VERSION "HNNBNNNYNNNNNNNNNNNNNNNNNNNNNNNNNNNNNNNNNN/4/%%%/4/'%**4NNN///"

NS_ :

BS_:

BU_: Airbag_D4 EPB_D4 ESP_D4 Gateway_D4C7 Getriebe_AL551_951_D4_C7 Getriebe_DL501_C7 Getriebe_VL381_C7 LWS_D4 Motor_EDC17_D4 Motor_ME17_BY Motor_MED17_SIMOS8_D4 Motor_Slave_D4 QSP_D4 SAK_C7 SCR_C7 SCU_D4

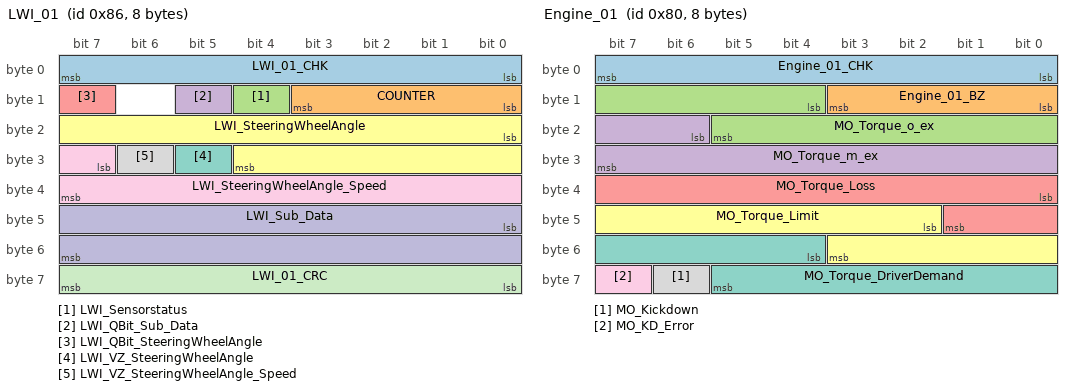
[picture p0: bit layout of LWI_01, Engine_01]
BO_ 134 LWI_01: 8 LWS_D4
 SG_ LWI_01_CHK : 0|8@1+ (1,0) [0|255] ""  ESP_D4,Gateway_D4C7,Getriebe_AL551_951_D4_C7,Getriebe_DL501_C7,Getriebe_VL381_C7,Motor_EDC17_D4,Motor_ME17_BY,Motor_MED17_SIMOS8_D4,QSP_D4,SCU_D4
 SG_ COUNTER : 8|4@1+ (1,0) [0|15] ""  Airbag_D4,ESP_D4,Gateway_D4C7,Getriebe_AL551_951_D4_C7,Getriebe_DL501_C7,Getriebe_VL381_C7,Motor_EDC17_D4,Motor_ME17_BY,Motor_MED17_SIMOS8_D4,QSP_D4,SCU_D4
 SG_ LWI_Sensorstatus : 12|1@1+ (1.0,0.0) [0.0|1] ""  ESP_D4,Gateway_D4C7,Getriebe_AL551_951_D4_C7,Motor_EDC17_D4,Motor_ME17_BY,Motor_MED17_SIMOS8_D4,QSP_D4,SCU_D4
 SG_ LWI_QBit_Sub_Data : 13|1@1+ (1.0,0.0) [0.0|1] ""  ESP_D4,Gateway_D4C7,QSP_D4,SCU_D4
 SG_ LWI_QBit_SteeringWheelAngle : 15|1@1+ (1.0,0.0) [0.0|1] ""  Airbag_D4,ESP_D4,Gateway_D4C7,Getriebe_AL551_951_D4_C7,Motor_EDC17_D4,Motor_ME17_BY,Motor_MED17_SIMOS8_D4,QSP_D4,SCU_D4
 SG_ LWI_SteeringWheelAngle : 16|13@1+ (0.1,0) [0.0|800.0] "Unit_DegreOfArc"  Airbag_D4,ESP_D4,Gateway_D4C7,Getriebe_AL551_951_D4_C7,Getriebe_DL501_C7,Getriebe_VL381_C7,Motor_EDC17_D4,Motor_ME17_BY,Motor_MED17_SIMOS8_D4,QSP_D4,SCU_D4
 SG_ LWI_VZ_SteeringWheelAngle : 29|1@1+ (1.0,0.0) [0.0|1] ""  Airbag_D4,ESP_D4,Gateway_D4C7,Getriebe_AL551_951_D4_C7,Motor_EDC17_D4,Motor_ME17_BY,Motor_MED17_SIMOS8_D4,QSP_D4,SCU_D4
 SG_ LWI_VZ_SteeringWheelAngle_Speed : 30|1@1+ (1.0,0.0) [0.0|1] ""  Gateway_D4C7,QSP_D4
 SG_ LWI_SteeringWheelAngle_Speed : 31|9@1+ (5,0) [0|2500] "Unit_DegreOfArcPerSecon"  Gateway_D4C7,QSP_D4
 SG_ LWI_Sub_Data : 40|16@1+ (1,0) [0|65535] ""  ESP_D4,Gateway_D4C7,QSP_D4,SCU_D4
 SG_ LWI_01_CRC : 56|8@1+ (1,0) [0|255] ""  Airbag_D4,ESP_D4,Gateway_D4C7,QSP_D4,SCU_D4

BO_ 128 Engine_01: 8 Motor_EDC17_D4
 SG_ Engine_01_CHK : 0|8@1+ (1,0) [0|255] ""  EPB_D4,Gateway_D4C7,Getriebe_AL551_951_D4_C7,Getriebe_DL501_C7,Getriebe_VL381_C7
 SG_ Engine_01_BZ : 8|4@1+ (1,0) [0|15] ""  EPB_D4,Gateway_D4C7,Getriebe_AL551_951_D4_C7,Getriebe_DL501_C7,Getriebe_VL381_C7
 SG_ MO_Torque_o_ex : 12|10@1+ (1,0) [0|1021] ""  Gateway_D4C7,Getriebe_AL551_951_D4_C7,Getriebe_DL501_C7,Getriebe_VL381_C7
 SG_ MO_Torque_m_ex : 22|10@1+ (1,0) [0|1021] ""  EPB_D4,Gateway_D4C7,Getriebe_AL551_951_D4_C7,Getriebe_DL501_C7,Getriebe_VL381_C7,SAK_C7
 SG_ MO_Torque_Loss : 32|10@1+ (1,0) [0|1021] ""  EPB_D4,Gateway_D4C7,Getriebe_AL551_951_D4_C7,Getriebe_DL501_C7,Getriebe_VL381_C7,SAK_C7
 SG_ MO_Torque_Limit : 42|10@1+ (1,0) [0|1021] ""  Gateway_D4C7,Getriebe_AL551_951_D4_C7,Getriebe_DL501_C7,Getriebe_VL381_C7
 SG_ MO_Torque_DriverDemand : 52|10@1+ (1,0) [0|1021] ""  Gateway_D4C7,Getriebe_AL551_951_D4_C7,Getriebe_DL501_C7,Getriebe_VL381_C7
 SG_ MO_Kickdown : 62|1@1+ (1.0,0.0) [0.0|1] ""  Gateway_D4C7,Getriebe_AL551_951_D4_C7,Getriebe_DL501_C7,Getriebe_VL381_C7
 SG_ MO_KD_Error : 63|1@1+ (1.0,0.0) [0.0|1] ""  Gateway_D4C7

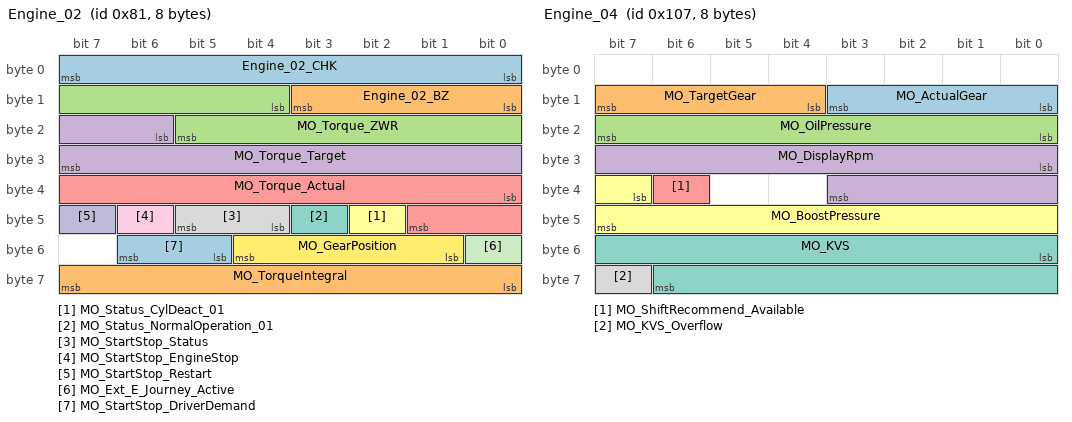
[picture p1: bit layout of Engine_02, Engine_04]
BO_ 129 Engine_02: 8 Motor_EDC17_D4
 SG_ Engine_02_CHK : 0|8@1+ (1,0) [0|255] ""  EPB_D4,Gateway_D4C7,Getriebe_AL551_951_D4_C7,Getriebe_DL501_C7,Getriebe_VL381_C7,SCU_D4
 SG_ Engine_02_BZ : 8|4@1+ (1,0) [0|15] ""  EPB_D4,Gateway_D4C7,Getriebe_AL551_951_D4_C7,Getriebe_DL501_C7,Getriebe_VL381_C7,SCU_D4
 SG_ MO_Torque_ZWR : 12|10@1+ (1,0) [0|1021] ""  Gateway_D4C7
 SG_ MO_Torque_Target : 22|10@1+ (1,0) [0|1021] ""  Gateway_D4C7,Getriebe_AL551_951_D4_C7,Getriebe_DL501_C7,Getriebe_VL381_C7
 SG_ MO_Torque_Actual : 32|10@1+ (1,0) [0|1021] ""  Gateway_D4C7,Getriebe_AL551_951_D4_C7,Getriebe_DL501_C7,Getriebe_VL381_C7
 SG_ MO_Status_CylDeact_01 : 42|1@1+ (1.0,0.0) [0.0|1] ""  Gateway_D4C7,Getriebe_AL551_951_D4_C7
 SG_ MO_Status_NormalOperation_01 : 43|1@1+ (1.0,0.0) [0.0|1] ""  Gateway_D4C7,Getriebe_DL501_C7,Getriebe_VL381_C7
 SG_ MO_StartStop_Status : 44|2@1+ (1.0,0.0) [0.0|3] ""  Gateway_D4C7,Getriebe_AL551_951_D4_C7,Getriebe_DL501_C7,Getriebe_VL381_C7,SCR_C7,SCU_D4
 SG_ MO_StartStop_EngineStop : 46|1@1+ (1.0,0.0) [0.0|1] ""  EPB_D4,Gateway_D4C7,Getriebe_AL551_951_D4_C7,Getriebe_DL501_C7,Getriebe_VL381_C7,SCR_C7,SCU_D4
 SG_ MO_StartStop_Restart : 47|1@1+ (1.0,0.0) [0.0|1] ""  EPB_D4,Gateway_D4C7,Getriebe_AL551_951_D4_C7,Getriebe_DL501_C7,Getriebe_VL381_C7,SCR_C7,SCU_D4
 SG_ MO_Ext_E_Journey_Active : 48|1@1+ (1.0,0.0) [0.0|1] ""  Gateway_D4C7
 SG_ MO_GearPosition : 49|4@1+ (1.0,0.0) [0.0|15] ""  Gateway_D4C7
 SG_ MO_StartStop_DriverDemand : 53|2@1+ (1.0,0.0) [0.0|3] ""  Gateway_D4C7
 SG_ MO_TorqueIntegral : 56|8@1+ (0.3921,0) [0.0000|99.9855] ""  Gateway_D4C7,Getriebe_AL551_951_D4_C7,Getriebe_DL501_C7,Getriebe_VL381_C7

BO_ 261 Engine_03: 8 Motor_EDC17_D4
 SG_ Engine_03_CHK : 0|8@1+ (1,0) [0|255] ""  EPB_D4,Gateway_D4C7,Getriebe_AL551_951_D4_C7,Getriebe_DL501_C7,Getriebe_VL381_C7,SCU_D4
 SG_ COUNTER : 8|4@1+ (1,0) [0|15] ""  EPB_D4,Gateway_D4C7,Getriebe_AL551_951_D4_C7,Getriebe_DL501_C7,Getriebe_VL381_C7,SCU_D4
 SG_ MO_QBit_AccelPedalValues_01 : 12|1@1+ (1.0,0.0) [0.0|1] ""  EPB_D4,Gateway_D4C7,Getriebe_AL551_951_D4_C7,Getriebe_DL501_C7,Getriebe_VL381_C7
 SG_ MO_QBit_EngineTorques : 13|1@1+ (1.0,0.0) [0.0|1] ""  EPB_D4,Gateway_D4C7,Getriebe_AL551_951_D4_C7,Getriebe_DL501_C7,Getriebe_VL381_C7
 SG_ MO_QBit_Driver_Brakes : 14|1@1+ (1.0,0.0) [0.0|1] ""  Gateway_D4C7,Getriebe_AL551_951_D4_C7,Getriebe_DL501_C7,Getriebe_VL381_C7
 SG_ MO_QBit_Rpm_01 : 15|1@1+ (1.0,0.0) [0.0|1] ""  EPB_D4,Gateway_D4C7,Getriebe_AL551_951_D4_C7,Getriebe_DL501_C7,Getriebe_VL381_C7,SCR_C7
 SG_ MO_Rpm_01 : 16|16@1+ (0.25,0) [0.00|16383.00] "Unit_MinutInver"  EPB_D4,Gateway_D4C7,Getriebe_AL551_951_D4_C7,Getriebe_DL501_C7,Getriebe_VL381_C7,SAK_C7,SCR_C7,SCU_D4
 SG_ MO_Torque_In_Idle : 32|1@1+ (1.0,0.0) [0.0|1] ""  Gateway_D4C7
 SG_ MO_Interlock : 33|1@1+ (1.0,0.0) [0.0|1] ""  EPB_D4,Gateway_D4C7
 SG_ MO_BLS : 34|1@1+ (1.0,0.0) [0.0|1] ""  EPB_D4,Gateway_D4C7,Getriebe_AL551_951_D4_C7,Getriebe_DL501_C7,Getriebe_VL381_C7
 SG_ MO_Driver_Brakes : 35|1@1+ (1.0,0.0) [0.0|1] ""  Gateway_D4C7,Getriebe_AL551_951_D4_C7,Getriebe_DL501_C7,Getriebe_VL381_C7
 SG_ MO_Consistency_BrakePedal : 36|1@1+ (1.0,0.0) [0.0|1] ""  Gateway_D4C7,Getriebe_AL551_951_D4_C7,Getriebe_DL501_C7,Getriebe_VL381_C7
 SG_ MO_Clutch_Switch : 37|1@1+ (1.0,0.0) [0.0|1] ""  EPB_D4,Gateway_D4C7
 SG_ MO_Timeout_ESP : 38|1@1+ (1.0,0.0) [0.0|1] ""  Gateway_D4C7
 SG_ MO_Engine_Running : 39|1@1+ (1.0,0.0) [0.0|1] ""  Gateway_D4C7
 SG_ MO_TargetRpm_Idle : 40|8@1+ (10,0) [0|2540] "Unit_MinutInver"  Gateway_D4C7,Getriebe_AL551_951_D4_C7,Getriebe_DL501_C7,Getriebe_VL381_C7
 SG_ MO_AccelPedalRaw_01 : 48|8@1+ (0.4,0) [0.0|101.6] "Unit_PerCent"  EPB_D4,Gateway_D4C7,Getriebe_AL551_951_D4_C7,Getriebe_DL501_C7,Getriebe_VL381_C7
 SG_ MO_First_InaccurateThreshold : 56|1@1+ (1.0,0.0) [0.0|1] ""  Gateway_D4C7,Getriebe_AL551_951_D4_C7,Getriebe_DL501_C7,Getriebe_VL381_C7
 SG_ MO_QBit_Stressfaktor : 57|1@1+ (1.0,0.0) [0.0|1] ""  Gateway_D4C7,Getriebe_AL551_951_D4_C7,Getriebe_DL501_C7,Getriebe_VL381_C7
 SG_ MO_Stressfaktor : 58|6@1+ (1.6,0) [0.0|100.8] "Unit_PerCent"  Gateway_D4C7,Getriebe_AL551_951_D4_C7,Getriebe_DL501_C7,Getriebe_VL381_C7

BO_ 263 Engine_04: 8 Motor_EDC17_D4
 SG_ MO_ActualGear : 8|4@1+ (1.0,0.0) [0.0|15] ""  Gateway_D4C7
 SG_ MO_TargetGear : 12|4@1+ (1.0,0.0) [0.0|15] ""  Gateway_D4C7
 SG_ MO_OilPressure : 16|8@1+ (0.04,0) [0.00|10.00] "Unit_Bar"  Gateway_D4C7
 SG_ MO_DisplayRpm : 24|12@1+ (3,0) [0|12282] "Unit_MinutInver"  Gateway_D4C7
 SG_ MO_ShiftRecommend_Available : 38|1@1+ (1.0,0.0) [0.0|1] ""  Gateway_D4C7
 SG_ MO_BoostPressure : 39|9@1+ (0.01,0) [0.00|5.10] "Unit_Bar"  Gateway_D4C7
 SG_ MO_KVS : 48|15@1+ (1,0) [0|32767] "Unit_MicroLiter"  Gateway_D4C7
 SG_ MO_KVS_Overflow : 63|1@1+ (1.0,0.0) [0.0|1] ""  Gateway_D4C7

BO_ 782 Engine_05: 8 Motor_EDC17_D4
 SG_ Engine_05_CHK : 0|8@1+ (1,0) [0|255] ""  Gateway_D4C7,Getriebe_AL551_951_D4_C7,Getriebe_DL501_C7,Getriebe_VL381_C7
 SG_ Engine_05_BZ : 8|4@1+ (1,0) [0|15] ""  Gateway_D4C7,Getriebe_AL551_951_D4_C7,Getriebe_DL501_C7,Getriebe_VL381_C7
 SG_ MO_ETermCommLeiRed : 12|2@1+ (1.0,0.0) [0.0|3] ""  Gateway_D4C7
 SG_ MO_Enable_Recup : 14|2@1+ (1.0,0.0) [0.0|3] ""  Gateway_D4C7
 SG_ MO_Climate_Interv : 16|2@1+ (1.0,0.0) [0.0|3] ""  Gateway_D4C7
 SG_ MO_Status_NormalOperation_02 : 18|1@1+ (1.0,0.0) [0.0|1] ""  Gateway_D4C7
 SG_ MO_ShiftInfluence_PowerLimit : 19|1@1+ (1,0) [0|1] ""  Gateway_D4C7,Getriebe_AL551_951_D4_C7,Getriebe_DL501_C7
 SG_ MO_ShiftInfluence_ParticleFilter : 20|1@1+ (1,0) [0|1] ""  Gateway_D4C7,Getriebe_AL551_951_D4_C7,Getriebe_DL501_C7
 SG_ MO_Prio_MIN_RequestedRpm : 21|1@1+ (1.0,0.0) [0.0|1] ""  Gateway_D4C7,Getriebe_AL551_951_D4_C7,Getriebe_DL501_C7,Getriebe_VL381_C7
 SG_ MO_Enable_Crank : 22|1@1+ (1.0,0.0) [0.0|1] ""  Gateway_D4C7
 SG_ MO_Aussp_Crank : 23|1@1+ (1.0,0.0) [0.0|1] ""  Gateway_D4C7
 SG_ MO_MAX_RequestedRpm : 24|9@1+ (25,0) [0|12750] "Unit_MinutInver"  Gateway_D4C7,Getriebe_AL551_951_D4_C7,Getriebe_DL501_C7,Getriebe_VL381_C7
 SG_ MO_Prio_MAX_RequestedRpm : 33|1@1+ (1.0,0.0) [0.0|1] ""  Gateway_D4C7,Getriebe_AL551_951_D4_C7,Getriebe_DL501_C7,Getriebe_VL381_C7
 SG_ MO_AirPath_Active : 34|1@1+ (1.0,0.0) [0.0|1] ""  Gateway_D4C7,Getriebe_AL551_951_D4_C7,Getriebe_DL501_C7
 SG_ MO_v_Limit_Active : 35|1@1+ (1.0,0.0) [0.0|1] ""  Gateway_D4C7
 SG_ MO_v_Limit_Activatable : 36|1@1+ (1.0,0.0) [0.0|1] ""  Gateway_D4C7
 SG_ MO_Inhibit_EKP : 37|1@1+ (1.0,0.0) [0.0|1] ""  Gateway_D4C7
 SG_ MO_Req_Pruefimpuls : 38|1@1+ (1.0,0.0) [0.0|1] ""  Gateway_D4C7
 SG_ MO_Req_TERM75 : 39|1@1+ (1.0,0.0) [0.0|1] ""  Gateway_D4C7
 SG_ MO_Charisma_DrivePr : 40|3@1+ (1.0,0.0) [0.0|7] ""  Gateway_D4C7
 SG_ MO_Charisma_Status : 43|2@1+ (1.0,0.0) [0.0|3] ""  Gateway_D4C7
 SG_ MO_Charisma_Changeover : 45|2@1+ (1.0,0.0) [0.0|3] ""  Gateway_D4C7
 SG_ MO_Handshake_STH : 47|1@1+ (1.0,0.0) [0.0|1] ""  Gateway_D4C7
 SG_ MO_MIN_RequestedRpm : 48|8@1+ (25,0) [0|6350] "Unit_MinutInver"  Gateway_D4C7,Getriebe_AL551_951_D4_C7,Getriebe_DL501_C7,Getriebe_VL381_C7
 SG_ MO_RpmInfluence : 56|8@1+ (0.39,0) [0.00|99.45] "Unit_PerCent"  Gateway_D4C7,Getriebe_AL551_951_D4_C7,Getriebe_DL501_C7,Getriebe_VL381_C7

BO_ 1088 Engine_06: 8 Motor_EDC17_D4
 SG_ MO_RadiatorFan_MUX M  : 0|1@1+ (1.0,0.0) [0.0|1] ""  Gateway_D4C7
 SG_ MO_RadiatorFan_1 m0  : 1|7@1+ (1,0) [0|100] "Unit_PerCent"  Gateway_D4C7
 SG_ MO_RadiatorFan_2 m1  : 1|7@1+ (1,0) [0|100] "Unit_PerCent"  Gateway_D4C7
 SG_ MO_HYB_Status_HV_Charge : 8|3@1+ (1.0,0.0) [0.0|7] ""  Gateway_D4C7
 SG_ WIV_Display_Active : 12|1@1+ (1.0,0.0) [0.0|1] ""  Gateway_D4C7
 SG_ WIV_Oelmin_Warn : 13|1@1+ (1.0,0.0) [0.0|1] ""  Gateway_D4C7
 SG_ WIV_SensorError : 14|1@1+ (1.0,0.0) [0.0|1] ""  Gateway_D4C7
 SG_ WIV_Tilt : 15|1@1+ (1.0,0.0) [0.0|1] ""  Gateway_D4C7
 SG_ WIV_OilLevel : 16|4@1+ (12.5,0) [0.0|100.0] "Unit_PerCent"  Gateway_D4C7
 SG_ MO_State_HWP : 20|2@1+ (1.0,0.0) [0.0|3] ""  Gateway_D4C7
 SG_ WIV_OilSystem_Active : 24|1@1+ (1.0,0.0) [0.0|1] ""  Gateway_D4C7
 SG_ WIV_Not_AtOperatingTemp : 25|1@1+ (1.0,0.0) [0.0|1] ""  Gateway_D4C7
 SG_ WIV_Overfill_Warn : 26|1@1+ (1.0,0.0) [0.0|1] ""  Gateway_D4C7
 SG_ WIV_Running_Engine : 27|1@1+ (1.0,0.0) [0.0|1] ""  Gateway_D4C7
 SG_ MO_HYB_Text_1 : 28|1@1+ (1.0,0.0) [0.0|1] ""  Gateway_D4C7
 SG_ MO_HYB_Text_2 : 29|1@1+ (1.0,0.0) [0.0|1] ""  Gateway_D4C7
 SG_ MO_HYB_Text_3 : 30|1@1+ (1.0,0.0) [0.0|1] ""  Gateway_D4C7
 SG_ MO_Text_EngineStart : 32|4@1+ (1.0,0.0) [0.0|15] ""  Gateway_D4C7
 SG_ MO_HYB_Text_5 : 36|1@1+ (1.0,0.0) [0.0|1] ""  Gateway_D4C7
 SG_ MO_HYB_Text_6 : 37|1@1+ (1.0,0.0) [0.0|1] ""  Gateway_D4C7
 SG_ MO_HYB_Text_7 : 38|1@1+ (1.0,0.0) [0.0|1] ""  Gateway_D4C7
 SG_ WIV_OilDyn_avl : 39|1@1+ (1.0,0.0) [0.0|1] ""  Gateway_D4C7
 SG_ MO_Text_MSG_Workshop : 40|1@1+ (1,0) [0|1] ""  Gateway_D4C7
 SG_ MO_Text_ParticleFilter_Reg : 41|1@1+ (1,0) [0|1] ""  Gateway_D4C7
 SG_ MO_Text_Error_Kraftstoffsys : 42|1@1+ (1,0) [0|1] ""  Gateway_D4C7
 SG_ WIV_OilQuantity : 43|5@1+ (125,0) [0|3875] "Unit_MilliLiter"  Gateway_D4C7
 SG_ MO_SystemLamp : 48|1@1+ (1.0,0.0) [0.0|1] ""  Gateway_D4C7
 SG_ MO_OBD2_Lamp : 49|1@1+ (1.0,0.0) [0.0|1] ""  Gateway_D4C7
 SG_ MO_HotWarningLamp : 50|1@1+ (1.0,0.0) [0.0|1] ""  Gateway_D4C7
 SG_ MO_Particle_Lamp : 51|1@1+ (1.0,0.0) [0.0|1] ""  Gateway_D4C7
 SG_ MO_WinterProgram : 52|1@1+ (1,0) [0|1] ""  Gateway_D4C7
 SG_ WIV_OilLevel_Not_Present : 53|1@1+ (1.0,0.0) [0.0|1] ""  Gateway_D4C7
 SG_ WIV_RefillDisplay_On : 54|1@1+ (1.0,0.0) [0.0|1] ""  Gateway_D4C7
 SG_ WIV_Overfill_Deactivated : 55|1@1+ (1.0,0.0) [0.0|1] ""  Gateway_D4C7
 SG_ WIV_Underfill_Warn : 56|1@1+ (1.0,0.0) [0.0|1] ""  Gateway_D4C7
 SG_ MO_FuelCap_Lamp : 57|1@1+ (1.0,0.0) [0.0|1] ""  Gateway_D4C7
 SG_ MO_Text_FuelCapWarn : 58|1@1+ (1.0,0.0) [0.0|1] ""  Gateway_D4C7
 SG_ WIV_Enable_OilPressure_Engine : 59|1@1+ (1.0,0.0) [0.0|1] ""  Gateway_D4C7
 SG_ WIV_OilPressure_Warn_Engine : 60|1@1+ (1.0,0.0) [0.0|1] ""  Gateway_D4C7
 SG_ MO_Avus_EngineProtection : 61|2@1+ (1.0,0.0) [0.0|3] ""  Gateway_D4C7
 SG_ MO_HYB_ReadyToDrive : 63|1@1+ (1.0,0.0) [0.0|1] ""  Gateway_D4C7

BO_ 1600 Engine_07: 8 Motor_EDC17_D4
 SG_ MO_QBit_IntakeAir_Temp : 0|1@1+ (1.0,0.0) [0.0|1] ""  Gateway_D4C7,Getriebe_AL551_951_D4_C7,Getriebe_DL501_C7,Getriebe_VL381_C7
 SG_ MO_QBit_Oil_Temp : 1|1@1+ (1.0,0.0) [0.0|1] ""  Gateway_D4C7,Getriebe_AL551_951_D4_C7
 SG_ MO_QBit_Coolant_Temp : 2|1@1+ (1.0,0.0) [0.0|1] ""  Gateway_D4C7,Getriebe_AL551_951_D4_C7,Getriebe_DL501_C7,Getriebe_VL381_C7
 SG_ MO_ActuatorTest_SoundActuator : 3|1@1+ (1.0,0.0) [0.0|1] ""  Gateway_D4C7
 SG_ MO_HYB_Error_HV_Network : 4|1@1+ (1.0,0.0) [0.0|1] ""  Gateway_D4C7
 SG_ MO_Active_GearboxHeat : 5|1@1+ (1.0,0.0) [0.0|1] ""  Gateway_D4C7,Getriebe_AL551_951_D4_C7,Getriebe_DL501_C7,Getriebe_VL381_C7
 SG_ MO_ShutOffValve_Open : 6|2@1+ (1.0,0.0) [0.0|3] ""  Gateway_D4C7
 SG_ MO_IntakeAir_Temp : 8|8@1+ (0.75,-48) [-48.00|141.75] "Unit_DegreCelsi"  Gateway_D4C7,Getriebe_AL551_951_D4_C7,Getriebe_DL501_C7,Getriebe_VL381_C7
 SG_ MO_Oil_Temp : 16|8@1+ (1,-60) [-60|192] "Unit_DegreCelsi"  Gateway_D4C7,Getriebe_AL551_951_D4_C7
 SG_ MO_Coolant_Temp : 24|8@1+ (0.75,-48) [-48.00|141.75] "Unit_DegreCelsi"  Gateway_D4C7,Getriebe_AL551_951_D4_C7,Getriebe_DL501_C7,Getriebe_VL381_C7
 SG_ MO_AltitudeInfo : 32|8@1+ (0.00781,0) [0.00000|1.98374] ""  Gateway_D4C7,Getriebe_AL551_951_D4_C7,Getriebe_DL501_C7,Getriebe_VL381_C7
 SG_ MO_Kennfeldk : 40|1@1+ (1.0,0.0) [0.0|1] ""  Gateway_D4C7
 SG_ MO_VersionInfo : 41|6@1+ (1.0,0.0) [0.0|63] ""  Gateway_D4C7
 SG_ MO_Gearbox_Cool : 47|1@1+ (1.0,0.0) [0.0|1] ""  Gateway_D4C7,Getriebe_AL551_951_D4_C7,Getriebe_DL501_C7,Getriebe_VL381_C7
 SG_ MO_Torque_Inertia_02 : 48|5@1+ (0.01,0) [0.00|0.31] "Unit_KiloGramMeterSquar"  Gateway_D4C7,Getriebe_AL551_951_D4_C7,Getriebe_DL501_C7,Getriebe_VL381_C7
 SG_ MO_HeatingPumpActuation : 53|4@1+ (10,0) [0|100] "Unit_PerCent"  Gateway_D4C7
 SG_ MO_VoltageReq : 57|1@1+ (1.0,0.0) [0.0|1] ""  Gateway_D4C7
 SG_ MO_RunOnTime_HeatingPump : 58|6@1+ (15,0) [0|945] "Unit_Secon"  Gateway_D4C7

BO_ 1607 Engine_09: 8 Motor_EDC17_D4
 SG_ MO_ITM_Coolant_Temp : 0|8@1+ (0.75,-48) [-45.75|143.25] "Unit_DegreCelsi"  Gateway_D4C7
 SG_ MO_E85_Sensor : 8|4@1+ (10,0) [0|100] "Unit_PerCent"  Gateway_D4C7
 SG_ SCR_Disp_Motorstarts : 12|4@1+ (1,0) [0|8] ""  Gateway_D4C7
 SG_ SCR_Range : 16|15@1+ (1,0) [0|32766] ""  Gateway_D4C7
 SG_ SCR_WarningLevel_1 : 32|1@1+ (1.0,0.0) [0.0|1] ""  Gateway_D4C7
 SG_ SCR_WarningLevel_2 : 33|1@1+ (1.0,0.0) [0.0|1] ""  Gateway_D4C7
 SG_ SCR_Text : 34|3@1+ (1.0,0.0) [0.0|7] ""  Gateway_D4C7
 SG_ SCR_Acoustic : 37|2@1+ (1.0,0.0) [0.0|3] ""  Gateway_D4C7
 SG_ MO_Kraftstofffilter_Water : 40|1@1+ (1.0,0.0) [0.0|1] ""  Gateway_D4C7
 SG_ SCR_SystemError : 41|1@1+ (1.0,0.0) [0.0|1] ""  Gateway_D4C7
 SG_ SCR_Inducement_Strategy : 42|2@1+ (1.0,0.0) [0.0|3] ""  Gateway_D4C7
 SG_ MO_CO2_Factor : 44|12@1+ (1,0) [1|4094] "Unit_GramPerLiter"  Gateway_D4C7
 SG_ MO_MKB_MUX M  : 56|2@1+ (1.0,0.0) [0.0|3] ""  Gateway_D4C7
 SG_ MO_MKB_01 m0  : 59|5@1+ (1.0,0.0) [0.0|31] ""  Gateway_D4C7
 SG_ MO_MKB_02 m1  : 59|5@1+ (1.0,0.0) [0.0|31] ""  Gateway_D4C7
 SG_ MO_MKB_03 m2  : 59|5@1+ (1.0,0.0) [0.0|31] ""  Gateway_D4C7
 SG_ MO_MKB_04 m3  : 59|5@1+ (1.0,0.0) [0.0|31] ""  Gateway_D4C7

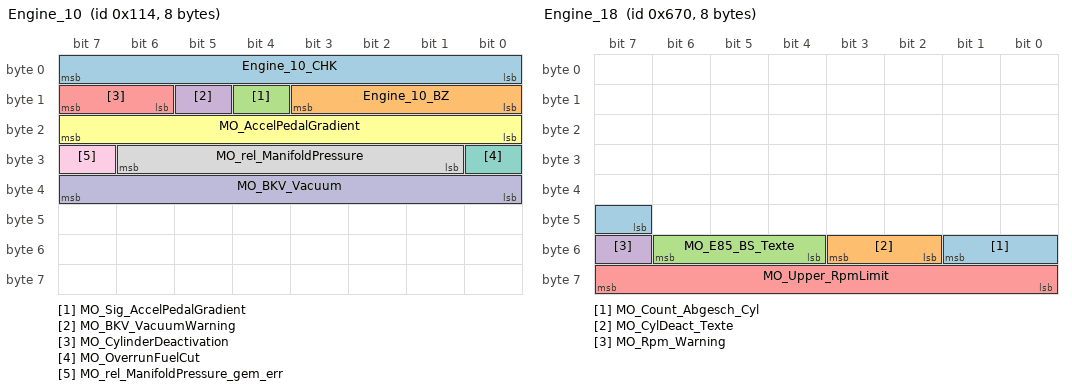
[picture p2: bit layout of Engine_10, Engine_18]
BO_ 276 Engine_10: 8 Motor_EDC17_D4
 SG_ Engine_10_CHK : 0|8@1+ (1,0) [0|255] ""  Gateway_D4C7
 SG_ Engine_10_BZ : 8|4@1+ (1,0) [0|15] ""  Gateway_D4C7
 SG_ MO_Sig_AccelPedalGradient : 12|1@1+ (1.0,0.0) [0.0|1] ""  Gateway_D4C7
 SG_ MO_BKV_VacuumWarning : 13|1@1+ (1.0,0.0) [0.0|1] ""  Gateway_D4C7
 SG_ MO_CylinderDeactivation : 14|2@1+ (1.0,0.0) [0.0|3] ""  Gateway_D4C7,Getriebe_AL551_951_D4_C7,Getriebe_DL501_C7
 SG_ MO_AccelPedalGradient : 16|8@1+ (25,0) [0|6350] "Unit_PerCentPerSecon"  Gateway_D4C7
 SG_ MO_OverrunFuelCut : 24|1@1+ (1.0,0.0) [0.0|1] ""  Gateway_D4C7
 SG_ MO_rel_ManifoldPressure : 25|6@1+ (18,0) [0|1116] "Unit_MilliBar"  Gateway_D4C7
 SG_ MO_rel_ManifoldPressure_gem_err : 31|1@1+ (1.0,0.0) [0.0|1] ""  Gateway_D4C7
 SG_ MO_BKV_Vacuum : 32|8@1+ (4,0) [0|1012] "Unit_MilliBar"  Gateway_D4C7

BO_ 1648 Engine_18: 8 Motor_EDC17_D4
 SG_ MO_Count_Abgesch_Cyl : 47|3@1+ (1.0,0.0) [0.0|7] ""  Gateway_D4C7,Getriebe_AL551_951_D4_C7,Getriebe_DL501_C7
 SG_ MO_CylDeact_Texte : 50|2@1+ (1.0,0.0) [0.0|3] ""  Gateway_D4C7
 SG_ MO_E85_BS_Texte : 52|3@1+ (1.0,0.0) [0.0|7] ""  Gateway_D4C7
 SG_ MO_Rpm_Warning : 55|1@1+ (1.0,0.0) [0.0|1] ""  Gateway_D4C7
 SG_ MO_Upper_RpmLimit : 56|8@1+ (50,0) [50|12750] "Unit_MinutInver"  Gateway_D4C7

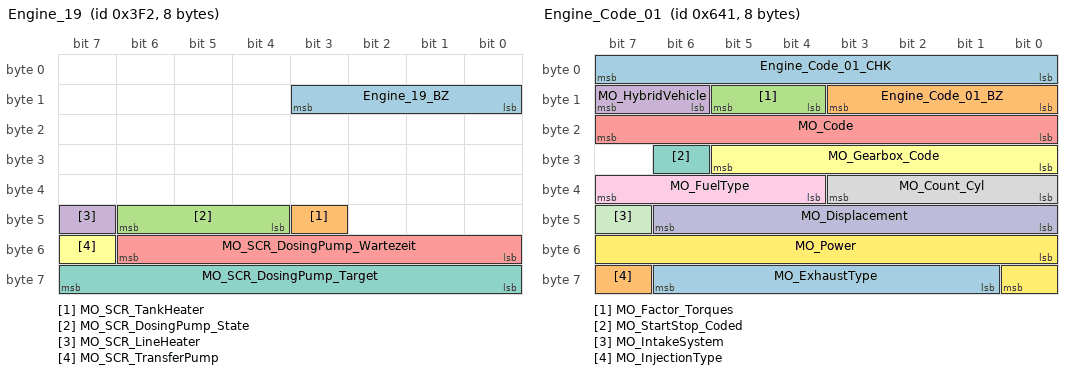
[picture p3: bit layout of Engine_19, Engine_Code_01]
BO_ 1010 Engine_19: 8 Motor_EDC17_D4
 SG_ Engine_19_BZ : 8|4@1+ (1,0) [0|15] ""  SCR_C7
 SG_ MO_SCR_TankHeater : 43|1@1+ (1.0,0.0) [0.0|1] ""  SCR_C7
 SG_ MO_SCR_DosingPump_State : 44|3@1+ (1.0,0.0) [0.0|7] ""  SCR_C7
 SG_ MO_SCR_LineHeater : 47|1@1+ (1.0,0.0) [0.0|1] ""  SCR_C7
 SG_ MO_SCR_DosingPump_Wartezeit : 48|7@1+ (1,0) [0|120] "Unit_Secon"  SCR_C7
 SG_ MO_SCR_TransferPump : 55|1@1+ (1.0,0.0) [0.0|1] ""  SCR_C7
 SG_ MO_SCR_DosingPump_Target : 56|8@1+ (0.4,0) [0.0|100.0] "Unit_PerCent"  SCR_C7

BO_ 1601 Engine_Code_01: 8 Motor_EDC17_D4
 SG_ Engine_Code_01_CHK : 0|8@1+ (1,0) [0|255] ""  Gateway_D4C7,Getriebe_AL551_951_D4_C7,Getriebe_DL501_C7,Getriebe_VL381_C7
 SG_ Engine_Code_01_BZ : 8|4@1+ (1,0) [0|15] ""  Gateway_D4C7,Getriebe_AL551_951_D4_C7,Getriebe_DL501_C7,Getriebe_VL381_C7
 SG_ MO_Factor_Torques : 12|2@1+ (1.0,0.0) [0.0|3] ""  EPB_D4,Gateway_D4C7,Getriebe_AL551_951_D4_C7,Getriebe_DL501_C7,Getriebe_VL381_C7
 SG_ MO_HybridVehicle : 14|2@1+ (1.0,0.0) [0.0|3] ""  Gateway_D4C7
 SG_ MO_Code : 16|8@1+ (1,0) [0|255] ""  EPB_D4,Gateway_D4C7,Getriebe_AL551_951_D4_C7,Getriebe_DL501_C7,Getriebe_VL381_C7,SAK_C7
 SG_ MO_Gearbox_Code : 24|6@1+ (1.0,0.0) [0.0|63] ""  EPB_D4,Gateway_D4C7,Getriebe_AL551_951_D4_C7,Getriebe_DL501_C7,Getriebe_VL381_C7
 SG_ MO_StartStop_Coded : 30|1@1+ (1.0,0.0) [0.0|1] ""  Gateway_D4C7
 SG_ MO_Count_Cyl : 32|4@1+ (1,0) [0|15] ""  Gateway_D4C7
 SG_ MO_FuelType : 36|4@1+ (1.0,0.0) [0.0|15] ""  EPB_D4,Gateway_D4C7
 SG_ MO_Displacement : 40|7@1+ (0.1,0) [0.0|12.7] "Unit_Liter"  Gateway_D4C7
 SG_ MO_IntakeSystem : 47|1@1+ (1.0,0.0) [0.0|1] ""  EPB_D4,Gateway_D4C7
 SG_ MO_Power : 48|9@1+ (1,0) [0|511] "Unit_KiloWatt"  Gateway_D4C7
 SG_ MO_ExhaustType : 57|6@1+ (1.0,0.0) [0.0|63] ""  Gateway_D4C7,Getriebe_AL551_951_D4_C7
 SG_ MO_InjectionType : 63|1@1+ (1.0,0.0) [0.0|1] ""  Gateway_D4C7

BO_ 969 EngineSlave_01: 1 Motor_Slave_D4
 SG_ MOS_KD_Error : 0|1@1+ (1.0,0.0) [0.0|1] ""  Gateway_D4C7

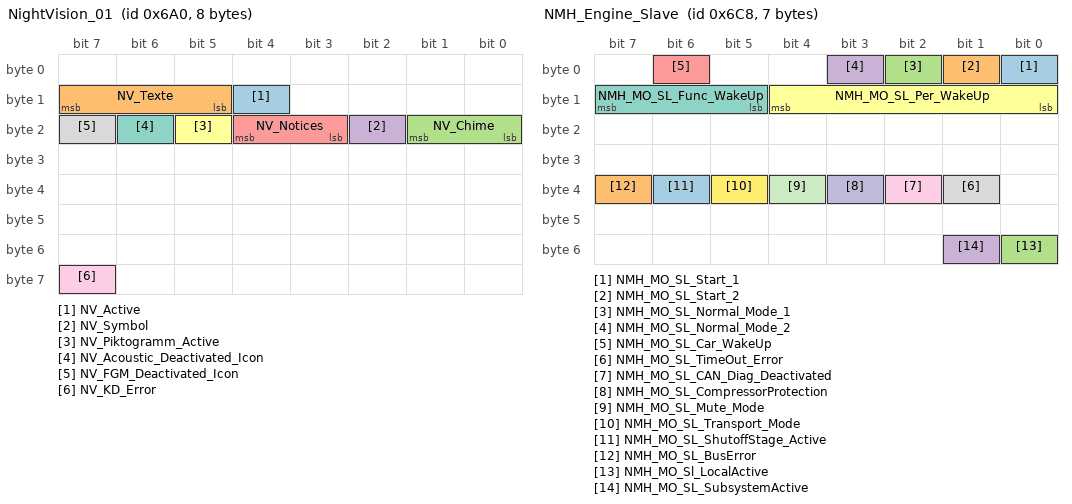
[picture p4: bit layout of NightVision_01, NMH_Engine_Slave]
BO_ 1696 NightVision_01: 8 Gateway_D4C7
 SG_ NV_Active : 12|1@1+ (1.0,0.0) [0.0|1] ""  Airbag_D4
 SG_ NV_Texte : 13|3@1+ (1.0,0.0) [0.0|7] ""  Vector__XXX
 SG_ NV_Chime : 16|2@1+ (1.0,0.0) [0.0|3] ""  Airbag_D4
 SG_ NV_Symbol : 18|1@1+ (1.0,0.0) [0.0|1] ""  Airbag_D4
 SG_ NV_Notices : 19|2@1+ (1.0,0.0) [0.0|3] ""  Vector__XXX
 SG_ NV_Piktogramm_Active : 21|1@1+ (1.0,0.0) [0.0|1] ""  Vector__XXX
 SG_ NV_Acoustic_Deactivated_Icon : 22|1@1+ (1.0,0.0) [0.0|1] ""  Vector__XXX
 SG_ NV_FGM_Deactivated_Icon : 23|1@1+ (1.0,0.0) [0.0|1] ""  Vector__XXX
 SG_ NV_KD_Error : 63|1@1+ (1.0,0.0) [0.0|1] ""  Vector__XXX

BO_ 1753 NMH_EPB: 7 EPB_D4
 SG_ NMH_EPB_Start_1 : 0|1@1+ (1.0,0.0) [0.0|1] ""  EPB_D4,Gateway_D4C7,Getriebe_AL551_951_D4_C7,Getriebe_DL501_C7,Getriebe_VL381_C7,Motor_EDC17_D4,Motor_ME17_BY,Motor_MED17_SIMOS8_D4,Motor_Slave_D4,SCR_C7
 SG_ NMH_EPB_Start_2 : 1|1@1+ (1.0,0.0) [0.0|1] ""  Vector__XXX
 SG_ NMH_EPB_Normal_Mode_1 : 2|1@1+ (1.0,0.0) [0.0|1] ""  Vector__XXX
 SG_ NMH_EPB_Normal_Mode_2 : 3|1@1+ (1.0,0.0) [0.0|1] ""  Vector__XXX
 SG_ NMH_EPB_Car_WakeUp : 6|1@1+ (1.0,0.0) [0.0|1] ""  Vector__XXX
 SG_ NMH_EPB_Per_WakeUp : 8|5@1+ (1.0,0.0) [0.0|31] ""  Vector__XXX
 SG_ NMH_EPB_Func_WakeUp : 13|3@1+ (1.0,0.0) [0.0|7] ""  Vector__XXX
 SG_ NMH_EPB_NM_Active_Terminal_15 : 16|1@1+ (1.0,0.0) [0.0|1] ""  Vector__XXX
 SG_ NMH_EPB_NM_Active_Diagnostics : 17|1@1+ (1.0,0.0) [0.0|1] ""  Vector__XXX
 SG_ NMH_EPB_NM_Active_Start : 18|1@1+ (1.0,0.0) [0.0|1] ""  Vector__XXX
 SG_ NMH_EPB_NM_Active_Switch : 19|1@1+ (1.0,0.0) [0.0|1] ""  Vector__XXX
 SG_ NMH_EPB_NM_Active_Bedarf_Display : 20|1@1+ (1.0,0.0) [0.0|1] ""  Vector__XXX
 SG_ NMH_EPB_NM_Active_v_Greater_Null : 21|1@1+ (1.0,0.0) [0.0|1] ""  Vector__XXX
 SG_ NMH_EPB_No_NL : 24|1@1+ (1.0,0.0) [0.0|1] ""  Vector__XXX
 SG_ NMH_EPB_NL_Temp_Model : 25|1@1+ (1.0,0.0) [0.0|1] ""  Vector__XXX
 SG_ NMH_EPB_NL_Min : 26|1@1+ (1.0,0.0) [0.0|1] ""  Vector__XXX
 SG_ NMH_EPB_NL_AutoAdjust : 27|1@1+ (1.0,0.0) [0.0|1] ""  Vector__XXX
 SG_ NM_EPB_SignalError : 32|1@1+ (1.0,0.0) [0.0|1] ""  Vector__XXX
 SG_ NMH_EPB_TimeOut_Error : 33|1@1+ (1.0,0.0) [0.0|1] ""  Vector__XXX
 SG_ NMH_EPB_CAN_Diag_Deactivated : 34|1@1+ (1.0,0.0) [0.0|1] ""  Vector__XXX
 SG_ NMH_EPB_CompressorProtection : 35|1@1+ (1.0,0.0) [0.0|1] ""  Vector__XXX
 SG_ NMH_EPB_Mute_Mode : 36|1@1+ (1.0,0.0) [0.0|1] ""  Vector__XXX
 SG_ NMH_EPB_Transport_Mode : 37|1@1+ (1.0,0.0) [0.0|1] ""  Vector__XXX
 SG_ NMH_EPB_ShutoffStage_Active : 38|1@1+ (1.0,0.0) [0.0|1] ""  Vector__XXX
 SG_ NMH_EPB_SingleWire_Error : 39|1@1+ (1.0,0.0) [0.0|1] ""  Vector__XXX
 SG_ NMH_EPB_LocalActive : 48|1@1+ (1.0,0.0) [0.0|1] ""  Vector__XXX
 SG_ NMH_EPB_SubsystemActive : 49|1@1+ (1.0,0.0) [0.0|1] ""  Vector__XXX

BO_ 1728 NMH_Gateway: 7 Gateway_D4C7
 SG_ NMH_GW_Start_1 : 0|1@1+ (1.0,0.0) [0.0|1] ""  EPB_D4,Gateway_D4C7,Getriebe_AL551_951_D4_C7,Getriebe_DL501_C7,Getriebe_VL381_C7,Motor_EDC17_D4,Motor_ME17_BY,Motor_MED17_SIMOS8_D4,Motor_Slave_D4,SCR_C7
 SG_ NMH_GW_Start_2 : 1|1@1+ (1.0,0.0) [0.0|1] ""  EPB_D4,Gateway_D4C7,Getriebe_AL551_951_D4_C7,Getriebe_DL501_C7,Getriebe_VL381_C7,Motor_EDC17_D4,Motor_ME17_BY,Motor_MED17_SIMOS8_D4,Motor_Slave_D4,SCR_C7
 SG_ NMH_GW_Normal_Mode_1 : 2|1@1+ (1.0,0.0) [0.0|1] ""  EPB_D4,Gateway_D4C7,Getriebe_AL551_951_D4_C7,Getriebe_DL501_C7,Getriebe_VL381_C7,Motor_EDC17_D4,Motor_ME17_BY,Motor_MED17_SIMOS8_D4,Motor_Slave_D4,SCR_C7
 SG_ NMH_GW_Normal_Mode_2 : 3|1@1+ (1.0,0.0) [0.0|1] ""  EPB_D4,Gateway_D4C7,Getriebe_AL551_951_D4_C7,Getriebe_DL501_C7,Getriebe_VL381_C7,Motor_EDC17_D4,Motor_ME17_BY,Motor_MED17_SIMOS8_D4,Motor_Slave_D4,SCR_C7
 SG_ NMH_GW_Car_WakeUp : 6|1@1+ (1.0,0.0) [0.0|1] ""  Vector__XXX
 SG_ NMH_GW_Per_WakeUp : 8|5@1+ (1.0,0.0) [0.0|31] ""  Vector__XXX
 SG_ NMH_GW_Func_WakeUp : 13|3@1+ (1.0,0.0) [0.0|7] ""  Vector__XXX
 SG_ NMH_GW_NM_Active_Terminal_15 : 16|1@1+ (1.0,0.0) [0.0|1] ""  Vector__XXX
 SG_ NMH_GW_NM_Active_Diagnostics : 17|1@1+ (1.0,0.0) [0.0|1] ""  Vector__XXX
 SG_ NMH_GW_NM_Active_Start : 18|1@1+ (1.0,0.0) [0.0|1] ""  Vector__XXX
 SG_ NMH_GW_NM_Active_BDM : 19|1@1+ (1.0,0.0) [0.0|1] ""  Vector__XXX
 SG_ NMH_GW_NM_Active_HazardFlash : 20|1@1+ (1.0,0.0) [0.0|1] ""  Vector__XXX
 SG_ NMH_GW_NM_Active_ESP : 21|1@1+ (1.0,0.0) [0.0|1] ""  Vector__XXX
 SG_ NMH_GW_ShutoffStage_3 : 24|1@1+ (1.0,0.0) [0.0|1] ""  Vector__XXX
 SG_ NMH_GW_ECU_ErrorDuration : 25|1@1+ (1.0,0.0) [0.0|1] ""  Vector__XXX
 SG_ NMH_GW_STH_Wakeup : 26|1@1+ (1.0,0.0) [0.0|1] ""  Vector__XXX
 SG_ NMH_GW_NL_Diagnostics : 27|1@1+ (1.0,0.0) [0.0|1] ""  Vector__XXX
 SG_ NM_GW_SignalError : 32|1@1+ (1.0,0.0) [0.0|1] ""  Vector__XXX
 SG_ NMH_GW_TimeOut_Error : 33|1@1+ (1.0,0.0) [0.0|1] ""  Vector__XXX
 SG_ NMH_GW_CAN_Diag_Deactivated : 34|1@1+ (1.0,0.0) [0.0|1] ""  Vector__XXX
 SG_ NMH_GW_CompressorProtection : 35|1@1+ (1.0,0.0) [0.0|1] ""  Vector__XXX
 SG_ NMH_GW_Mute_Mode : 36|1@1+ (1.0,0.0) [0.0|1] ""  Vector__XXX
 SG_ NMH_GW_Transport_Mode : 37|1@1+ (1.0,0.0) [0.0|1] ""  Vector__XXX
 SG_ NMH_GW_ShutoffStage_Active : 38|1@1+ (1.0,0.0) [0.0|1] ""  Vector__XXX
 SG_ NMH_GW_SingleWire_Error : 39|1@1+ (1.0,0.0) [0.0|1] ""  Vector__XXX
 SG_ NMH_GW_ACAN : 40|1@1+ (1.0,0.0) [0.0|1] ""  Vector__XXX
 SG_ NMH_GW_ClusterCAN : 41|1@1+ (1.0,0.0) [0.0|1] ""  Vector__XXX
 SG_ NMH_GW_ComfortCAN : 42|1@1+ (1.0,0.0) [0.0|1] ""  Vector__XXX
 SG_ NMH_GW_Infotainment : 43|1@1+ (1.0,0.0) [0.0|1] ""  Vector__XXX
 SG_ NMH_GW_Chassis : 44|1@1+ (1.0,0.0) [0.0|1] ""  Vector__XXX
 SG_ NMH_GW_WakeUp_CAN_Bus : 45|3@1+ (1.0,0.0) [0.0|7] ""  Vector__XXX

BO_ 1730 NMH_Gearbox: 7 Getriebe_AL551_951_D4_C7
 SG_ NMH_GE_Start_1 : 0|1@1+ (1.0,0.0) [0.0|1] ""  EPB_D4,Gateway_D4C7,Getriebe_AL551_951_D4_C7,Getriebe_DL501_C7,Getriebe_VL381_C7,Motor_EDC17_D4,Motor_ME17_BY,Motor_MED17_SIMOS8_D4,Motor_Slave_D4,SCR_C7
 SG_ NMH_GE_Start_2 : 1|1@1+ (1.0,0.0) [0.0|1] ""  Vector__XXX
 SG_ NMH_GE_Normal_Mode_1 : 2|1@1+ (1.0,0.0) [0.0|1] ""  Vector__XXX
 SG_ NMH_GE_Normal_Mode_2 : 3|1@1+ (1.0,0.0) [0.0|1] ""  Vector__XXX
 SG_ NMH_GE_Car_WakeUp : 6|1@1+ (1.0,0.0) [0.0|1] ""  Vector__XXX
 SG_ NMH_GE_Per_WakeUp : 8|5@1+ (1.0,0.0) [0.0|31] ""  Vector__XXX
 SG_ NMH_GE_Func_WakeUp : 13|3@1+ (1.0,0.0) [0.0|7] ""  Vector__XXX
 SG_ NMH_GE_NM_Active_Terminal_15 : 16|1@1+ (1.0,0.0) [0.0|1] ""  Vector__XXX
 SG_ NMH_GE_NM_Active_Diagnostics : 17|1@1+ (1.0,0.0) [0.0|1] ""  Vector__XXX
 SG_ NMH_GE_NM_Active_Start : 18|1@1+ (1.0,0.0) [0.0|1] ""  Vector__XXX
 SG_ NMH_GE_N_HoldPhase : 19|1@1+ (1.0,0.0) [0.0|1] ""  Vector__XXX
 SG_ NMH_GE_No_NL : 24|1@1+ (1.0,0.0) [0.0|1] ""  Vector__XXX
 SG_ NMH_GE_NL_Data_EEPROM : 25|1@1+ (1.0,0.0) [0.0|1] ""  Vector__XXX
 SG_ NMH_GE_NL_Drucksens : 26|1@1+ (1.0,0.0) [0.0|1] ""  Vector__XXX
 SG_ NMH_GE_NL_Abtrieb : 27|1@1+ (1.0,0.0) [0.0|1] ""  Vector__XXX
 SG_ NMH_GE_NL_SelectorLever : 28|1@1+ (1.0,0.0) [0.0|1] ""  Vector__XXX
 SG_ NMH_GE_NL_Immobiliser : 29|1@1+ (1.0,0.0) [0.0|1] ""  Vector__XXX
 SG_ NM_GE_SignalError : 32|1@1+ (1.0,0.0) [0.0|1] ""  Vector__XXX
 SG_ NMH_GE_TimeOut_Error : 33|1@1+ (1.0,0.0) [0.0|1] ""  Vector__XXX
 SG_ NMH_GE_CAN_Diag_Deactivated : 34|1@1+ (1.0,0.0) [0.0|1] ""  Vector__XXX
 SG_ NMH_GE_CompressorProtection : 35|1@1+ (1.0,0.0) [0.0|1] ""  Vector__XXX
 SG_ NMH_GE_Mute_Mode : 36|1@1+ (1.0,0.0) [0.0|1] ""  Vector__XXX
 SG_ NMH_GE_Transport_Mode : 37|1@1+ (1.0,0.0) [0.0|1] ""  Vector__XXX
 SG_ NMH_GE_ShutoffStage_Active : 38|1@1+ (1.0,0.0) [0.0|1] ""  Vector__XXX
 SG_ NMH_GE_SingleWire_Error : 39|1@1+ (1.0,0.0) [0.0|1] ""  Vector__XXX
 SG_ NMH_GE_LocalActive : 48|1@1+ (1.0,0.0) [0.0|1] ""  Vector__XXX
 SG_ NMH_GE_SubsystemActive : 49|1@1+ (1.0,0.0) [0.0|1] ""  Vector__XXX
 SG_ NMH_GSG_Subbusaktiv : 50|1@1+ (1.0,0.0) [0.0|1] ""  Vector__XXX

BO_ 1729 NMH_Engine: 7 Motor_EDC17_D4
 SG_ NMH_MO_Start_1 : 0|1@1+ (1.0,0.0) [0.0|1] ""  EPB_D4,Gateway_D4C7,Getriebe_AL551_951_D4_C7,Getriebe_DL501_C7,Getriebe_VL381_C7,Motor_EDC17_D4,Motor_ME17_BY,Motor_MED17_SIMOS8_D4,Motor_Slave_D4,SCR_C7
 SG_ NMH_MO_Start_2 : 1|1@1+ (1.0,0.0) [0.0|1] ""  Vector__XXX
 SG_ NMH_MO_Normal_Mode_1 : 2|1@1+ (1.0,0.0) [0.0|1] ""  Vector__XXX
 SG_ NMH_MO_Normal_Mode_2 : 3|1@1+ (1.0,0.0) [0.0|1] ""  Vector__XXX
 SG_ NMH_MO_Car_WakeUp : 6|1@1+ (1.0,0.0) [0.0|1] ""  Vector__XXX
 SG_ NMH_MO_Per_WakeUp : 8|5@1+ (1.0,0.0) [0.0|31] ""  Vector__XXX
 SG_ NMH_MO_Func_WakeUp : 13|3@1+ (1.0,0.0) [0.0|7] ""  Vector__XXX
 SG_ NMH_MO_NM_Active_Terminal_15 : 16|1@1+ (1.0,0.0) [0.0|1] ""  Vector__XXX
 SG_ NMH_MO_NM_Active_Diagnostics : 17|1@1+ (1.0,0.0) [0.0|1] ""  Vector__XXX
 SG_ NMH_MO_NM_Active_Start : 18|1@1+ (1.0,0.0) [0.0|1] ""  Vector__XXX
 SG_ NMH_MO_NM_Active_EKP_Lead : 19|1@1+ (1.0,0.0) [0.0|1] ""  Vector__XXX
 SG_ NMH_MO_NM_Active_STH_Operation : 20|1@1+ (1.0,0.0) [0.0|1] ""  Vector__XXX
 SG_ NMH_MO_NM_Active_HV_Shutdown : 21|1@1+ (1.0,0.0) [0.0|1] ""  Vector__XXX
 SG_ NMH_MO_No_NL : 24|1@1+ (1.0,0.0) [0.0|1] ""  Vector__XXX
 SG_ NMH_MO_NL_RadiatorFan : 25|1@1+ (1.0,0.0) [0.0|1] ""  Vector__XXX
 SG_ NMH_MO_NL_Diagnostics : 26|1@1+ (1.0,0.0) [0.0|1] ""  Vector__XXX
 SG_ NMH_MO_NL_WFS : 27|1@1+ (1.0,0.0) [0.0|1] ""  Vector__XXX
 SG_ NMH_MO_NL_EEPROM : 28|1@1+ (1.0,0.0) [0.0|1] ""  Vector__XXX
 SG_ NMH_MO_NL_Other : 29|1@1+ (1.0,0.0) [0.0|1] ""  Vector__XXX
 SG_ NM_MO_SignalError : 32|1@1+ (1.0,0.0) [0.0|1] ""  Vector__XXX
 SG_ NMH_MO_TimeOut_Error : 33|1@1+ (1.0,0.0) [0.0|1] ""  Vector__XXX
 SG_ NMH_MO_CAN_Diag_Deactivated : 34|1@1+ (1.0,0.0) [0.0|1] ""  Vector__XXX
 SG_ NMH_MO_CompressorProtection : 35|1@1+ (1.0,0.0) [0.0|1] ""  Vector__XXX
 SG_ NMH_MO_Mute_Mode : 36|1@1+ (1.0,0.0) [0.0|1] ""  Vector__XXX
 SG_ NMH_MO_Transport_Mode : 37|1@1+ (1.0,0.0) [0.0|1] ""  Vector__XXX
 SG_ NMH_MO_ShutoffStage_Active : 38|1@1+ (1.0,0.0) [0.0|1] ""  Vector__XXX
 SG_ NMH_MO_SingleWire_Error : 39|1@1+ (1.0,0.0) [0.0|1] ""  Vector__XXX
 SG_ NMH_MO_LocalActive : 48|1@1+ (1.0,0.0) [0.0|1] ""  Vector__XXX
 SG_ NMH_MO_SubsystemActive : 49|1@1+ (1.0,0.0) [0.0|1] ""  Vector__XXX

BO_ 1736 NMH_Engine_Slave: 7 Motor_Slave_D4
 SG_ NMH_MO_SL_Start_1 : 0|1@1+ (1.0,0.0) [0.0|1] ""  EPB_D4,Gateway_D4C7,Getriebe_AL551_951_D4_C7,Getriebe_DL501_C7,Getriebe_VL381_C7,Motor_EDC17_D4,Motor_ME17_BY,Motor_MED17_SIMOS8_D4,Motor_Slave_D4,SCR_C7
 SG_ NMH_MO_SL_Start_2 : 1|1@1+ (1.0,0.0) [0.0|1] ""  Vector__XXX
 SG_ NMH_MO_SL_Normal_Mode_1 : 2|1@1+ (1.0,0.0) [0.0|1] ""  Vector__XXX
 SG_ NMH_MO_SL_Normal_Mode_2 : 3|1@1+ (1.0,0.0) [0.0|1] ""  Vector__XXX
 SG_ NMH_MO_SL_Car_WakeUp : 6|1@1+ (1.0,0.0) [0.0|1] ""  Vector__XXX
 SG_ NMH_MO_SL_Per_WakeUp : 8|5@1+ (1.0,0.0) [0.0|31] ""  Vector__XXX
 SG_ NMH_MO_SL_Func_WakeUp : 13|3@1+ (1.0,0.0) [0.0|7] ""  Vector__XXX
 SG_ NMH_MO_SL_TimeOut_Error : 33|1@1+ (1.0,0.0) [0.0|1] ""  Vector__XXX
 SG_ NMH_MO_SL_CAN_Diag_Deactivated : 34|1@1+ (1.0,0.0) [0.0|1] ""  Vector__XXX
 SG_ NMH_MO_SL_CompressorProtection : 35|1@1+ (1.0,0.0) [0.0|1] ""  Vector__XXX
 SG_ NMH_MO_SL_Mute_Mode : 36|1@1+ (1.0,0.0) [0.0|1] ""  Vector__XXX
 SG_ NMH_MO_SL_Transport_Mode : 37|1@1+ (1.0,0.0) [0.0|1] ""  Vector__XXX
 SG_ NMH_MO_SL_ShutoffStage_Active : 38|1@1+ (1.0,0.0) [0.0|1] ""  Vector__XXX
 SG_ NMH_MO_SL_BusError : 39|1@1+ (1.0,0.0) [0.0|1] ""  Vector__XXX
 SG_ NMH_MO_Sl_LocalActive : 48|1@1+ (1.0,0.0) [0.0|1] ""  Vector__XXX
 SG_ NMH_MO_SL_SubsystemActive : 49|1@1+ (1.0,0.0) [0.0|1] ""  Vector__XXX

BO_ 1782 NMH_SCR: 7 SCR_C7
 SG_ NMH_SCR_Start_1 : 0|1@1+ (1.0,0.0) [0.0|1] ""  EPB_D4,Gateway_D4C7,Getriebe_AL551_951_D4_C7,Getriebe_DL501_C7,Getriebe_VL381_C7,Motor_EDC17_D4,Motor_ME17_BY,Motor_MED17_SIMOS8_D4,Motor_Slave_D4,SCR_C7
 SG_ NMH_SCR_Start_2 : 1|1@1+ (1.0,0.0) [0.0|1] ""  Vector__XXX
 SG_ NMH_SCR_Normal_Mode_1 : 2|1@1+ (1.0,0.0) [0.0|1] ""  Vector__XXX
 SG_ NMH_SCR_Normal_Mode_2 : 3|1@1+ (1.0,0.0) [0.0|1] ""  Vector__XXX
 SG_ NMH_SCR_Car_WakeUp : 6|1@1+ (1.0,0.0) [0.0|1] ""  Vector__XXX
 SG_ NMH_SCR_Per_WakeUp : 8|5@1+ (1.0,0.0) [0.0|31] ""  Vector__XXX
 SG_ NMH_SCR_Func_WakeUp : 13|3@1+ (1.0,0.0) [0.0|7] ""  Vector__XXX
 SG_ NMH_SCR_Terminal_15 : 16|1@1+ (1.0,0.0) [0.0|1] ""  Vector__XXX
 SG_ NMH_SCR_Diagnostics : 17|1@1+ (1.0,0.0) [0.0|1] ""  Vector__XXX
 SG_ NMH_SCR_MinActiveTime : 18|1@1+ (1.0,0.0) [0.0|1] ""  Vector__XXX
 SG_ NMH_SCR_NL_Datem_EEPROM : 24|1@1+ (1.0,0.0) [0.0|1] ""  Vector__XXX
 SG_ NMH_SCR_SignalError : 32|1@1+ (1.0,0.0) [0.0|1] ""  Vector__XXX
 SG_ NMH_SCR_TimeOut_Error : 33|1@1+ (1.0,0.0) [0.0|1] ""  Vector__XXX
 SG_ NMH_SCR_CAN_Diag_Deactivated : 34|1@1+ (1.0,0.0) [0.0|1] ""  Vector__XXX
 SG_ NMH_SCR_CompressorProtection : 35|1@1+ (1.0,0.0) [0.0|1] ""  Vector__XXX
 SG_ NMH_SCR_Mute_Mode : 36|1@1+ (1.0,0.0) [0.0|1] ""  Vector__XXX
 SG_ NMH_SCR_Transport_Mode : 37|1@1+ (1.0,0.0) [0.0|1] ""  Vector__XXX
 SG_ NMH_SCR_ShutoffStage_Active : 38|1@1+ (1.0,0.0) [0.0|1] ""  Vector__XXX
 SG_ NMH_SCR_BusError : 39|1@1+ (1.0,0.0) [0.0|1] ""  Vector__XXX
 SG_ NMH_SCR_LocalActive : 48|1@1+ (1.0,0.0) [0.0|1] ""  Vector__XXX
 SG_ NMH_SCR_SubsystemActive : 49|1@1+ (1.0,0.0) [0.0|1] ""  Vector__XXX

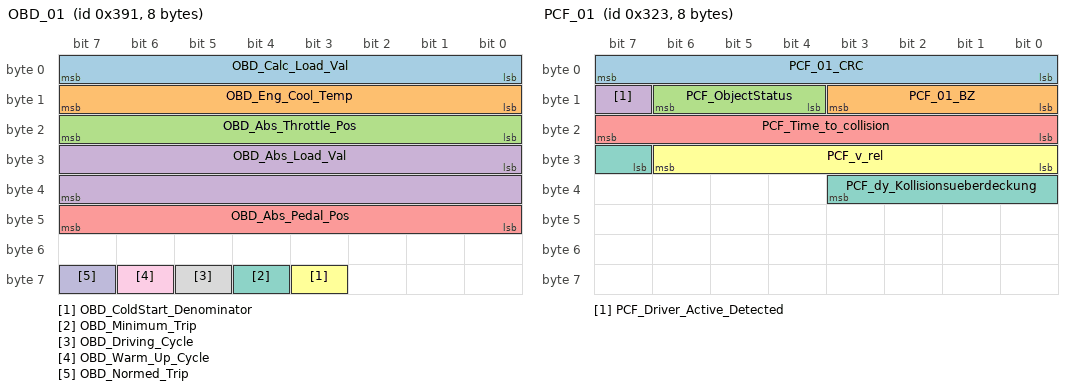
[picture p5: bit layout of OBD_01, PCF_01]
BO_ 913 OBD_01: 8 Motor_EDC17_D4
 SG_ OBD_Calc_Load_Val : 0|8@1+ (0.39215686274509803,0) [0E-17|99.99999999999999765] "Unit_PerCent"  Getriebe_AL551_951_D4_C7,Getriebe_DL501_C7,Getriebe_VL381_C7
 SG_ OBD_Eng_Cool_Temp : 8|8@1+ (1,-40) [-40|215] "Unit_DegreCelsi"  Getriebe_AL551_951_D4_C7,Getriebe_DL501_C7,Getriebe_VL381_C7
 SG_ OBD_Abs_Throttle_Pos : 16|8@1+ (0.39215686274509803,0) [0E-17|99.99999999999999765] "Unit_PerCent"  Getriebe_AL551_951_D4_C7,Getriebe_DL501_C7,Getriebe_VL381_C7
 SG_ OBD_Abs_Load_Val : 24|16@1+ (0.39215686274509803,0) [0E-17|25699.99999999999939605] "Unit_PerCent"  Getriebe_AL551_951_D4_C7,Getriebe_DL501_C7,Getriebe_VL381_C7
 SG_ OBD_Abs_Pedal_Pos : 40|8@1+ (0.39215686274509803,0) [0E-17|99.99999999999999765] "Unit_PerCent"  Getriebe_AL551_951_D4_C7,Getriebe_DL501_C7,Getriebe_VL381_C7
 SG_ OBD_ColdStart_Denominator : 59|1@1+ (1.0,0.0) [0.0|1] ""  Vector__XXX
 SG_ OBD_Minimum_Trip : 60|1@1+ (1.0,0.0) [0.0|1] ""  Getriebe_AL551_951_D4_C7,Getriebe_DL501_C7,Getriebe_VL381_C7
 SG_ OBD_Driving_Cycle : 61|1@1+ (1.0,0.0) [0.0|1] ""  Getriebe_AL551_951_D4_C7,Getriebe_DL501_C7,Getriebe_VL381_C7,SCR_C7
 SG_ OBD_Warm_Up_Cycle : 62|1@1+ (1.0,0.0) [0.0|1] ""  Gateway_D4C7,Getriebe_AL551_951_D4_C7,Getriebe_DL501_C7,Getriebe_VL381_C7,SCR_C7
 SG_ OBD_Normed_Trip : 63|1@1+ (1.0,0.0) [0.0|1] ""  Getriebe_AL551_951_D4_C7,Getriebe_DL501_C7,Getriebe_VL381_C7,SCR_C7

BO_ 803 PCF_01: 8 Gateway_D4C7
 SG_ PCF_01_CRC : 0|8@1+ (1,0) [0|255] ""  Airbag_D4
 SG_ PCF_01_BZ : 8|4@1+ (1,0) [0|15] ""  Airbag_D4
 SG_ PCF_ObjectStatus : 12|3@1+ (1.0,0.0) [0.0|7] ""  Airbag_D4
 SG_ PCF_Driver_Active_Detected : 15|1@1+ (1.0,0.0) [0.0|1] ""  Vector__XXX
 SG_ PCF_Time_to_collision : 16|8@1+ (0.01,0) [0.00|2.50] "Unit_Secon"  Airbag_D4
 SG_ PCF_v_rel : 24|7@1+ (0.5,0) [0.5|63.5] "Unit_MeterPerSecon"  Airbag_D4
 SG_ PCF_dy_Kollisionsueberdeckung : 31|5@1+ (0.1,0) [0.1|2.9] "Unit_Meter"  Vector__XXX

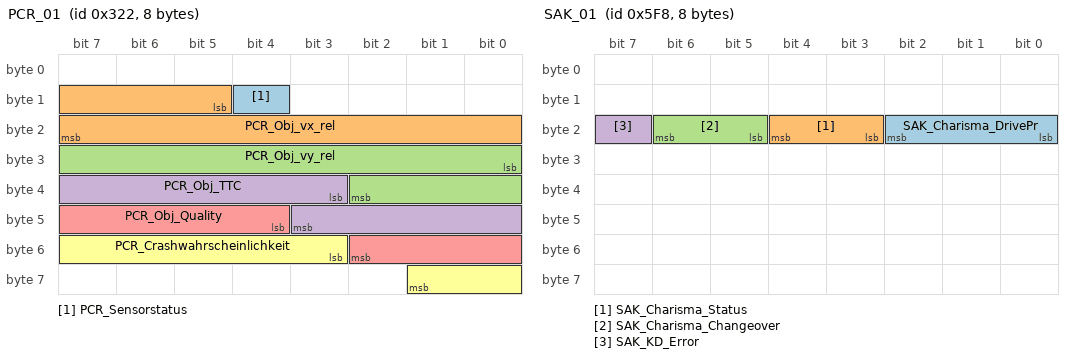
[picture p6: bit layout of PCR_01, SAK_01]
BO_ 802 PCR_01: 8 Gateway_D4C7
 SG_ PCR_Sensorstatus : 12|1@1+ (1.0,0.0) [0.0|1] ""  Airbag_D4
 SG_ PCR_Obj_vx_rel : 13|11@1+ (0.1,-102.3) [-102.3|102.3] "Unit_MeterPerSecon"  Airbag_D4
 SG_ PCR_Obj_vy_rel : 24|11@1+ (0.1,-102.3) [-102.3|102.3] "Unit_MeterPerSecon"  Airbag_D4
 SG_ PCR_Obj_TTC : 35|9@1+ (0.01,0) [0.00|5.10] "Unit_Secon"  Airbag_D4
 SG_ PCR_Obj_Quality : 44|7@1+ (1,0) [0|100] "Unit_PerCent"  Airbag_D4
 SG_ PCR_Crashwahrscheinlichkeit : 51|7@1+ (1,0) [0|100] "Unit_PerCent"  Airbag_D4

BO_ 929 PSD_01: 8 Gateway_D4C7
 SG_ PSD_Pos_Segment_ID : 0|6@1+ (1,0) [2|63] ""  Getriebe_AL551_951_D4_C7,Getriebe_DL501_C7,Getriebe_VL381_C7
 SG_ PSD_Pos_SegmentLength : 6|7@1+ (2,0) [0|254] "Unit_Meter"  Getriebe_AL551_951_D4_C7,Getriebe_DL501_C7,Getriebe_VL381_C7
 SG_ PSD_Pos_Inhibitzeit : 13|5@1+ (10,0) [0|310] "Unit_MilliSecon"  Getriebe_AL551_951_D4_C7,Getriebe_DL501_C7,Getriebe_VL381_C7
 SG_ PSD_Pos_Location : 18|1@1+ (1.0,0.0) [0.0|1] ""  Getriebe_AL551_951_D4_C7,Getriebe_DL501_C7,Getriebe_VL381_C7
 SG_ PSD_Pos_Laengsfehler : 19|3@1+ (1.0,0.0) [0.0|7] ""  Getriebe_AL551_951_D4_C7,Getriebe_DL501_C7,Getriebe_VL381_C7
 SG_ PSD_Segment_ID : 22|6@1+ (1,0) [2|63] ""  Getriebe_AL551_951_D4_C7,Getriebe_DL501_C7,Getriebe_VL381_C7
 SG_ PSD_Predecessor_Segment_ID : 28|6@1+ (1,0) [2|63] ""  Getriebe_AL551_951_D4_C7,Getriebe_DL501_C7,Getriebe_VL381_C7
 SG_ PSD_RoadClass : 34|2@1+ (1.0,0.0) [0.0|3] ""  Getriebe_AL551_951_D4_C7,Getriebe_DL501_C7,Getriebe_VL381_C7
 SG_ PSD_SegmentLength : 36|7@1+ (2,0) [0|254] "Unit_Meter"  Getriebe_AL551_951_D4_C7,Getriebe_DL501_C7,Getriebe_VL381_C7
 SG_ PSD_Ramp : 43|2@1+ (1.0,0.0) [0.0|3] ""  Getriebe_AL551_951_D4_C7,Getriebe_DL501_C7,Getriebe_VL381_C7
 SG_ PSD_EndCurvature : 45|8@1+ (1,0) [0|254] "Unit_None"  Getriebe_AL551_951_D4_C7,Getriebe_DL501_C7,Getriebe_VL381_C7
 SG_ PSD_EndCurvature_Sign : 53|1@1+ (1.0,0.0) [0.0|1] ""  Getriebe_AL551_951_D4_C7,Getriebe_DL501_C7,Getriebe_VL381_C7
 SG_ PSD_EndGradient : 54|5@1+ (0.5,0) [0.0|14.5] "Unit_PerCent"  Getriebe_AL551_951_D4_C7,Getriebe_DL501_C7,Getriebe_VL381_C7
 SG_ PSD_EndGradient_Sign : 59|1@1+ (1.0,0.0) [0.0|1] ""  Getriebe_AL551_951_D4_C7,Getriebe_DL501_C7,Getriebe_VL381_C7
 SG_ PSD_ADAS_Quality : 60|1@1+ (1.0,0.0) [0.0|1] ""  Getriebe_AL551_951_D4_C7,Getriebe_DL501_C7,Getriebe_VL381_C7
 SG_ PSD_Lanes : 61|2@1+ (1.0,0.0) [0.0|3] ""  Getriebe_AL551_951_D4_C7,Getriebe_DL501_C7,Getriebe_VL381_C7
 SG_ PSD_MostLikely_Path : 63|1@1+ (1.0,0.0) [0.0|1] ""  Getriebe_AL551_951_D4_C7,Getriebe_DL501_C7,Getriebe_VL381_C7

BO_ 930 PSD_02: 8 Gateway_D4C7
 SG_ PSD_Multiplex M  : 0|2@1+ (1.0,0.0) [0.0|3] ""  Getriebe_AL551_951_D4_C7,Getriebe_DL501_C7,Getriebe_VL381_C7
 SG_ PSD_Sys_Segment_ID m0  : 2|6@1+ (1,0) [2|63] ""  Getriebe_AL551_951_D4_C7,Getriebe_DL501_C7,Getriebe_VL381_C7
 SG_ PSD_Abz_Segment_ID m1  : 2|6@1+ (1,0) [2|63] ""  Getriebe_AL551_951_D4_C7,Getriebe_DL501_C7,Getriebe_VL381_C7
 SG_ PSD_Total_Segment_ID m2  : 2|6@1+ (1,0) [2|63] ""  Getriebe_AL551_951_D4_C7,Getriebe_DL501_C7,Getriebe_VL381_C7
 SG_ PSD_Location_Length_VZ m3  : 2|1@1+ (1.0,0.0) [0.0|1] ""  Getriebe_AL551_951_D4_C7,Getriebe_DL501_C7,Getriebe_VL381_C7
 SG_ PSD_Location_Length m3  : 3|25@1+ (0.00001,0) [0.00000|180.00000] "Unit_DegreOfArc"  Getriebe_AL551_951_D4_C7,Getriebe_DL501_C7,Getriebe_VL381_C7
 SG_ PSD_Sys_Laendercode m0  : 8|8@1+ (1.0,0.0) [0.0|255] ""  Getriebe_AL551_951_D4_C7,Getriebe_DL501_C7,Getriebe_VL381_C7
 SG_ PSD_Abz_SegmentLength m1  : 8|7@1+ (2,0) [0|254] "Unit_Meter"  Getriebe_AL551_951_D4_C7,Getriebe_DL501_C7,Getriebe_VL381_C7
 SG_ PSD_Total_Speed m2  : 8|5@1+ (1.0,0.0) [0.0|31] ""  Getriebe_AL551_951_D4_C7,Getriebe_DL501_C7,Getriebe_VL381_C7
 SG_ PSD_Total_Speed_Type m2  : 13|1@1+ (1.0,0.0) [0.0|1] ""  Getriebe_AL551_951_D4_C7,Getriebe_DL501_C7,Getriebe_VL381_C7
 SG_ PSD_Total_Speed_TrailerCombo m2  : 14|2@1+ (1.0,0.0) [0.0|3] ""  Getriebe_AL551_951_D4_C7,Getriebe_DL501_C7,Getriebe_VL381_C7
 SG_ PSD_Abz_Predecessor_Segment_ID m1  : 15|6@1+ (1,0) [2|63] ""  Getriebe_AL551_951_D4_C7,Getriebe_DL501_C7,Getriebe_VL381_C7
 SG_ PSD_Sys_Speed_Unit m0  : 16|1@1+ (1.0,0.0) [0.0|1] ""  Getriebe_AL551_951_D4_C7,Getriebe_DL501_C7,Getriebe_VL381_C7
 SG_ PSD_Total_Speed_Witter m2  : 16|2@1+ (1.0,0.0) [0.0|3] ""  Getriebe_AL551_951_D4_C7,Getriebe_DL501_C7,Getriebe_VL381_C7
 SG_ PSD_Sys_Verkehrsrichtung m0  : 17|1@1+ (1.0,0.0) [0.0|1] ""  Getriebe_AL551_951_D4_C7,Getriebe_DL501_C7,Getriebe_VL381_C7
 SG_ PSD_Sys_Release_Month m0  : 18|4@1+ (1,0) [1|12] "Unit_Month"  Getriebe_AL551_951_D4_C7,Getriebe_DL501_C7,Getriebe_VL381_C7
 SG_ PSD_Total_Speed_Tag_Req m2  : 18|3@1+ (1.0,0.0) [0.0|7] ""  Getriebe_AL551_951_D4_C7,Getriebe_DL501_C7,Getriebe_VL381_C7
 SG_ PSD_Abz_Speed m1  : 21|5@1+ (1.0,0.0) [0.0|31] ""  Getriebe_AL551_951_D4_C7,Getriebe_DL501_C7,Getriebe_VL381_C7
 SG_ PSD_Total_Speed_Tag_End m2  : 21|3@1+ (1.0,0.0) [0.0|7] ""  Getriebe_AL551_951_D4_C7,Getriebe_DL501_C7,Getriebe_VL381_C7
 SG_ PSD_Sys_Release_Year m0  : 22|5@1+ (1,2000) [2000|2031] "Unit_Year"  Getriebe_AL551_951_D4_C7,Getriebe_DL501_C7,Getriebe_VL381_C7
 SG_ PSD_Total_Speed_Std_Req m2  : 24|5@1+ (1,0) [0|24] "Unit_Hours"  Getriebe_AL551_951_D4_C7,Getriebe_DL501_C7,Getriebe_VL381_C7
 SG_ PSD_Abz_Speed_Type m1  : 26|1@1+ (1.0,0.0) [0.0|1] ""  Getriebe_AL551_951_D4_C7,Getriebe_DL501_C7,Getriebe_VL381_C7
 SG_ PSD_Sys_Tunnel m0  : 27|1@1+ (1.0,0.0) [0.0|1] ""  Getriebe_AL551_951_D4_C7,Getriebe_DL501_C7,Getriebe_VL381_C7
 SG_ PSD_Abz_RoadClass m1  : 27|2@1+ (1.0,0.0) [0.0|3] ""  Getriebe_AL551_951_D4_C7,Getriebe_DL501_C7,Getriebe_VL381_C7
 SG_ PSD_Sys_Bruecke m0  : 28|1@1+ (1.0,0.0) [0.0|1] ""  Getriebe_AL551_951_D4_C7,Getriebe_DL501_C7,Getriebe_VL381_C7
 SG_ PSD_Location_Width_VZ m3  : 28|1@1+ (1.0,0.0) [0.0|1] ""  Getriebe_AL551_951_D4_C7,Getriebe_DL501_C7,Getriebe_VL381_C7
 SG_ PSD_Sys_Fahrsp_Gegenr m0  : 29|2@1+ (1.0,0.0) [0.0|3] ""  Getriebe_AL551_951_D4_C7,Getriebe_DL501_C7,Getriebe_VL381_C7
 SG_ PSD_Abz_ADAS_Quality m1  : 29|1@1+ (1.0,0.0) [0.0|1] ""  Getriebe_AL551_951_D4_C7,Getriebe_DL501_C7,Getriebe_VL381_C7
 SG_ PSD_Total_Speed_Std_End m2  : 29|5@1+ (1,0) [0|24] "Unit_Hours"  Getriebe_AL551_951_D4_C7,Getriebe_DL501_C7,Getriebe_VL381_C7
 SG_ PSD_Location_Width m3  : 29|24@1+ (0.00001,0) [0.00000|90.00000] "Unit_DegreOfArc"  Getriebe_AL551_951_D4_C7,Getriebe_DL501_C7,Getriebe_VL381_C7
 SG_ PSD_Abz_Abzweigerichtung m1  : 30|1@1+ (1.0,0.0) [0.0|1] ""  Getriebe_AL551_951_D4_C7,Getriebe_DL501_C7,Getriebe_VL381_C7
 SG_ PSD_Sys_TMC_Roadworks m0  : 31|1@1+ (1.0,0.0) [0.0|1] ""  Getriebe_AL551_951_D4_C7,Getriebe_DL501_C7,Getriebe_VL381_C7
 SG_ PSD_Abz_Abzweigewinkel m1  : 31|4@1+ (1.0,0.0) [0.0|15] ""  Getriebe_AL551_951_D4_C7,Getriebe_DL501_C7,Getriebe_VL381_C7
 SG_ PSD_Sys_TMC_TrafficJam m0  : 32|1@1+ (1.0,0.0) [0.0|1] ""  Getriebe_AL551_951_D4_C7,Getriebe_DL501_C7,Getriebe_VL381_C7
 SG_ PSD_Total_Age_Speed m2  : 34|5@1+ (1.0,0.0) [0.0|31] ""  Getriebe_AL551_951_D4_C7,Getriebe_DL501_C7,Getriebe_VL381_C7
 SG_ PSD_Abz_Ramp m1  : 35|2@1+ (1.0,0.0) [0.0|3] ""  Getriebe_AL551_951_D4_C7,Getriebe_DL501_C7,Getriebe_VL381_C7
 SG_ PSD_Abz_StartCurvature m1  : 37|8@1+ (1,0) [0|254] "Unit_None"  Getriebe_AL551_951_D4_C7,Getriebe_DL501_C7,Getriebe_VL381_C7
 SG_ PSD_Total_Age_Speed_TrailerCombo m2  : 39|2@1+ (1.0,0.0) [0.0|3] ""  Getriebe_AL551_951_D4_C7,Getriebe_DL501_C7,Getriebe_VL381_C7
 SG_ PSD_Total_Age_Speed_Witter m2  : 41|2@1+ (1.0,0.0) [0.0|3] ""  Getriebe_AL551_951_D4_C7,Getriebe_DL501_C7,Getriebe_VL381_C7
 SG_ PSD_Total_Age_Speed_Tag_Req m2  : 43|3@1+ (1.0,0.0) [0.0|7] ""  Getriebe_AL551_951_D4_C7,Getriebe_DL501_C7,Getriebe_VL381_C7
 SG_ PSD_Abz_StartCurvature_Sign m1  : 45|1@1+ (1.0,0.0) [0.0|1] ""  Getriebe_AL551_951_D4_C7,Getriebe_DL501_C7,Getriebe_VL381_C7
 SG_ PSD_Sys_StartCurvature m0  : 46|8@1+ (1,0) [0|254] "Unit_None"  Getriebe_AL551_951_D4_C7,Getriebe_DL501_C7,Getriebe_VL381_C7
 SG_ PSD_Abz_EndCurvature m1  : 46|8@1+ (1,0) [0|254] "Unit_None"  Getriebe_AL551_951_D4_C7,Getriebe_DL501_C7,Getriebe_VL381_C7
 SG_ PSD_Total_Age_Speed_Tag_End m2  : 46|3@1+ (1.0,0.0) [0.0|7] ""  Getriebe_AL551_951_D4_C7,Getriebe_DL501_C7,Getriebe_VL381_C7
 SG_ PSD_Total_Age_Speed_Std_Req m2  : 49|5@1+ (1,0) [0|24] "Unit_Hours"  Getriebe_AL551_951_D4_C7,Getriebe_DL501_C7,Getriebe_VL381_C7
 SG_ PSD_Location_Height m3  : 53|11@1+ (5,-1000) [-1000|8000] "Unit_Meter"  Getriebe_AL551_951_D4_C7,Getriebe_DL501_C7,Getriebe_VL381_C7
 SG_ PSD_Sys_StartCurvature_Sign m0  : 54|1@1+ (1.0,0.0) [0.0|1] ""  Getriebe_AL551_951_D4_C7,Getriebe_DL501_C7,Getriebe_VL381_C7
 SG_ PSD_Abz_EndCurvature_Sign m1  : 54|1@1+ (1.0,0.0) [0.0|1] ""  Getriebe_AL551_951_D4_C7,Getriebe_DL501_C7,Getriebe_VL381_C7
 SG_ PSD_Total_Age_Speed_Std_End m2  : 54|5@1+ (1,0) [0|24] "Unit_Hours"  Getriebe_AL551_951_D4_C7,Getriebe_DL501_C7,Getriebe_VL381_C7
 SG_ PSD_Sys_Anfangssteigung m0  : 55|5@1+ (0.5,0) [0.0|14.5] "Unit_PerCent"  Getriebe_AL551_951_D4_C7,Getriebe_DL501_C7,Getriebe_VL381_C7
 SG_ PSD_Abz_EndGradient m1  : 55|5@1+ (0.5,0) [0.0|14.5] "Unit_PerCent"  Getriebe_AL551_951_D4_C7,Getriebe_DL501_C7,Getriebe_VL381_C7
 SG_ PSD_Total_NoOvertaking m2  : 59|2@1+ (1.0,0.0) [0.0|3] ""  Getriebe_AL551_951_D4_C7,Getriebe_DL501_C7,Getriebe_VL381_C7
 SG_ PSD_Sys_Anfangssteigung_Sign m0  : 60|1@1+ (1.0,0.0) [0.0|1] ""  Getriebe_AL551_951_D4_C7,Getriebe_DL501_C7,Getriebe_VL381_C7
 SG_ PSD_Abz_EndGradient_Sign m1  : 60|1@1+ (1.0,0.0) [0.0|1] ""  Getriebe_AL551_951_D4_C7,Getriebe_DL501_C7,Getriebe_VL381_C7
 SG_ PSD_Sys_BuiltUpArea m0  : 61|1@1+ (1.0,0.0) [0.0|1] ""  Getriebe_AL551_951_D4_C7,Getriebe_DL501_C7,Getriebe_VL381_C7
 SG_ PSD_Abz_Lanes m1  : 61|2@1+ (1.0,0.0) [0.0|3] ""  Getriebe_AL551_951_D4_C7,Getriebe_DL501_C7,Getriebe_VL381_C7
 SG_ PSD_Total_VariableTrafficSign m2  : 61|3@1+ (1.0,0.0) [0.0|7] ""  Getriebe_AL551_951_D4_C7,Getriebe_DL501_C7,Getriebe_VL381_C7
 SG_ PSD_Sys_Digitalisierung m0  : 62|1@1+ (1.0,0.0) [0.0|1] ""  Getriebe_AL551_951_D4_C7,Getriebe_DL501_C7,Getriebe_VL381_C7
 SG_ PSD_Sys_RouteGuidance m0  : 63|1@1+ (1.0,0.0) [0.0|1] ""  Getriebe_AL551_951_D4_C7,Getriebe_DL501_C7,Getriebe_VL381_C7
 SG_ PSD_Abz_MostLikely_Path m1  : 63|1@1+ (1.0,0.0) [0.0|1] ""  Getriebe_AL551_951_D4_C7,Getriebe_DL501_C7,Getriebe_VL381_C7

BO_ 2033 Request_Airbag_Deployment: 8 Gateway_D4C7
 SG_ Request_Airbag_Deployment : 0|64@1+ (1.0,0.0) [0.0|18446744073709551615] ""  Airbag_D4

BO_ 2041 Response_Airbag_Deployment: 8 Airbag_D4
 SG_ Response_Airbag_Deployment : 0|64@1+ (1.0,0.0) [0.0|18446744073709551615] ""  Gateway_D4C7

BO_ 1528 SAK_01: 8 SAK_C7
 SG_ SAK_Charisma_DrivePr : 16|3@1+ (1.0,0.0) [0.0|7] ""  Vector__XXX
 SG_ SAK_Charisma_Status : 19|2@1+ (1.0,0.0) [0.0|3] ""  Vector__XXX
 SG_ SAK_Charisma_Changeover : 21|2@1+ (1.0,0.0) [0.0|3] ""  Vector__XXX
 SG_ SAK_KD_Error : 23|1@1+ (1.0,0.0) [0.0|1] ""  Gateway_D4C7

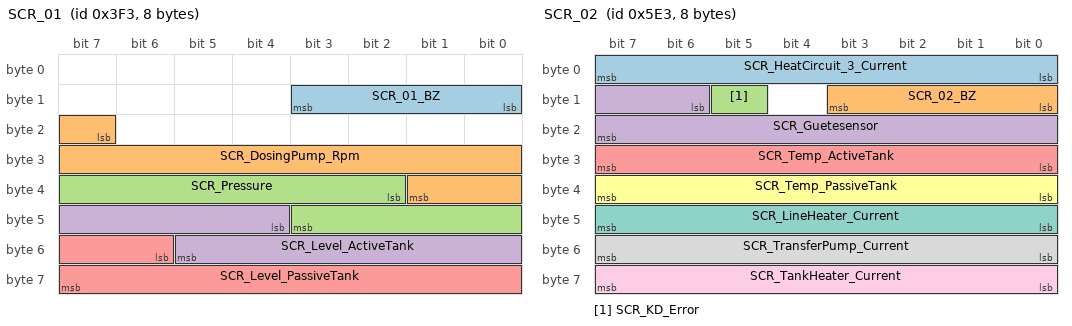
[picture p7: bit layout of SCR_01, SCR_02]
BO_ 1011 SCR_01: 8 SCR_C7
 SG_ SCR_01_BZ : 8|4@1+ (1,0) [0|15] ""  Motor_EDC17_D4
 SG_ SCR_DosingPump_Rpm : 23|11@1+ (4,-4080) [-4080|4100] "Unit_MinutInver"  Motor_EDC17_D4
 SG_ SCR_Pressure : 34|10@1+ (5,0) [0|5000] "Unit_MilliVolt"  Motor_EDC17_D4
 SG_ SCR_Level_ActiveTank : 44|10@1+ (5,0) [0|5000] "Unit_MilliVolt"  Motor_EDC17_D4
 SG_ SCR_Level_PassiveTank : 54|10@1+ (5,0) [0|5000] "Unit_MilliVolt"  Motor_EDC17_D4

BO_ 1507 SCR_02: 8 SCR_C7
 SG_ SCR_HeatCircuit_3_Current : 0|8@1+ (0.1,0) [0.0|14.0] "Unit_Amper"  Motor_EDC17_D4
 SG_ SCR_02_BZ : 8|4@1+ (1,0) [0|15] ""  Motor_EDC17_D4
 SG_ SCR_KD_Error : 13|1@1+ (1.0,0.0) [0.0|1] ""  Gateway_D4C7
 SG_ SCR_Guetesensor : 14|10@1+ (5,0) [0|5000] "Unit_MilliVolt"  Motor_EDC17_D4
 SG_ SCR_Temp_ActiveTank : 24|8@1+ (20,0) [0|5000] "Unit_MilliVolt"  Motor_EDC17_D4
 SG_ SCR_Temp_PassiveTank : 32|8@1+ (20,0) [0|5000] "Unit_MilliVolt"  Motor_EDC17_D4
 SG_ SCR_LineHeater_Current : 40|8@1+ (0.1,0) [0.0|14.0] "Unit_Amper"  Motor_EDC17_D4
 SG_ SCR_TransferPump_Current : 48|8@1+ (0.1,0) [0.0|14.0] "Unit_Amper"  Motor_EDC17_D4
 SG_ SCR_TankHeater_Current : 56|8@1+ (0.1,0) [0.0|14.0] "Unit_Amper"  Motor_EDC17_D4

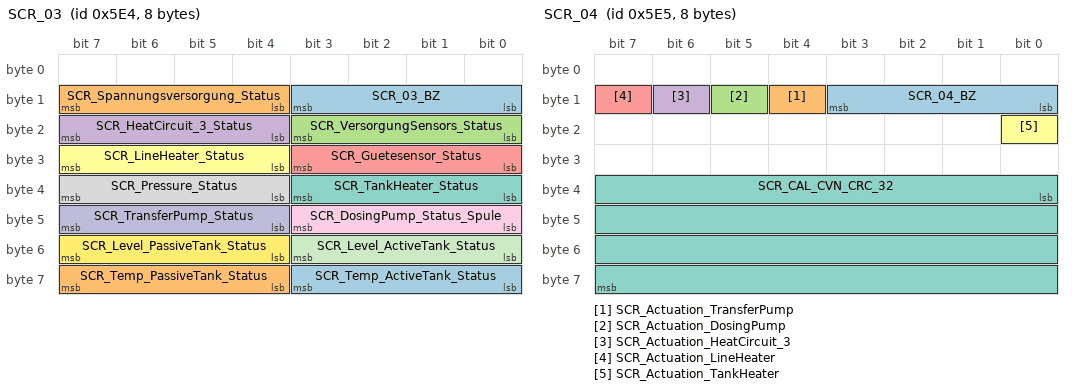
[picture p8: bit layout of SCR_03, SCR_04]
BO_ 1508 SCR_03: 8 SCR_C7
 SG_ SCR_03_BZ : 8|4@1+ (1,0) [0|15] ""  Motor_EDC17_D4
 SG_ SCR_Spannungsversorgung_Status : 12|4@1+ (1.0,0.0) [0.0|15] ""  Motor_EDC17_D4
 SG_ SCR_VersorgungSensors_Status : 16|4@1+ (1.0,0.0) [0.0|15] ""  Motor_EDC17_D4
 SG_ SCR_HeatCircuit_3_Status : 20|4@1+ (1.0,0.0) [0.0|15] ""  Motor_EDC17_D4
 SG_ SCR_Guetesensor_Status : 24|4@1+ (1.0,0.0) [0.0|15] ""  Motor_EDC17_D4
 SG_ SCR_LineHeater_Status : 28|4@1+ (1.0,0.0) [0.0|15] ""  Motor_EDC17_D4
 SG_ SCR_TankHeater_Status : 32|4@1+ (1.0,0.0) [0.0|15] ""  Motor_EDC17_D4
 SG_ SCR_Pressure_Status : 36|4@1+ (1.0,0.0) [0.0|15] ""  Motor_EDC17_D4
 SG_ SCR_DosingPump_Status_Spule : 40|4@1+ (1.0,0.0) [0.0|15] ""  Motor_EDC17_D4
 SG_ SCR_TransferPump_Status : 44|4@1+ (1.0,0.0) [0.0|15] ""  Motor_EDC17_D4
 SG_ SCR_Level_ActiveTank_Status : 48|4@1+ (1.0,0.0) [0.0|15] ""  Motor_EDC17_D4
 SG_ SCR_Level_PassiveTank_Status : 52|4@1+ (1.0,0.0) [0.0|15] ""  Motor_EDC17_D4
 SG_ SCR_Temp_ActiveTank_Status : 56|4@1+ (1.0,0.0) [0.0|15] ""  Motor_EDC17_D4
 SG_ SCR_Temp_PassiveTank_Status : 60|4@1+ (1.0,0.0) [0.0|15] ""  Motor_EDC17_D4

BO_ 1509 SCR_04: 8 SCR_C7
 SG_ SCR_04_BZ : 8|4@1+ (1,0) [0|15] ""  Motor_EDC17_D4
 SG_ SCR_Actuation_TransferPump : 12|1@1+ (1.0,0.0) [0.0|1] ""  Motor_EDC17_D4
 SG_ SCR_Actuation_DosingPump : 13|1@1+ (1.0,0.0) [0.0|1] ""  Motor_EDC17_D4
 SG_ SCR_Actuation_HeatCircuit_3 : 14|1@1+ (1.0,0.0) [0.0|1] ""  Motor_EDC17_D4
 SG_ SCR_Actuation_LineHeater : 15|1@1+ (1.0,0.0) [0.0|1] ""  Motor_EDC17_D4
 SG_ SCR_Actuation_TankHeater : 16|1@1+ (1.0,0.0) [0.0|1] ""  Motor_EDC17_D4
 SG_ SCR_CAL_CVN_CRC_32 : 32|32@1+ (1.0,0.0) [0.0|4294967295] ""  Motor_EDC17_D4

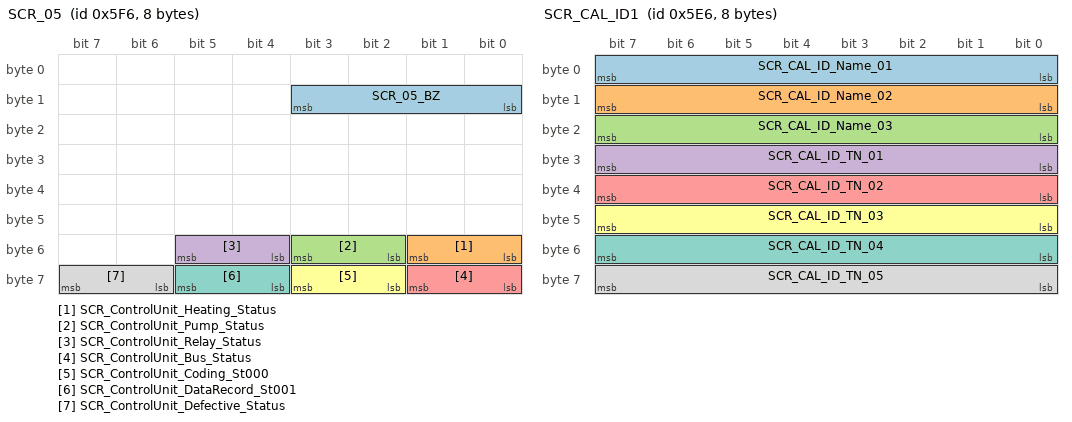
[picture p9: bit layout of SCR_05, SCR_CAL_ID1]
BO_ 1526 SCR_05: 8 SCR_C7
 SG_ SCR_05_BZ : 8|4@1+ (1,0) [0|15] ""  Motor_EDC17_D4
 SG_ SCR_ControlUnit_Heating_Status : 48|2@1+ (1.0,0.0) [0.0|3] ""  Motor_EDC17_D4
 SG_ SCR_ControlUnit_Pump_Status : 50|2@1+ (1.0,0.0) [0.0|3] ""  Motor_EDC17_D4
 SG_ SCR_ControlUnit_Relay_Status : 52|2@1+ (1.0,0.0) [0.0|3] ""  Motor_EDC17_D4
 SG_ SCR_ControlUnit_Bus_Status : 56|2@1+ (1.0,0.0) [0.0|3] ""  Motor_EDC17_D4
 SG_ SCR_ControlUnit_Coding_St000 : 58|2@1+ (1.0,0.0) [0.0|3] ""  Motor_EDC17_D4
 SG_ SCR_ControlUnit_DataRecord_St001 : 60|2@1+ (1.0,0.0) [0.0|3] ""  Motor_EDC17_D4
 SG_ SCR_ControlUnit_Defective_Status : 62|2@1+ (1.0,0.0) [0.0|3] ""  Motor_EDC17_D4

BO_ 1510 SCR_CAL_ID1: 8 SCR_C7
 SG_ SCR_CAL_ID_Name_01 : 0|8@1+ (1.0,0.0) [0.0|255] ""  Motor_EDC17_D4
 SG_ SCR_CAL_ID_Name_02 : 8|8@1+ (1.0,0.0) [0.0|255] ""  Motor_EDC17_D4
 SG_ SCR_CAL_ID_Name_03 : 16|8@1+ (1.0,0.0) [0.0|255] ""  Motor_EDC17_D4
 SG_ SCR_CAL_ID_TN_01 : 24|8@1+ (1.0,0.0) [0.0|255] ""  Motor_EDC17_D4
 SG_ SCR_CAL_ID_TN_02 : 32|8@1+ (1.0,0.0) [0.0|255] ""  Motor_EDC17_D4
 SG_ SCR_CAL_ID_TN_03 : 40|8@1+ (1.0,0.0) [0.0|255] ""  Motor_EDC17_D4
 SG_ SCR_CAL_ID_TN_04 : 48|8@1+ (1.0,0.0) [0.0|255] ""  Motor_EDC17_D4
 SG_ SCR_CAL_ID_TN_05 : 56|8@1+ (1.0,0.0) [0.0|255] ""  Motor_EDC17_D4

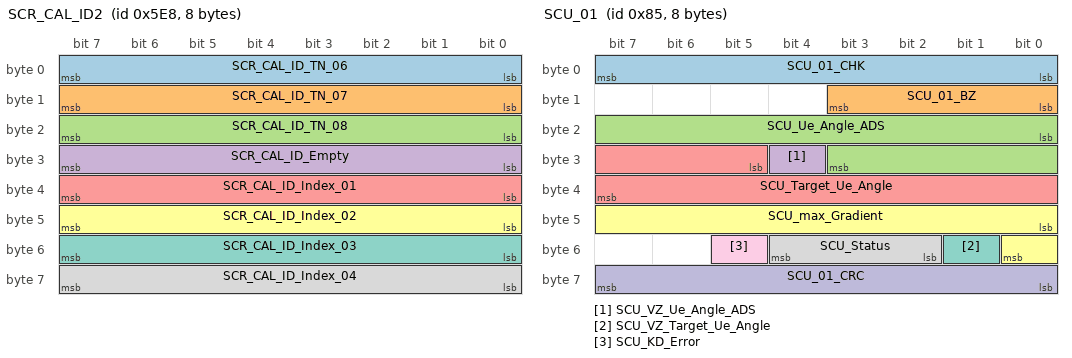
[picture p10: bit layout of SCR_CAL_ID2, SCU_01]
BO_ 1512 SCR_CAL_ID2: 8 SCR_C7
 SG_ SCR_CAL_ID_TN_06 : 0|8@1+ (1.0,0.0) [0.0|255] ""  Motor_EDC17_D4
 SG_ SCR_CAL_ID_TN_07 : 8|8@1+ (1.0,0.0) [0.0|255] ""  Motor_EDC17_D4
 SG_ SCR_CAL_ID_TN_08 : 16|8@1+ (1.0,0.0) [0.0|255] ""  Motor_EDC17_D4
 SG_ SCR_CAL_ID_Empty : 24|8@1+ (1.0,0.0) [0.0|255] ""  Motor_EDC17_D4
 SG_ SCR_CAL_ID_Index_01 : 32|8@1+ (1.0,0.0) [0.0|255] ""  Motor_EDC17_D4
 SG_ SCR_CAL_ID_Index_02 : 40|8@1+ (1.0,0.0) [0.0|255] ""  Motor_EDC17_D4
 SG_ SCR_CAL_ID_Index_03 : 48|8@1+ (1.0,0.0) [0.0|255] ""  Motor_EDC17_D4
 SG_ SCR_CAL_ID_Index_04 : 56|8@1+ (1.0,0.0) [0.0|255] ""  Motor_EDC17_D4

BO_ 133 SCU_01: 8 SCU_D4
 SG_ SCU_01_CHK : 0|8@1+ (1,0) [0|255] ""  Airbag_D4,ESP_D4,Gateway_D4C7,Motor_EDC17_D4,Motor_ME17_BY,Motor_MED17_SIMOS8_D4,QSP_D4
 SG_ SCU_01_BZ : 8|4@1+ (1,0) [0|15] ""  Airbag_D4,ESP_D4,Gateway_D4C7,Motor_EDC17_D4,Motor_ME17_BY,Motor_MED17_SIMOS8_D4,QSP_D4
 SG_ SCU_Ue_Angle_ADS : 16|12@1+ (0.1,0) [0.0|409.3] "Unit_DegreOfArc"  Airbag_D4,ESP_D4,Gateway_D4C7,Motor_EDC17_D4,Motor_ME17_BY,Motor_MED17_SIMOS8_D4,QSP_D4
 SG_ SCU_VZ_Ue_Angle_ADS : 28|1@1+ (1.0,0.0) [0.0|1] ""  Airbag_D4,ESP_D4,Gateway_D4C7,Motor_EDC17_D4,Motor_ME17_BY,Motor_MED17_SIMOS8_D4,QSP_D4
 SG_ SCU_Target_Ue_Angle : 29|11@1+ (0.1,0) [0.0|204.5] "Unit_DegreOfArc"  ESP_D4,Gateway_D4C7,QSP_D4
 SG_ SCU_max_Gradient : 40|9@1+ (1,0) [0|510] ""  ESP_D4,Gateway_D4C7,QSP_D4
 SG_ SCU_VZ_Target_Ue_Angle : 49|1@1+ (1.0,0.0) [0.0|1] ""  ESP_D4,Gateway_D4C7,QSP_D4
 SG_ SCU_Status : 50|3@1+ (1.0,0.0) [0.0|7] ""  ESP_D4,Gateway_D4C7,QSP_D4
 SG_ SCU_KD_Error : 53|1@1+ (1.0,0.0) [0.0|1] ""  ESP_D4,Gateway_D4C7,QSP_D4
 SG_ SCU_01_CRC : 56|8@1+ (1,0) [0|255] ""  ESP_D4,Gateway_D4C7,QSP_D4

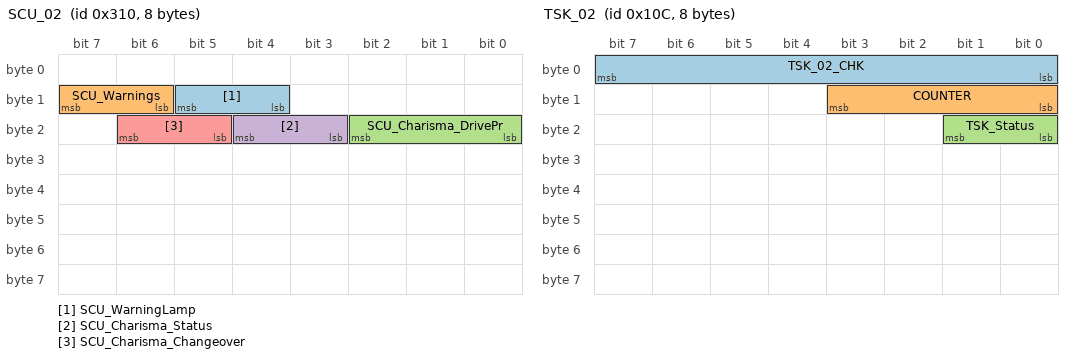
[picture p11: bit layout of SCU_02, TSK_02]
BO_ 784 SCU_02: 8 SCU_D4
 SG_ SCU_WarningLamp : 12|2@1+ (1.0,0.0) [0.0|3] ""  Gateway_D4C7
 SG_ SCU_Warnings : 14|2@1+ (1.0,0.0) [0.0|3] ""  Gateway_D4C7
 SG_ SCU_Charisma_DrivePr : 16|3@1+ (1.0,0.0) [0.0|7] ""  Gateway_D4C7
 SG_ SCU_Charisma_Status : 19|2@1+ (1.0,0.0) [0.0|3] ""  Gateway_D4C7
 SG_ SCU_Charisma_Changeover : 21|2@1+ (1.0,0.0) [0.0|3] ""  Gateway_D4C7

BO_ 1313 STH_01: 8 Gateway_D4C7
 SG_ STH_Radio_On : 0|1@1+ (1.0,0.0) [0.0|1] ""  Vector__XXX
 SG_ STH_Radio_Off : 1|1@1+ (1.0,0.0) [0.0|1] ""  Vector__XXX
 SG_ STH_AuxHeater : 2|1@1+ (1.0,0.0) [0.0|1] ""  Vector__XXX
 SG_ STH_LED : 3|1@1+ (1.0,0.0) [0.0|1] ""  Motor_EDC17_D4,Motor_ME17_BY,Motor_MED17_SIMOS8_D4
 SG_ STH_Pump_On : 4|1@1+ (1,0) [0|1] ""  Vector__XXX
 SG_ STH_Blower : 5|1@1+ (1.0,0.0) [0.0|1] ""  Vector__XXX
 SG_ STH_EKP_Anst : 6|1@1+ (1.0,0.0) [0.0|1] ""  Motor_EDC17_D4,Motor_ME17_BY,Motor_MED17_SIMOS8_D4
 SG_ STH_Start_Follows : 7|1@1+ (1.0,0.0) [0.0|1] ""  Vector__XXX
 SG_ STH_ValveOpeningTime : 8|6@1+ (1,0) [0|63] "Unit_Minut"  Vector__XXX
 SG_ STH_Valve_Status : 14|1@1+ (1.0,0.0) [0.0|1] ""  Vector__XXX
 SG_ STH_Waermeeintrag : 16|6@1+ (1,0) [0|63] ""  Vector__XXX
 SG_ STH_KVS : 24|13@1+ (1,0) [0|8191] "Unit_MilliLiter"  Vector__XXX
 SG_ STH_ErrorStatus : 37|3@1+ (1.0,0.0) [0.0|7] ""  Vector__XXX
 SG_ STH_HeatPower : 40|8@1+ (1,0) [0|255] ""  Vector__XXX
 SG_ STH_WaterTemp : 48|8@1+ (0.75,-40) [-40.00|142.25] "Unit_DegreCelsi"  Vector__XXX
 SG_ STH_Motorvorwaermung : 59|1@1+ (1.0,0.0) [0.0|1] ""  Motor_EDC17_D4,Motor_ME17_BY,Motor_MED17_SIMOS8_D4
 SG_ STH_Servicemode : 60|1@1+ (1,0) [0|1] ""  Vector__XXX
 SG_ STH_Was_Active : 61|1@1+ (1.0,0.0) [0.0|1] ""  Motor_EDC17_D4,Motor_ME17_BY,Motor_MED17_SIMOS8_D4
 SG_ STH_KVS_Overflow : 62|1@1+ (1.0,0.0) [0.0|1] ""  Vector__XXX
 SG_ STH_KD_Error : 63|1@1+ (1.0,0.0) [0.0|1] ""  Vector__XXX

BO_ 1172 Status_01: 8 Gateway_D4C7
 SG_ Status_01_CHK : 0|8@1+ (1,0) [0|255] ""  Motor_EDC17_D4,Motor_ME17_BY,Motor_MED17_SIMOS8_D4
 SG_ Status_01_BZ : 8|4@1+ (1,0) [0|15] ""  Motor_EDC17_D4,Motor_ME17_BY,Motor_MED17_SIMOS8_D4
 SG_ Status_Car_not_under_theft : 12|1@1+ (1.0,0.0) [0.0|1] ""  Vector__XXX
 SG_ Status_Car_under_theft : 13|1@1+ (1.0,0.0) [0.0|1] ""  Vector__XXX
 SG_ Status_StarterLock : 15|1@1+ (1.0,0.0) [0.0|1] ""  Vector__XXX
 SG_ Status_TypeCoding : 16|5@1+ (1.0,0.0) [0.0|31] ""  Vector__XXX
 SG_ Status_KD_Error : 22|1@1+ (1.0,0.0) [0.0|1] ""  Vector__XXX
 SG_ Status_LIN_Active : 23|1@1+ (1.0,0.0) [0.0|1] ""  Vector__XXX
 SG_ Status_SideLight : 24|1@1+ (1.0,0.0) [0.0|1] ""  Vector__XXX
 SG_ Status_Headlights : 25|1@1+ (1.0,0.0) [0.0|1] ""  Vector__XXX
 SG_ Status_Alarm_still : 26|1@1+ (1.0,0.0) [0.0|1] ""  Vector__XXX
 SG_ Status_Texte : 27|4@1+ (1.0,0.0) [0.0|15] ""  Vector__XXX
 SG_ Status_ChargeRelay : 38|1@1+ (1.0,0.0) [0.0|1] ""  Vector__XXX
 SG_ Status_Buzzer : 48|1@1+ (1.0,0.0) [0.0|1] ""  Vector__XXX
 SG_ Status_Alarm_Indicator : 50|1@1+ (1.0,0.0) [0.0|1] ""  Vector__XXX
 SG_ Status_EmergencyStart : 51|1@1+ (1.0,0.0) [0.0|1] ""  Vector__XXX
 SG_ Status_Horn : 55|1@1+ (1.0,0.0) [0.0|1] ""  Vector__XXX
 SG_ Status_IdleShift : 56|1@1+ (1.0,0.0) [0.0|1] ""  Motor_EDC17_D4,Motor_ME17_BY,Motor_MED17_SIMOS8_D4

BO_ 783 SWA_01: 8 Gateway_D4C7
 SG_ SWA_Status_CHK : 0|8@1+ (1,0) [0|255] ""  Vector__XXX
 SG_ SWA_Status_BZ : 8|4@1+ (1,0) [0|15] ""  Vector__XXX
 SG_ SWA_Display : 12|4@1+ (1.0,0.0) [0.0|15] ""  Kombi_D4
 SG_ SWA_Blindness_Detected : 16|1@1+ (1.0,0.0) [0.0|1] ""  Vector__XXX
 SG_ SWA_rel_NotAvail : 17|1@1+ (1.0,0.0) [0.0|1] ""  Vector__XXX
 SG_ SWA_rel_Error : 18|1@1+ (1.0,0.0) [0.0|1] ""  Vector__XXX
 SG_ SWA_Status_Active : 19|1@1+ (1.0,0.0) [0.0|1] ""  Vector__XXX
 SG_ SWA_Status_Passive : 20|1@1+ (1.0,0.0) [0.0|1] ""  Vector__XXX
 SG_ SWA_StationaryTargets_Left : 24|1@1+ (1.0,0.0) [0.0|1] ""  Vector__XXX
 SG_ SWA_Queue_Left : 25|1@1+ (1.0,0.0) [0.0|1] ""  Vector__XXX
 SG_ SWA_InfoLevel_SWA_Left : 26|1@1+ (1.0,0.0) [0.0|1] ""  Vector__XXX
 SG_ SWA_Warning_SWA_Left : 27|1@1+ (1.0,0.0) [0.0|1] ""  Vector__XXX
 SG_ SWA_Queue_mi : 33|1@1+ (1.0,0.0) [0.0|1] ""  Vector__XXX
 SG_ SWA_StationaryTargets_Right : 40|1@1+ (1.0,0.0) [0.0|1] ""  Vector__XXX
 SG_ SWA_Queue_Right : 41|1@1+ (1.0,0.0) [0.0|1] ""  Vector__XXX
 SG_ SWA_InfoLevel_SWA_Right : 42|1@1+ (1.0,0.0) [0.0|1] ""  Vector__XXX
 SG_ SWA_Warning_SWA_Right : 43|1@1+ (1.0,0.0) [0.0|1] ""  Vector__XXX
 SG_ SWA_Gischtzaehler : 48|7@1+ (1,0) [0|100] "Unit_PerCent"  Vector__XXX
 SG_ SWA_KD_Error : 59|1@1+ (1.0,0.0) [0.0|1] ""  Vector__XXX

BO_ 1413 SystemInfo_01: 8 Gateway_D4C7
 SG_ SI_Int_CAN_gespiegelt : 0|1@1+ (1.0,0.0) [0.0|1] ""  Vector__XXX
 SG_ SI_CAN_Comfort_Sleep : 1|1@1+ (1.0,0.0) [0.0|1] ""  Vector__XXX
 SG_ SI_CAN_Dashboard_Sleep : 2|1@1+ (1.0,0.0) [0.0|1] ""  Vector__XXX
 SG_ SI_CAN_Drive_Sleep : 3|1@1+ (1.0,0.0) [0.0|1] ""  Vector__XXX
 SG_ SI_Infotainment_Sleep : 4|1@1+ (1.0,0.0) [0.0|1] ""  Vector__XXX
 SG_ SI_CAN_Extended_Sleep : 5|1@1+ (1.0,0.0) [0.0|1] ""  Vector__XXX
 SG_ SI_Chassis_Sleep : 6|1@1+ (1.0,0.0) [0.0|1] ""  Vector__XXX
 SG_ SI_Diagnostics_Active : 7|1@1+ (1.0,0.0) [0.0|1] ""  Vector__XXX
 SG_ SI_QRS_Mode : 8|1@1+ (1.0,0.0) [0.0|1] ""  Getriebe_AL551_951_D4_C7
 SG_ SI_T_Mode : 9|1@1+ (1.0,0.0) [0.0|1] ""  Getriebe_AL551_951_D4_C7,Motor_EDC17_D4,Motor_ME17_BY,Motor_MED17_SIMOS8_D4
 SG_ SI_NWDF : 10|1@1+ (1.0,0.0) [0.0|1] ""  Vector__XXX
 SG_ SI_NWDF_Valid : 11|1@1+ (1.0,0.0) [0.0|1] ""  Vector__XXX
 SG_ SI_GeneralFault : 12|1@1+ (1.0,0.0) [0.0|1] ""  Vector__XXX
 SG_ GW_KD_Error : 13|1@1+ (1.0,0.0) [0.0|1] ""  Vector__XXX
 SG_ SI_MOST_Status : 15|1@1+ (1.0,0.0) [0.0|1] ""  Vector__XXX
 SG_ SI_Collective_ECU_Error : 56|6@1+ (1,0) [0|60] ""  Vector__XXX
 SG_ SI_MO_WU : 63|1@1+ (1.0,0.0) [0.0|1] ""  Vector__XXX

BO_ 1214 TPD_SCU_01: 8 Gateway_D4C7
 SG_ TPD_SCU_Data_1 : 0|64@1+ (1.0,0.0) [0.0|18446744073709551615] ""  SCU_D4

BO_ 768 TPD_Tester_01: 8 SCU_D4
 SG_ TPD_Tester_Data_1 : 0|64@1+ (1.0,0.0) [0.0|18446744073709551615] ""  Gateway_D4C7

BO_ 769 TPD_Tester_02: 8 SCU_D4
 SG_ TPD_Tester_Data_2 : 0|64@1+ (1.0,0.0) [0.0|18446744073709551615] ""  Gateway_D4C7

BO_ 770 TPD_Tester_03: 8 SCU_D4
 SG_ TPD_Tester_Data_3 : 0|64@1+ (1.0,0.0) [0.0|18446744073709551615] ""  Gateway_D4C7

BO_ 771 TPD_Tester_04: 8 SCU_D4
 SG_ TPD_Tester_Data_4 : 0|64@1+ (1.0,0.0) [0.0|18446744073709551615] ""  Gateway_D4C7

BO_ 772 TPD_Tester_05: 8 SCU_D4
 SG_ TPD_Tester_Data_5 : 0|64@1+ (1.0,0.0) [0.0|18446744073709551615] ""  Gateway_D4C7

BO_ 773 TPD_Tester_06: 8 SCU_D4
 SG_ TPD_Tester_Data_6 : 0|64@1+ (1.0,0.0) [0.0|18446744073709551615] ""  Gateway_D4C7

BO_ 774 TPD_Tester_07: 8 SCU_D4
 SG_ TPD_Tester_Data_7 : 0|64@1+ (1.0,0.0) [0.0|18446744073709551615] ""  Gateway_D4C7

BO_ 775 TPD_Tester_08: 8 SCU_D4
 SG_ TPD_Tester_Data_8 : 0|64@1+ (1.0,0.0) [0.0|18446744073709551615] ""  Gateway_D4C7

BO_ 542 TPS_SCU: 7 SCU_D4
 SG_ TPS_SCU_Data : 0|56@1+ (1.0,0.0) [0.0|72057594037927935] ""  Gateway_D4C7

BO_ 512 TPS_Tester: 7 Gateway_D4C7
 SG_ TPS_Tester_Data : 0|56@1+ (1.0,0.0) [0.0|72057594037927935] ""  SCU_D4

BO_ 268 TSK_02: 8 XXX
 SG_ TSK_02_CHK : 0|8@1+ (1,0) [0|255] "" XXX
 SG_ COUNTER : 8|4@1+ (1,0) [0|15] "" XXX
 SG_ TSK_Status : 16|2@1+ (1,0) [0|3] "" XXX

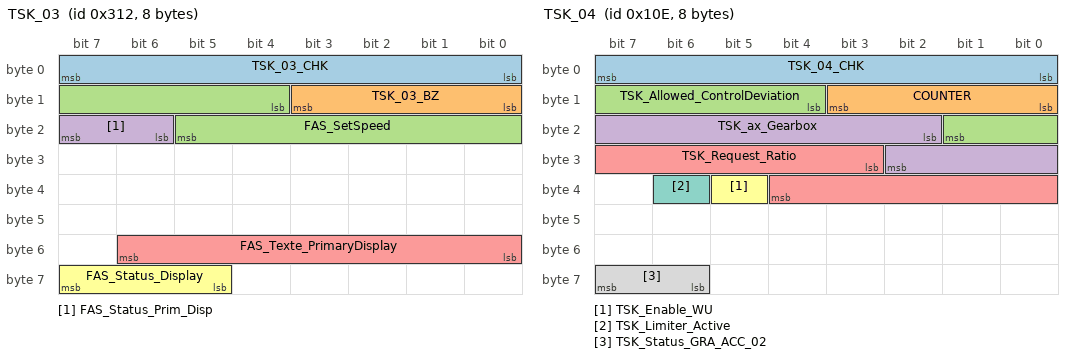
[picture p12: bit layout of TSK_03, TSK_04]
BO_ 786 TSK_03: 8 Motor_EDC17_D4
 SG_ TSK_03_CHK : 0|8@1+ (1,0) [0|255] ""  Gateway_D4C7
 SG_ TSK_03_BZ : 8|4@1+ (1,0) [0|15] ""  Gateway_D4C7
 SG_ FAS_SetSpeed : 12|10@1+ (0.32,0) [0.00|326.72] "Unit_KiloMeterPerHour"  Gateway_D4C7
 SG_ FAS_Status_Prim_Disp : 22|2@1+ (1.0,0.0) [0.0|3] ""  Gateway_D4C7
 SG_ FAS_Texte_PrimaryDisplay : 48|7@1+ (1.0,0.0) [0.0|127] ""  Gateway_D4C7
 SG_ FAS_Status_Display : 61|3@1+ (1.0,0.0) [0.0|7] ""  Gateway_D4C7

BO_ 270 TSK_04: 8 Motor_EDC17_D4
 SG_ TSK_04_CHK : 0|8@1+ (1,0) [0|255] ""  Getriebe_AL551_951_D4_C7,Getriebe_DL501_C7,Getriebe_VL381_C7
 SG_ COUNTER : 8|4@1+ (1,0) [0|15] ""  Getriebe_AL551_951_D4_C7,Getriebe_DL501_C7,Getriebe_VL381_C7
 SG_ TSK_Allowed_ControlDeviation : 12|6@1+ (0.024,0) [0.000|1.512] "Unit_MeterPerSeconSquar"  Getriebe_AL551_951_D4_C7,Getriebe_DL501_C7,Getriebe_VL381_C7
 SG_ TSK_ax_Gearbox : 18|9@1+ (0.024,-2.016) [-2.016|10.224] "Unit_MeterPerSeconSquar"  Getriebe_AL551_951_D4_C7,Getriebe_DL501_C7,Getriebe_VL381_C7
 SG_ TSK_Request_Ratio : 27|10@1+ (0.0245,0) [0.0245|25.0635] ""  Getriebe_AL551_951_D4_C7,Getriebe_DL501_C7,Getriebe_VL381_C7
 SG_ TSK_Enable_WU : 37|1@1+ (1.0,0.0) [0.0|1] ""  Getriebe_AL551_951_D4_C7,Getriebe_DL501_C7,Getriebe_VL381_C7
 SG_ TSK_Limiter_Active : 38|1@1+ (1.0,0.0) [0.0|1] ""  Getriebe_AL551_951_D4_C7,Getriebe_DL501_C7,Getriebe_VL381_C7
 SG_ TSK_Status_GRA_ACC_02 : 62|2@1+ (1.0,0.0) [0.0|3] ""  Getriebe_AL551_951_D4_C7,Getriebe_DL501_C7,Getriebe_VL381_C7

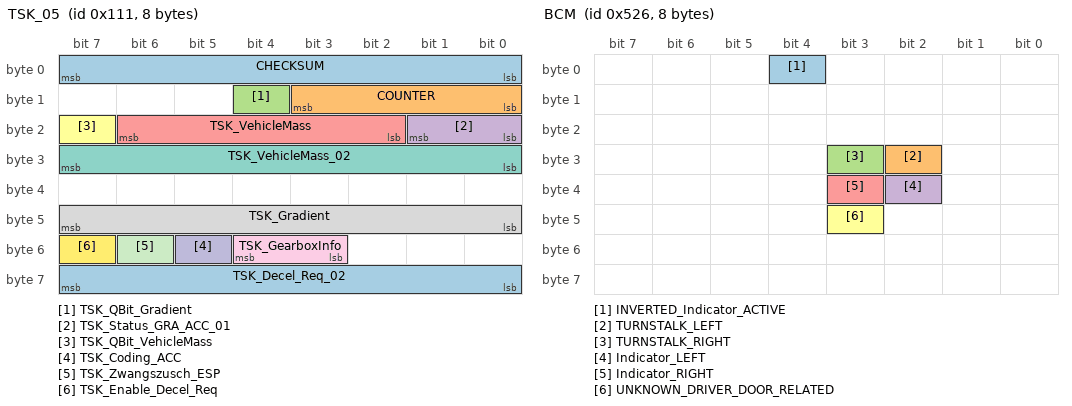
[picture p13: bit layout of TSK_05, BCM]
BO_ 273 TSK_05: 8 Motor_EDC17_D4
 SG_ CHECKSUM : 0|8@1+ (1,0) [0|255] ""  EPB_D4,Gateway_D4C7,Getriebe_AL551_951_D4_C7,Getriebe_DL501_C7,Getriebe_VL381_C7
 SG_ COUNTER : 8|4@1+ (1,0) [0|15] ""  EPB_D4,Gateway_D4C7,Getriebe_AL551_951_D4_C7,Getriebe_DL501_C7,Getriebe_VL381_C7
 SG_ TSK_QBit_Gradient : 12|1@1+ (1.0,0.0) [0.0|1] ""  Gateway_D4C7,Getriebe_AL551_951_D4_C7,Getriebe_DL501_C7,Getriebe_VL381_C7
 SG_ TSK_Status_GRA_ACC_01 : 16|2@1+ (1.0,0.0) [0.0|3] ""  Gateway_D4C7
 SG_ TSK_VehicleMass : 18|5@1+ (200,500) [500|6500] "Unit_KiloGram"  Gateway_D4C7
 SG_ TSK_QBit_VehicleMass : 23|1@1+ (1.0,0.0) [0.0|1] ""  Gateway_D4C7,Getriebe_AL551_951_D4_C7,Getriebe_DL501_C7,Getriebe_VL381_C7
 SG_ TSK_VehicleMass_02 : 24|8@1+ (32,0) [0|8128] "Unit_KiloGram"  Gateway_D4C7,Getriebe_AL551_951_D4_C7,Getriebe_DL501_C7,Getriebe_VL381_C7
 SG_ TSK_Gradient : 40|8@1+ (0.8,-101.6) [-101.6|101.6] "Unit_PerCent"  Gateway_D4C7,Getriebe_AL551_951_D4_C7,Getriebe_DL501_C7,Getriebe_VL381_C7
 SG_ TSK_GearboxInfo : 51|2@1+ (1.0,0.0) [0.0|3] ""  Gateway_D4C7
 SG_ TSK_Coding_ACC : 53|1@1+ (1.0,0.0) [0.0|1] ""  EPB_D4,Gateway_D4C7,Getriebe_AL551_951_D4_C7,Getriebe_DL501_C7,Getriebe_VL381_C7
 SG_ TSK_Zwangszusch_ESP : 54|1@1+ (1.0,0.0) [0.0|1] ""  Gateway_D4C7
 SG_ TSK_Enable_Decel_Req : 55|1@1+ (1.0,0.0) [0.0|1] ""  Gateway_D4C7,Getriebe_AL551_951_D4_C7,Getriebe_DL501_C7,Getriebe_VL381_C7
 SG_ TSK_Decel_Req_02 : 56|8@1+ (0.024,-3.984) [-3.984|2.136] "Unit_MeterPerSeconSquar"  Gateway_D4C7

BO_ 1716 VIN_01: 8 Gateway_D4C7
 SG_ VIN_01_MUX M  : 0|2@1+ (1,0) [0|3] ""  Airbag_D4,EPB_D4,LWS_D4,SCR_C7,SCU_D4
 SG_ KS_Secret_1 m0  : 8|8@1+ (1,0) [0|255] ""  Airbag_D4,EPB_D4
 SG_ VIN_4 m1  : 8|8@1+ (1,0) [0|255] ""  Airbag_D4,EPB_D4,SCR_C7
 SG_ VIN_11 m2  : 8|8@1+ (1,0) [0|255] ""  Airbag_D4,EPB_D4,SCR_C7
 SG_ KS_Secret_2 m0  : 16|8@1+ (1,0) [0|255] ""  Airbag_D4,EPB_D4
 SG_ VIN_5 m1  : 16|8@1+ (1,0) [0|255] ""  Airbag_D4,EPB_D4,SCR_C7
 SG_ VIN_12 m2  : 16|8@1+ (1,0) [0|255] ""  Airbag_D4,EPB_D4,SCR_C7
 SG_ KS_Secret_3 m0  : 24|8@1+ (1,0) [0|255] ""  Airbag_D4,EPB_D4
 SG_ VIN_6 m1  : 24|8@1+ (1,0) [0|255] ""  Airbag_D4,EPB_D4,SCR_C7
 SG_ VIN_13 m2  : 24|8@1+ (1,0) [0|255] ""  Airbag_D4,EPB_D4,SCR_C7
 SG_ KS_Secret_4 m0  : 32|8@1+ (1,0) [0|255] ""  Airbag_D4,EPB_D4
 SG_ VIN_7 m1  : 32|8@1+ (1,0) [0|255] ""  Airbag_D4,EPB_D4,SCR_C7
 SG_ VIN_14 m2  : 32|8@1+ (1,0) [0|255] ""  Airbag_D4,EPB_D4,LWS_D4,SCR_C7,SCU_D4
 SG_ VIN_1 m0  : 40|8@1+ (1,0) [0|255] ""  Airbag_D4,EPB_D4,SCR_C7
 SG_ VIN_8 m1  : 40|8@1+ (1,0) [0|255] ""  Airbag_D4,EPB_D4,SCR_C7
 SG_ VIN_15 m2  : 40|8@1+ (1,0) [0|255] ""  Airbag_D4,EPB_D4,LWS_D4,SCR_C7,SCU_D4
 SG_ VIN_2 m0  : 48|8@1+ (1,0) [0|255] ""  Airbag_D4,EPB_D4,SCR_C7
 SG_ VIN_9 m1  : 48|8@1+ (1,0) [0|255] ""  Airbag_D4,EPB_D4,SCR_C7
 SG_ VIN_16 m2  : 48|8@1+ (1,0) [0|255] ""  Airbag_D4,EPB_D4,LWS_D4,SCR_C7,SCU_D4
 SG_ VIN_3 m0  : 56|8@1+ (1,0) [0|255] ""  Airbag_D4,EPB_D4,SCR_C7
 SG_ VIN_10 m1  : 56|8@1+ (1,0) [0|255] ""  Airbag_D4,EPB_D4,SCR_C7
 SG_ VIN_17 m2  : 56|8@1+ (1,0) [0|255] ""  Airbag_D4,EPB_D4,LWS_D4,SCR_C7,SCU_D4

BO_ 1414 SelectorLever_02: 8 Getriebe_AL551_951_D4_C7
 SG_ WH_KD_Error : 63|1@1+ (1.0,0.0) [0.0|1] ""  Gateway_D4C7

BO_ 1318 BCM: 8 XXX
 SG_ INVERTED_Indicator_ACTIVE : 4|1@0+ (1,0) [0|1] "" XXX
 SG_ TURNSTALK_LEFT : 26|1@0+ (1,0) [0|1] "" XXX
 SG_ TURNSTALK_RIGHT : 27|1@0+ (1,0) [0|1] "" XXX
 SG_ Indicator_LEFT : 34|1@0+ (1,0) [0|1] "" XXX
 SG_ Indicator_RIGHT : 35|1@0+ (1,0) [0|1] "" XXX
 SG_ UNKNOWN_DRIVER_DOOR_RELATED : 43|1@0+ (1,0) [0|1] "" XXX

VAL_ 134 LWI_Sensorstatus 0 "iO" 1 "Not Calibrated" ;
VAL_ 134 LWI_QBit_Sub_Data 0 "LWS-Subinfo 'real' (SteeringWheelAngleInformation ADS-Suitable) " 1 "LWS-Subinfo 'simuliert' (SteeringWheelAngleInformation Not ADS-Suitable )" ;
VAL_ 134 LWI_QBit_SteeringWheelAngle 0 "g�ltiger Value" 1 "Outside The Spezifikation" ;
VAL_ 134 LWI_SteeringWheelAngle 8190 "Init" 8191 "Error" ;
VAL_ 134 LWI_VZ_SteeringWheelAngle 0 "Positive_Left_From_The_ZeroPosition" 1 "Negative" ;
VAL_ 134 LWI_VZ_SteeringWheelAngle_Speed 0 "Positive_Left_From_The_ZeroPosition" 1 "Negative" ;
VAL_ 134 LWI_SteeringWheelAngle_Speed 510 "Init" 511 "Error" ;
VAL_ 128 MO_Torque_o_ex 1022 "Init" 1023 "Error" ;
VAL_ 128 MO_Torque_m_ex 1022 "Init" 1023 "Error" ;
VAL_ 128 MO_Torque_Loss 1022 "Init" 1023 "Error" ;
VAL_ 128 MO_Torque_Limit 1022 "Init" 1023 "Error" ;
VAL_ 128 MO_Torque_DriverDemand 1022 "Init" 1023 "Error" ;
VAL_ 128 MO_Kickdown 0 "No Kickdown" 1 "Kickdown" ;
VAL_ 128 MO_KD_Error 0 "No_KD_Error" 1 "KD_Error" ;
VAL_ 129 MO_Torque_ZWR 1022 "Init" 1023 "Error" ;
VAL_ 129 MO_Torque_Target 1022 "Init" 1023 "Error" ;
VAL_ 129 MO_Torque_Actual 1022 "Init" 1023 "Error" ;
VAL_ 129 MO_Status_CylDeact_01 0 "All Cylinder brennen" 1 "AtLeast On Cylinder Was SwitchedOff" ;
VAL_ 129 MO_Status_NormalOperation_01 0 "No NormalOperation" 1 "NormalOperation Reached" ;
VAL_ 129 MO_StartStop_Status 0 "System_in_diesem_TERM15_Cycle_Not_Available" 1 "System_Active_No_Enable_By_StartStop_Koordinator" 2 "System_Active_All Enables_liegen_Before" 3 "System_Active_AtLeast_A_Enable_Missing" ;
VAL_ 129 MO_StartStop_EngineStop 0 "Engine_Stop_Inactive" 1 "Engine_Stop_Active" ;
VAL_ 129 MO_StartStop_Restart 0 "Restart_Inactive" 1 "Restart_Active" ;
VAL_ 129 MO_Ext_E_Journey_Active 0 "Feedback_E_PushButton_Off " 1 "Feedback_E_PushButton_On" ;
VAL_ 129 MO_GearPosition 0 "Gear_N" 1 "Gear_1" 2 "Gear_2" 3 "Gear_3" 4 "Gear_4" 5 "Gear_5" 6 "Gear_6" 7 "Gear_7" 8 "Gear_8" 12 "IntermediateGearPosition" 13 "Gear_R" 14 "ActualGear_Not_Defined" 15 "Error" ;
VAL_ 129 MO_StartStop_DriverDemand 0 "Init" 1 "StopInhibit_By_Driver" 2 "StopEnable_By_Driver" 3 "StopRequest_By_Driver" ;
VAL_ 261 MO_QBit_AccelPedalValues_01 0 "Valid_Value" 1 "Substitute_Init_Or_ErrorValue" ;
VAL_ 261 MO_QBit_EngineTorques 0 "Valid_Value" 1 "Substitute_Init_Or_ErrorValue" ;
VAL_ 261 MO_QBit_Driver_Brakes 0 "Valid_Value" 1 "Substitute_Init_Or_ErrorValue" ;
VAL_ 261 MO_QBit_Rpm_01 0 "Valid_Value" 1 "Substitute_Init_Or_ErrorValue" ;
VAL_ 261 MO_Rpm_01 65535 "Error" ;
VAL_ 261 MO_Torque_In_Idle 0 "No_Idle" 1 "Idle" ;
VAL_ 261 MO_Interlock 0 "InterlockSwitch Not bet�tigt" 1 "InterlockSwitch bet�tigt" ;
VAL_ 261 MO_BLS 0 "No Brakes" 1 "Brake bet�tigt" ;
VAL_ 261 MO_Driver_Brakes 0 "No Brakes" 1 "Brake bet�tigt" ;
VAL_ 261 MO_Consistency_BrakePedal 0 "BrakePedalInformation_Plausible" 1 "BrakePedalInformation_Implausible" ;
VAL_ 261 MO_Clutch_Switch 0 "Switch sagt Not bet�tigt (Eingekuppelt)" 1 "Switch sagt bet�tigt (Disengaged)" ;
VAL_ 261 MO_Timeout_ESP 0 "Reception i.O." 1 "Timeout" ;
VAL_ 261 MO_Engine_Running 0 "Engine l�uft Not" 1 "Engine l�uft autark And Stable And May mechanisch belastet Become" ;
VAL_ 261 MO_TargetRpm_Idle 255 "Error" ;
VAL_ 261 MO_AccelPedalRaw_01 255 "Error" ;
VAL_ 261 MO_First_InaccurateThreshold 0 "Accurate" 1 "Torques ungenauer >8%" ;
VAL_ 261 MO_QBit_Stressfaktor 0 "Valid_Value" 1 "Substitute_Init_Or_ErrorValue" ;
VAL_ 263 MO_ActualGear 0 "No_Gear_Engaged" 1 "Gear_1" 2 "Gear_2" 3 "Gear_3" 4 "Gear_4" 5 "Gear_5" 6 "Gear_6" ;
VAL_ 263 MO_TargetGear 0 "No_Recommendation" 1 "Gear_1" 2 "Gear_2" 3 "Gear_3" 4 "Gear_4" 5 "Gear_5" 6 "Gear_6" ;
VAL_ 263 MO_OilPressure 255 "Error" ;
VAL_ 263 MO_DisplayRpm 4095 "Error" ;
VAL_ 263 MO_ShiftRecommend_Available 0 "Not_Available" 1 "Available" ;
VAL_ 263 MO_BoostPressure 511 "Error" ;
VAL_ 263 MO_KVS_Overflow 0 "No Overflow" 1 "FuelConsumptionSignals AtLeast 1x �bergelaufen" ;
VAL_ 782 MO_ETermCommLeiRed 0 "No_PowerLimit" 1 "PowerLimit_75" 2 "PowerLimit_50" 3 "PowerLimit_25" ;
VAL_ 782 MO_Enable_Recup 0 "Recuperation-Mode Off" 1 "Recommendation VoltageIncrease" 2 "Recommendation VoltageDecrease" 3 "RecuperationMode Active, VoltageVariation Not Necessary" ;
VAL_ 782 MO_Climate_Interv 0 "No Intervention" 1 "AcCompressor SwitchOff" 2 "AcCompressor Leistungsreduzierung" 3 "AcCompressor DueTo The HotWarningPreWarning SwitchOff" ;
VAL_ 782 MO_Status_NormalOperation_02 0 "No NormalOperation" 1 "NormalOperation Reached" ;
VAL_ 782 MO_Prio_MIN_RequestedRpm 0 "Request" 1 "Forced" ;
VAL_ 782 MO_Enable_Crank 0 "Start Not Allowed�ssig" 1 "StartEnable" ;
VAL_ 782 MO_Aussp_Crank 0 "Engine l�uft Not Stable" 1 "Starter LeaveLane (Engine l�uft Stable)" ;
VAL_ 782 MO_MAX_RequestedRpm 511 "Error" ;
VAL_ 782 MO_Prio_MAX_RequestedRpm 0 "Request" 1 "Forced" ;
VAL_ 782 MO_AirPath_Active 0 "No Intervention Or Only Intervention �Range Z�ndpfad" 1 "Intervention �Range AirPath" ;
VAL_ 782 MO_v_Limit_Active 0 "Inactive" 1 "Active" ;
VAL_ 782 MO_v_Limit_Activatable 0 "V-Limit Not m�glich" 1 "V-Limit m�glich" ;
VAL_ 782 MO_Inhibit_EKP 0 "Actuation zugelassen" 1 "Actuation Prohibited" ;
VAL_ 782 MO_Req_Pruefimpuls 0 "No Request" 1 "Request" ;
VAL_ 782 MO_Req_TERM75 0 "Request TERM75 SwitchOff" 1 "Request TERM75 SwitchOn" ;
VAL_ 782 MO_Charisma_DrivePr 0 "Not_Occupied" 1 "Programm_1" 2 "Programm_2" 3 "Programm_3" 4 "Programm_4" 5 "Programm_5" 6 "Programm_6" 7 "Programm_7" ;
VAL_ 782 MO_Charisma_Status 0 "Init" 1 "Available" 2 "Not_Available" 3 "Asynchronous_By_DriverDemand" ;
VAL_ 782 MO_Charisma_Changeover 0 "Idle" 1 "Detection_ChangeoverPrompt" 2 "ControlMessage_Not_Defined" 3 "Changeover_Delayed" ;
VAL_ 782 MO_Handshake_STH 0 "No EKP-Actuation By STH-Request" 1 "EKP-Actuation By STH-Request" ;
VAL_ 782 MO_MIN_RequestedRpm 255 "Error" ;
VAL_ 1088 MO_RadiatorFan_MUX 0 "RadiatorFan_1" 1 "RadiatorFan_2" ;
VAL_ 1088 MO_RadiatorFan_1 126 "Init" 127 "Error" ;
VAL_ 1088 MO_RadiatorFan_2 126 "Init" 127 "Error" ;
VAL_ 1088 MO_HYB_Status_HV_Charge 0 "HV-Charge_Not_Necessary" 1 "HV-Charge_Necessary_Enables_Required" 2 "HV-Charge laeuf" 3 "HV-Charge_erfolgreich_EngineStart_Possible" 4 "HV_Charge_Aborted" ;
VAL_ 1088 WIV_Display_Active 0 "Display Off" 1 "WIV Display Active" ;
VAL_ 1088 WIV_Oelmin_Warn 0 "in_Order" 1 "Warning" ;
VAL_ 1088 WIV_SensorError 0 "in_Order" 1 "Sensor_Defective" ;
VAL_ 1088 WIV_Tilt 0 "Vehicle_Straight" 1 "Vehicle_in_Tilt" ;
VAL_ 1088 MO_State_HWP 0 "HWP_Not_schaltbar" 1 "HWP_Delivers_Not" 2 "HWP_Delivers" 3 "Reserved" ;
VAL_ 1088 WIV_OilSystem_Active 0 "Display_Off" 1 "Display_Active" ;
VAL_ 1088 WIV_Not_AtOperatingTemp 0 "Engine_warm" 1 "Engine_Not_AtOperatingTemp" ;
VAL_ 1088 WIV_Overfill_Warn 0 "in_Order" 1 "OverfillWarning" ;
VAL_ 1088 WIV_Running_Engine 0 "Measurement_Possible" 1 "Measurement_Not_Possible" ;
VAL_ 1088 MO_HYB_Text_1 0 "No_Text" 1 "Text_Display" ;
VAL_ 1088 MO_HYB_Text_2 0 "No_Text" 1 "Text_Display" ;
VAL_ 1088 MO_HYB_Text_3 0 "No_Text" 1 "Text_Display" ;
VAL_ 1088 MO_Text_EngineStart 0 "No_Display" 1 "Engine_In_StopOperation" 2 "StartStop_sicherheitsbedingt_Deactivated" 3 "System_fordert_Restart" 5 "EngineRunning_Needed" 9 "Unerwuenschter_EngineStandstill" 12 "Engine_Starting" 13 "Clutch_Press" 14 "SelectorLever_in_PN_Position" 15 "Brake_Press" ;
VAL_ 1088 MO_HYB_Text_5 0 "No_Text" 1 "Text_Display" ;
VAL_ 1088 MO_HYB_Text_6 0 "No_Text" 1 "Text_Display" ;
VAL_ 1088 MO_HYB_Text_7 0 "No_Text" 1 "Text_Display" ;
VAL_ 1088 WIV_OilDyn_avl 0 "OilDyn_Not_Present" 1 "OilDyn_Present" ;
VAL_ 1088 MO_SystemLamp 0 "Lamp Off" 1 "Lamp On" ;
VAL_ 1088 MO_OBD2_Lamp 0 "Lamp Off" 1 "Lamp On" ;
VAL_ 1088 MO_HotWarningLamp 0 "Lamp Off" 1 "Lamp On" ;
VAL_ 1088 MO_Particle_Lamp 0 "Lamp Off" 1 "Lamp On" ;
VAL_ 1088 WIV_OilLevel_Not_Present 0 "�lstand Present" 1 "�lstand Not Present" ;
VAL_ 1088 WIV_RefillDisplay_On 0 "No_RefillDisplay" 1 "RefillDisplay" ;
VAL_ 1088 WIV_Overfill_Deactivated 0 "OverfillWarning_At_Cluster_Active" 1 "OverfillWarning_At_Cluster_Deactivated" ;
VAL_ 1088 WIV_Underfill_Warn 0 "in_Order" 1 "UnderfillWarning" ;
VAL_ 1088 MO_FuelCap_Lamp 0 "Lamp Off" 1 "Lamp On" ;
VAL_ 1088 MO_Text_FuelCapWarn 0 "No Text" 1 "Display Text FuelCapWarning In Cluster" ;
VAL_ 1088 WIV_Enable_OilPressure_Engine 0 "OilPressureEvaluation_In_Cluster" 1 "OilPressureEvaluation_In_MSG" ;
VAL_ 1088 WIV_OilPressure_Warn_Engine 0 "No_Warning" 1 "Low_OilPressureStage_Not_Reached " ;
VAL_ 1088 MO_Avus_EngineProtection 0 "No Warning" 1 "RpmWarning Stage 1" 2 "RpmWarning Stage 2" 3 "RpmWarning Stage 3" ;
VAL_ 1088 MO_HYB_ReadyToDrive 0 "No_ReadyToDrive" 1 "ReadyToDrive" ;
VAL_ 1600 MO_QBit_IntakeAir_Temp 0 "Valid_Value" 1 "Substitute_Init_Or_ErrorValue" ;
VAL_ 1600 MO_QBit_Oil_Temp 0 "Valid_Value" 1 "Substitute_Init_Or_ErrorValue" ;
VAL_ 1600 MO_QBit_Coolant_Temp 0 "Valid_Value" 1 "Substitute_Init_Or_ErrorValue" ;
VAL_ 1600 MO_ActuatorTest_SoundActuator 0 "No_ActuatorTest" 1 "Request_Of_ActuatorTest" ;
VAL_ 1600 MO_HYB_Error_HV_Network 0 "i_O" 1 "No_Regenerative_Operation_Possible" ;
VAL_ 1600 MO_Active_GearboxHeat 0 "No_Valve_Actuate" 1 "Valve_muss_Actuated_Become" ;
VAL_ 1600 MO_ShutOffValve_Open 0 "Not_Available" 1 "Actuation_Valve_Permitted" 2 "Valve_Open_Or_Opened" 3 "Valve_Close_Or_Closed" ;
VAL_ 1600 MO_IntakeAir_Temp 254 "Init" 255 "Error" ;
VAL_ 1600 MO_Oil_Temp 253 "Not_Fitted" 254 "Init" 255 "Error" ;
VAL_ 1600 MO_Coolant_Temp 254 "Init" 255 "Error" ;
VAL_ 1600 MO_AltitudeInfo 255 "Error" ;
VAL_ 1600 MO_Kennfeldk 0 "No Kennfeldk�hlung Present" 1 "Kennfeldk�hlung Present" ;
VAL_ 1600 MO_VersionInfo 0 "To Projektbeginn 'aufger�umter CAN' " 1 "Engine_03_With_10ms" 16 "MQB_With_neuer_Momentenschnittstelle" ;
VAL_ 1600 MO_Gearbox_Cool 0 "Not_Cool" 1 "Cool" ;
VAL_ 1600 MO_HeatingPumpActuation 15 "Not_Fitted" ;
VAL_ 1600 MO_VoltageReq 0 "No_Request" 1 "Request" ;
VAL_ 1607 MO_ITM_Coolant_Temp 0 "Not_Fitted" 2 "Error" ;
VAL_ 1607 MO_E85_Sensor 13 "Not_Fitted" 15 "Error" ;
VAL_ 1607 SCR_Disp_Motorstarts 15 "No Restrict�nkung (Display Range)" ;
VAL_ 1607 SCR_Range 32767 "Init" ;
VAL_ 1607 SCR_WarningLevel_1 0 "Not Active" 1 "WarningLevel 1 Active" ;
VAL_ 1607 SCR_WarningLevel_2 0 "Not Active" 1 "WarningLevel 2 Active" ;
VAL_ 1607 SCR_Text 0 "No Text" 1 "WarningText 1" 2 "WarningText 2" 3 "Hinweistext (Only AUDI)" 4 "Reserve" 5 "WarningText 'SCR-SystemError Stage 1'" 6 "WarningText 'SCR-SystemError Stage 2'" ;
VAL_ 1607 SCR_Acoustic 0 "No Acoustic" 1 "Acoustic 1" 2 "Acoustic 2" 3 "Acoustic_At_Notice_(VW)" ;
VAL_ 1607 MO_Kraftstofffilter_Water 0 "No_Display" 1 "Abscheidevolumen_erschoepft" ;
VAL_ 1607 SCR_SystemError 0 "Warning_Not_Active" 1 "Warning_Active" ;
VAL_ 1607 SCR_Inducement_Strategy 0 "Restart_Strategy" 1 "Reduced_Drivability_Strategy" ;
VAL_ 1607 MO_CO2_Factor 0 "Not_Fitted" 4095 "Error" ;
VAL_ 1607 MO_MKB_MUX 0 "MKB_01" 1 "MKB_02" 2 "MKB_03" 3 "MKB_04" ;
VAL_ 1607 MO_MKB_01 0 "Minus" 1 "A" 2 "B" 3 "C" 4 "D" 5 "E" 6 "F" 7 "G" 8 "H" 9 "I" 10 "J" 11 "K" 12 "L" 13 "M" 14 "N" 15 "O" 16 "P" 17 "Q" 18 "R" 19 "S" 20 "T" 21 "U" 22 "V" 23 "W" 24 "X" 25 "Y" 26 "Z" 27 "Space" 28 "Space" 29 "Space" 30 "Space" 31 "Underscore" ;
VAL_ 1607 MO_MKB_02 0 "Minus" 1 "A" 2 "B" 3 "C" 4 "D" 5 "E" 6 "F" 7 "G" 8 "H" 9 "I" 10 "J" 11 "K" 12 "L" 13 "M" 14 "N" 15 "O" 16 "P" 17 "Q" 18 "R" 19 "S" 20 "T" 21 "U" 22 "V" 23 "W" 24 "X" 25 "Y" 26 "Z" 27 "Space" 28 "Space" 29 "Space" 30 "Space" 31 "Underscore" ;
VAL_ 1607 MO_MKB_03 0 "Minus" 1 "A" 2 "B" 3 "C" 4 "D" 5 "E" 6 "F" 7 "G" 8 "H" 9 "I" 10 "J" 11 "K" 12 "L" 13 "M" 14 "N" 15 "O" 16 "P" 17 "Q" 18 "R" 19 "S" 20 "T" 21 "U" 22 "V" 23 "W" 24 "X" 25 "Y" 26 "Z" 27 "Space" 28 "Space" 29 "Space" 30 "Space" 31 "Underscore" ;
VAL_ 1607 MO_MKB_04 0 "Minus" 1 "A" 2 "B" 3 "C" 4 "D" 5 "E" 6 "F" 7 "G" 8 "H" 9 "I" 10 "J" 11 "K" 12 "L" 13 "M" 14 "N" 15 "O" 16 "P" 17 "Q" 18 "R" 19 "S" 20 "T" 21 "U" 22 "V" 23 "W" 24 "X" 25 "Y" 26 "Z" 27 "Space" 28 "Space" 29 "Space" 30 "Space" 31 "Underscore" ;
VAL_ 276 MO_Sig_AccelPedalGradient 0 "AccelPedalGradient Positive" 1 "AccelPedalGradient Negative" ;
VAL_ 276 MO_BKV_VacuumWarning 0 "VacuumSupply_iO" 1 "VacuumSupply_niO" ;
VAL_ 276 MO_CylinderDeactivation 0 "FullEngineOperation_VMB" 1 "OverGear_HMB_in_VMB" 2 "OverGear_VMB_in_HMB" 3 "Halbmotorbetrieb_HMB" ;
VAL_ 276 MO_AccelPedalGradient 255 "Error" ;
VAL_ 276 MO_OverrunFuelCut 0 "No_OverrunFuelCut" 1 "OverrunFuelCut_Active" ;
VAL_ 276 MO_rel_ManifoldPressure 0 "Init_Overpressure" 63 "Error" ;
VAL_ 276 MO_rel_ManifoldPressure_gem_err 0 "errechnet" 1 "Measured" ;
VAL_ 276 MO_BKV_Vacuum 255 "Error" ;
VAL_ 1648 MO_Count_Abgesch_Cyl 0 "FullEngineOperation" 1 "1_Cylinder_SwitchedOff" 2 "2_Cylinder_SwitchedOff" 3 "3_Cylinder_SwitchedOff" 4 "4_Cylinder_SwitchedOff" 5 "5_Cylinder_SwitchedOff" 6 "6_Cylinder_SwitchedOff" 7 "8_Cylinder_SwitchedOff" ;
VAL_ 1648 MO_CylDeact_Texte 0 "No_Texte" 1 "CylinderDeactivation_Deactivate" 2 "CylinderDeactivation_Activate" 3 "CylinderDeactivation_unruhig" ;
VAL_ 1648 MO_E85_BS_Texte 0 "No Text" 1 "FlexFuel Warm_Up_ Lamp" 2 "FlexFuel Warning 3.Stage " 3 "FlexFuel Warning 1.Stage " 4 "FlexFuel Warning 2.Stage " 5 "FlexFuel Warning 4.Stage " ;
VAL_ 1648 MO_Rpm_Warning 0 "No_WarningNote_Display" 1 "WarningNote_Display" ;
VAL_ 1010 MO_SCR_TankHeater 0 "Heating_Off" 1 "Heating_On" ;
VAL_ 1010 MO_SCR_DosingPump_State 0 "Free" 1 "RpmControl" 2 "PressureControl_Slow" 3 "PressureControl_Fast" 4 "Pump_Stop" 5 "ReverseOperation" 6 "verzoegerter_ReverseOperation" 7 "Pump_Heat" ;
VAL_ 1010 MO_SCR_LineHeater 0 "Heating_Off" 1 "Heating_On" ;
VAL_ 1010 MO_SCR_DosingPump_Wartezeit 125 "Not_Fitted" 127 "Error" ;
VAL_ 1010 MO_SCR_TransferPump 0 "Pump_Off" 1 "Pump_On" ;
VAL_ 1601 MO_Factor_Torques 0 "Not Occupied" 1 "Factor: x 0,5Nm" 2 "Factor: x 1,0Nm" 3 "Factor: x 2,0Nm" ;
VAL_ 1601 MO_HybridVehicle 0 "No_HybridVehicle" 1 "Mild_Hybrid" 2 "Full_Hybrid" ;
VAL_ 1601 MO_Gearbox_Code 2 "DL501" 4 "VL381" 10 "AL651" 11 "AL551, AL951, AL1000-8A" 12 "PDK_PAG" 13 "AL551_Hybrid" 15 "ManualGearbox (konventionell)" 16 "AQ250" 17 "AQ450" 18 "DQ200" 19 "DQ250" 20 "DQ500" 21 "SQ100" 22 "SQ200" ;
VAL_ 1601 MO_StartStop_Coded 0 "Start_Stop_Not_Fitted" 1 "Start_Stop_Fitted" ;
VAL_ 1601 MO_FuelType 0 "Diesel" 1 "Petrol" 2 "CNG" 3 "NaturalGas" 4 "Hydrogen" ;
VAL_ 1601 MO_IntakeSystem 0 "Turbo" 1 "Sauger" ;
VAL_ 1601 MO_InjectionType 0 "MPI" 1 " FSI / TDI" ;
VAL_ 969 MOS_KD_Error 0 "No_KD_Error" 1 "KD_Error" ;
VAL_ 1696 NV_Active 0 "NV Not Active" 1 "NV Active" ;
VAL_ 1696 NV_Texte 0 "No_Text" 1 "LowBeam_SwitchOn" 2 "Fussgaengermarkierung_Not_Available" 3 "To_Time_Not_Available" 4 "SystemError" ;
VAL_ 1696 NV_Chime 0 "No_Chime" 1 "Chime_leise" 2 "Chime_Average" 3 "Chime_laut" ;
VAL_ 1696 NV_Symbol 0 "No_Symbol_Display" 1 "Symbol_For_erkanntes_Object_Display" ;
VAL_ 1696 NV_Notices 0 "No_Display" 1 "Disclaimer" 2 "Pedestrian_Markierung_Not_Available" 3 "Nachtsichtsystem_Is_Initialised" ;
VAL_ 1696 NV_Piktogramm_Active 0 "No_DisplayPriority" 1 "DisplayPriority" ;
VAL_ 1696 NV_Acoustic_Deactivated_Icon 0 "Off" 1 "On" ;
VAL_ 1696 NV_FGM_Deactivated_Icon 0 "Off" 1 "On" ;
VAL_ 1696 NV_KD_Error 0 "No_KD_Error" 1 "KD_Error" ;
VAL_ 1753 NMH_EPB_Start_1 1 "State Start (<--Sleep)" ;
VAL_ 1753 NMH_EPB_Start_2 1 "State Start (<--Prepare to Sleep)" ;
VAL_ 1753 NMH_EPB_Normal_Mode_1 1 "State Normal Mode (<-- Start)" ;
VAL_ 1753 NMH_EPB_Normal_Mode_2 1 "State Normal Mode (<-- Ready to Sleep)" ;
VAL_ 1753 NMH_EPB_Per_WakeUp 0 "If Function-Wakeup" 1 "CAN-Wakeup" 2 "Periphrie-Wakeup Cause Not Known" 3 "Terminal 15 HW (If Present)" 4 "t.b.d." 5 "Switch_EPB" ;
VAL_ 1753 NMH_EPB_Func_WakeUp 0 "If Peripherals-Wakeup" ;
VAL_ 1753 NMH_EPB_NM_Active_Terminal_15 1 "Terminal 15 ON" ;
VAL_ 1753 NMH_EPB_NM_Active_Diagnostics 1 "Diagnostics At Term 15 Off" ;
VAL_ 1753 NMH_EPB_NM_Active_Start 1 "State 'START' (NM-high)" ;
VAL_ 1753 NMH_EPB_NM_Active_Switch 1 "Switch Active" ;
VAL_ 1753 NMH_EPB_NM_Active_Bedarf_Display 1 "Cluster-Display EPB" ;
VAL_ 1753 NMH_EPB_NM_Active_v_Greater_Null 1 "v > 0" ;
VAL_ 1753 NMH_EPB_No_NL 1 "No lokaler RunOn" ;
VAL_ 1753 NMH_EPB_NL_Temp_Model 1 "TemperatureModel Active" ;
VAL_ 1753 NMH_EPB_NL_AutoAdjust 0 "AutoAdjust_Not_Active" 1 "AutoAdjust_Active" ;
VAL_ 1753 NM_EPB_SignalError 1 "Active_SignalError_Entered" ;
VAL_ 1753 NMH_EPB_TimeOut_Error 1 "Active Timeout FaultMemoryEntry  " ;
VAL_ 1753 NMH_EPB_CAN_Diag_Deactivated 1 "CAN-Diagnostics Deactivated" ;
VAL_ 1753 NMH_EPB_CompressorProtection 1 "KS Active" ;
VAL_ 1753 NMH_EPB_Mute_Mode 1 "MuteMode Active" ;
VAL_ 1753 NMH_EPB_Transport_Mode 1 "TransportMode Active" ;
VAL_ 1753 NMH_EPB_ShutoffStage_Active 1 "ShutoffStage Active" ;
VAL_ 1753 NMH_EPB_SingleWire_Error 1 "SingleWireMode Detected" ;
VAL_ 1753 NMH_EPB_LocalActive 0 "Was Not LocalActive" 1 "Was LocalActive" ;
VAL_ 1753 NMH_EPB_SubsystemActive 0 "Subsystem Was Not LocalActive" 1 "Was LocalActive" ;
VAL_ 1728 NMH_GW_Start_1 1 "State Start (<--Sleep)" ;
VAL_ 1728 NMH_GW_Start_2 1 "State Start (<--Prepare to Sleep)" ;
VAL_ 1728 NMH_GW_Normal_Mode_1 1 "State Normal Mode (<-- Start)" ;
VAL_ 1728 NMH_GW_Normal_Mode_2 1 "State Normal Mode (<-- Ready to Sleep)" ;
VAL_ 1728 NMH_GW_Per_WakeUp 0 "If_FunctionWakeup" 1 "CAN_Wakeup__Weckendes_CAN_Segment_siehe_NMH_GW_WakeUp_CAN_Bus" 2 "P_WakeUp_Cause_Unknown" 3 "Terminal_15HW__If_Present" 4 "MOST_Wakeup" 5 "LIN_Wakeup" 6 "TERM30_Reset" ;
VAL_ 1728 NMH_GW_Func_WakeUp 0 "If_Peripherals_Wakeup" 1 "Funktionswakeup_EM" 2 "Car_Wakeup_Received" 3 "VNSM_VehicleNetworkStateManager" 4 "Alarm_RTC__Wecken_weil_Weckzeit_abgelaufen" 5 "Wecken_By_Diagnostics" ;
VAL_ 1728 NMH_GW_NM_Active_Terminal_15 1 "Terminal 15 ON" ;
VAL_ 1728 NMH_GW_NM_Active_Diagnostics 1 "Diagnostics At Term 15 Off" ;
VAL_ 1728 NMH_GW_NM_Active_Start 1 "State 'START' (NM-high)" ;
VAL_ 1728 NMH_GW_NM_Active_BDM 1 "BDM-Communication" ;
VAL_ 1728 NMH_GW_NM_Active_HazardFlash 1 "HazardFlash Active" ;
VAL_ 1728 NMH_GW_NM_Active_ESP 1 "ESP Active (Wakeup/Sleep-Concept)" ;
VAL_ 1728 NMH_GW_ShutoffStage_3 1 "BEM DueTo ShutoffStage 3 Active" ;
VAL_ 1728 NMH_GW_ECU_ErrorDuration 1 "BEM DueTo ControlUnitErrorDuration Active" ;
VAL_ 1728 NMH_GW_STH_Wakeup 1 "BEM Active DueTo Standheizungswakeup" ;
VAL_ 1728 NMH_GW_NL_Diagnostics 0 "No_Diagnostics_Active" 1 "Diagnostics_Was_Local_Active" ;
VAL_ 1728 NM_GW_SignalError 1 "Active_SignalError_Entered" ;
VAL_ 1728 NMH_GW_TimeOut_Error 1 "Active Timeout FaultMemoryEntry  " ;
VAL_ 1728 NMH_GW_CAN_Diag_Deactivated 1 "CAN Bus bezogene Eigendiagnose Deactivated" ;
VAL_ 1728 NMH_GW_CompressorProtection 1 "KS Active" ;
VAL_ 1728 NMH_GW_Mute_Mode 1 "MuteMode Active" ;
VAL_ 1728 NMH_GW_Transport_Mode 1 "TransportMode Active" ;
VAL_ 1728 NMH_GW_ShutoffStage_Active 1 "ShutoffStage Active" ;
VAL_ 1728 NMH_GW_SingleWire_Error 1 "SingleWireMode Detected" ;
VAL_ 1728 NMH_GW_ACAN 1 "ACAN Active (Wakeup/Sleep-Concept)" ;
VAL_ 1728 NMH_GW_ClusterCAN 1 "ClusterCAN Active (Wakeup/Sleep-Concept)" ;
VAL_ 1728 NMH_GW_ComfortCAN 1 "ComfortCAN Active (Wakeup/Sleep-Concept)" ;
VAL_ 1728 NMH_GW_Infotainment 1 "Infotainment Active (CAN Or MOST), Wakeup/Sleep-Concept" ;
VAL_ 1728 NMH_GW_Chassis 1 "BUS_Chassis_Active (Wakeup/Sleep-Concept)" ;
VAL_ 1728 NMH_GW_WakeUp_CAN_Bus 0 "Not zutreffend (No CAN-Wakeup bzw. CarWakeup)" 1 "Antriebs-CAN" 2 "Cluster-CAN" 3 "Comfort-CAN" 4 "Infotainment-CAN (If Available)" 5 "Fahrwerks-CAN" 6 "Diagnostics-CAN" ;
VAL_ 1730 NMH_GE_Start_1 1 "State Start (<--Sleep)" ;
VAL_ 1730 NMH_GE_Start_2 1 "State Start (<--Prepare to Sleep)" ;
VAL_ 1730 NMH_GE_Normal_Mode_1 1 "State Normal Mode (<-- Start)" ;
VAL_ 1730 NMH_GE_Normal_Mode_2 1 "State Normal Mode (<-- Ready to Sleep)" ;
VAL_ 1730 NMH_GE_Per_WakeUp 0 "If Funktionswakeup" 1 "CAN" 2 "P-Wakeup, Cause Not Known" 3 "TERM 15 HW (If Present)" ;
VAL_ 1730 NMH_GE_Func_WakeUp 0 "If Peripheriewakeup" 1 "End_N_HoldPhase" ;
VAL_ 1730 NMH_GE_NM_Active_Terminal_15 1 "Terminal 15 On" ;
VAL_ 1730 NMH_GE_NM_Active_Diagnostics 1 "Diagnostics At Term 15 Off" ;
VAL_ 1730 NMH_GE_NM_Active_Start 1 "State 'START' (NM-high)" ;
VAL_ 1730 NMH_GE_N_HoldPhase 0 "No_N_HoldPhase" 1 "N_HoldPhase_Active" ;
VAL_ 1730 NMH_GE_No_NL 1 "No lokaler RunOn" ;
VAL_ 1730 NMH_GE_NL_Data_EEPROM 1 "EEPROM Datenspeicherung" ;
VAL_ 1730 NM_GE_SignalError 1 "Active_SignalError_Entered" ;
VAL_ 1730 NMH_GE_TimeOut_Error 1 "Active Timeout FaultMemoryEntry  " ;
VAL_ 1730 NMH_GE_CAN_Diag_Deactivated 1 "CAN-Diagnostics Deactivated" ;
VAL_ 1730 NMH_GE_CompressorProtection 1 "KS Active" ;
VAL_ 1730 NMH_GE_Mute_Mode 1 "MuteMode Active" ;
VAL_ 1730 NMH_GE_Transport_Mode 1 "TransportMode Active" ;
VAL_ 1730 NMH_GE_ShutoffStage_Active 1 "ShutoffStage Active" ;
VAL_ 1730 NMH_GE_SingleWire_Error 1 "SingleWireMode Detected" ;
VAL_ 1730 NMH_GE_LocalActive 0 "Was Not LocalActive" 1 "Was LocalActive" ;
VAL_ 1730 NMH_GE_SubsystemActive 0 "Subsystem Was Not LocalActive" 1 "Was LocalActive" ;
VAL_ 1730 NMH_GSG_Subbusaktiv 0 "Subbus Inactive" 1 "Subbus Active" ;
VAL_ 1729 NMH_MO_Start_1 1 "State Start (<--Sleep)" ;
VAL_ 1729 NMH_MO_Start_2 1 "State Start (<--Prepare to Sleep)" ;
VAL_ 1729 NMH_MO_Normal_Mode_1 1 "State Normal Mode (<-- Start)" ;
VAL_ 1729 NMH_MO_Normal_Mode_2 1 "State Normal Mode (<-- Ready to Sleep)" ;
VAL_ 1729 NMH_MO_Per_WakeUp 0 "If Function-Wakeup" 1 "CAN-Wakeup" 2 "Peripherals-Wakeup Cause Not Known" 3 "Terminal 15 HW (If Present)" 4 "analog (AuxHeater/DoorContact)(Only MED9)" ;
VAL_ 1729 NMH_MO_Func_WakeUp 0 "If_Peripherals_Wakeup" ;
VAL_ 1729 NMH_MO_NM_Active_Terminal_15 1 "Terminal 15 ON" ;
VAL_ 1729 NMH_MO_NM_Active_Diagnostics 1 "Diagnostics At Term 15 Off " ;
VAL_ 1729 NMH_MO_NM_Active_Start 1 "State 'START' (NM-high)" ;
VAL_ 1729 NMH_MO_NM_Active_EKP_Lead 1 "EKP-Lead" ;
VAL_ 1729 NMH_MO_NM_Active_STH_Operation 1 "STH-Operation" ;
VAL_ 1729 NMH_MO_NM_Active_HV_Shutdown 0 "No_RunOn" 1 "Shutdown_Active" ;
VAL_ 1729 NMH_MO_No_NL 1 "No lokaler RunOn" ;
VAL_ 1729 NMH_MO_NL_RadiatorFan 1 "K�hlerl�fter Control / AdditionalWaterPump Active" ;
VAL_ 1729 NMH_MO_NL_Diagnostics 1 "DiagnosticsFunctions Active" ;
VAL_ 1729 NMH_MO_NL_WFS 1 "WFS Active" ;
VAL_ 1729 NMH_MO_NL_EEPROM 1 "EEPROM Zugriffe RAM/ROM Tests" ;
VAL_ 1729 NMH_MO_NL_Other 1 "Other Nachl�ufe Active" ;
VAL_ 1729 NM_MO_SignalError 1 "Active_SignalError_Entered" ;
VAL_ 1729 NMH_MO_TimeOut_Error 1 "Active Timeout FaultMemoryEntry  " ;
VAL_ 1729 NMH_MO_CAN_Diag_Deactivated 1 "CAN-Diagnostics Deactivated" ;
VAL_ 1729 NMH_MO_CompressorProtection 1 "KS Active" ;
VAL_ 1729 NMH_MO_Mute_Mode 1 "MuteMode Active" ;
VAL_ 1729 NMH_MO_Transport_Mode 1 "TransportMode Active" ;
VAL_ 1729 NMH_MO_ShutoffStage_Active 1 "ShutoffStage Active" ;
VAL_ 1729 NMH_MO_SingleWire_Error 1 "SingleWireMode Detected" ;
VAL_ 1729 NMH_MO_LocalActive 0 "Was Not LocalActive" 1 "Was LocalActive" ;
VAL_ 1729 NMH_MO_SubsystemActive 0 "Subsystem Was Not LocalActive" 1 "Was LocalActive" ;
VAL_ 1736 NMH_MO_SL_Start_1 1 "State Start (<--Sleep)" ;
VAL_ 1736 NMH_MO_SL_Start_2 1 "State Start (<--Prepare to Sleep)" ;
VAL_ 1736 NMH_MO_SL_Normal_Mode_1 1 "State Normal Mode (<-- Start)" ;
VAL_ 1736 NMH_MO_SL_Normal_Mode_2 1 "State Normal Mode (<-- Ready to Sleep)" ;
VAL_ 1736 NMH_MO_SL_Per_WakeUp 0 "If Function-Wakeup" 1 "CAN-Wakeup" 2 "Peripherals-Wakeup Cause Not Known" 3 "Terminal 15 HW (If Present)" 4 "analog (AuxHeater/DoorContact)(Only MED9)" ;
VAL_ 1736 NMH_MO_SL_Func_WakeUp 0 "If Peripherals-Wakeup" ;
VAL_ 1736 NMH_MO_SL_TimeOut_Error 1 "Active Timeout FaultMemoryEntry  " ;
VAL_ 1736 NMH_MO_SL_CAN_Diag_Deactivated 1 "CAN-Diagnostics Deactivated" ;
VAL_ 1736 NMH_MO_SL_CompressorProtection 1 "KS Active" ;
VAL_ 1736 NMH_MO_SL_Mute_Mode 1 "MuteMode Active" ;
VAL_ 1736 NMH_MO_SL_Transport_Mode 1 "TransportMode Active" ;
VAL_ 1736 NMH_MO_SL_ShutoffStage_Active 1 "ShutoffStage Active" ;
VAL_ 1736 NMH_MO_SL_BusError 1 "BusError" ;
VAL_ 1736 NMH_MO_Sl_LocalActive 0 "Was_Not_Local_Active" 1 "Was_Local_Active" ;
VAL_ 1736 NMH_MO_SL_SubsystemActive 0 "Subsystem Was Not LocalActive" 1 "Was LocalActive" ;
VAL_ 1782 NMH_SCR_Start_1 1 "State Start (<--Sleep)" ;
VAL_ 1782 NMH_SCR_Start_2 1 "State Start (<--Prepare to Sleep)" ;
VAL_ 1782 NMH_SCR_Normal_Mode_1 1 "State Normal Mode (<-- Start)" ;
VAL_ 1782 NMH_SCR_Normal_Mode_2 1 "State Normal Mode (<-- Ready to Sleep)" ;
VAL_ 1782 NMH_SCR_Car_WakeUp 1 "Car Wake Up" ;
VAL_ 1782 NMH_SCR_Per_WakeUp 0 "Function-WakeUp" 1 "CAN" 2 "P_WakeUp_Cause_Unknown" 3 "TERM_15_Hardware_If_Present" ;
VAL_ 1782 NMH_SCR_Func_WakeUp 0 "Peripheriewakeup" ;
VAL_ 1782 NMH_SCR_Terminal_15 1 "Terminal 15 On" ;
VAL_ 1782 NMH_SCR_Diagnostics 1 "Diagnostics At Term 15 Off" ;
VAL_ 1782 NMH_SCR_MinActiveTime 1 "Active" ;
VAL_ 1782 NMH_SCR_NL_Datem_EEPROM 0 "No_RunOn" 1 "EEPROM_schreibzugriff" ;
VAL_ 1782 NMH_SCR_SignalError 1 "Active_SignalError_Entered" ;
VAL_ 1782 NMH_SCR_TimeOut_Error 1 "Active Timeout FaultMemoryEntry" ;
VAL_ 1782 NMH_SCR_CAN_Diag_Deactivated 1 "CAN Bus bezogene Eigendiagnose Deactivated" ;
VAL_ 1782 NMH_SCR_CompressorProtection 1 "KS Active" ;
VAL_ 1782 NMH_SCR_Mute_Mode 1 "Mute Mode Active" ;
VAL_ 1782 NMH_SCR_Transport_Mode 1 "TransportMode Active" ;
VAL_ 1782 NMH_SCR_ShutoffStage_Active 1 "FunctionShutdown DueTo ShutoffShiftStage" ;
VAL_ 1782 NMH_SCR_BusError 1 "BusError" ;
VAL_ 1782 NMH_SCR_LocalActive 0 "Was_Not_Local_Active" 1 "Was_Local_Active" ;
VAL_ 1782 NMH_SCR_SubsystemActive 0 "Subsystem Was Not LocalActive" 1 "Was LocalActive" ;
VAL_ 913 OBD_ColdStart_Denominator 0 "Denominator_Not_hochzaehlen" 1 "Bedingungen_To_Inkr_Of_ColdStart_Denom_erf" ;
VAL_ 913 OBD_Minimum_Trip 0 "No_Min_Normed_Trip" 1 "Min_Normed_Trip" ;
VAL_ 913 OBD_Driving_Cycle 0 "No Driving Cycle Detected" 1 "DC Detected" ;
VAL_ 913 OBD_Warm_Up_Cycle 0 "No Warm Up Cycle Detected" 1 "Warm Up Cycle Detected" ;
VAL_ 913 OBD_Normed_Trip 0 "No Normed Trip" 1 "Normed Trip erf�llt" ;
VAL_ 803 PCF_ObjectStatus 0 "No_Relevant_Object_Detected" 1 "Relevant_Object_Preceding" 2 "Relevant_Object_Stationary" 3 "Relevant_Object_angehalten" 4 "Relevant_Object_entgegenkommend" 5 "Invalid" 6 "Invalid" 7 "Invalid" ;
VAL_ 803 PCF_Driver_Active_Detected 0 "Driver_Not_Active" 1 "Driver_Active" ;
VAL_ 803 PCF_Time_to_collision 255 "ObjectStatus=0x0__Or_Calculated_TTC_Value_Greater_As_MaximumValue" ;
VAL_ 803 PCF_v_rel 0 " ObjectStatus_0x0_Or _berechnete_v_rel_>= 0_(Object_entfernt_sich_Or_faehrt_vorraus_With v_Obj_=_v_ego)" ;
VAL_ 803 PCF_dy_Kollisionsueberdeckung 0 "No_Ueberdeckung_Or_At_ObjectStatus_0x0" 30 "Ueberdeckung_Greater_MaximumValue" 31 "Objekueberdeckung_Not_ermittelbar" ;
VAL_ 802 PCR_Sensorstatus 0 "Sensor_ok" 1 "Sensor_nok" ;
VAL_ 802 PCR_Obj_vx_rel 2047 "Error" ;
VAL_ 802 PCR_Obj_vy_rel 2047 "Error" ;
VAL_ 802 PCR_Obj_TTC 511 "Error" ;
VAL_ 802 PCR_Obj_Quality 127 "Error" ;
VAL_ 802 PCR_Crashwahrscheinlichkeit 127 "Error" ;
VAL_ 929 PSD_Pos_Segment_ID 0 "No Position gegeben" 1 "ErrorValue" ;
VAL_ 929 PSD_Pos_Location 0 "mehrdeutiger_Location" 1 "eindeutiger_Location" ;
VAL_ 929 PSD_Pos_Laengsfehler 0 "No Pr�diktion (off-road)" 1 "< 2m" 2 "< 5m" 3 "< 10m " 4 "< 20m" 5 "< 50m" 6 "> 50m " 7 "Not Allowed" ;
VAL_ 929 PSD_Segment_ID 0 "No SegmentInfo Present" 1 "ErrorValue" ;
VAL_ 929 PSD_Predecessor_Segment_ID 0 "No SegmentInformation Present" 1 "ErrorValue" ;
VAL_ 929 PSD_RoadClass 0 "Rest_FieldTrack_Schotterweg_PrivateRoad" 1 "LocationRoad" 2 "Bundes_CountryRoad" 3 "Motorway" ;
VAL_ 929 PSD_Ramp 0 "Road_With_OncomingTraffic" 1 "OpenJourney_OneWayStreet" 2 "Exit_OneWayStreet" 3 "OneWayStreet" ;
VAL_ 929 PSD_EndCurvature 255 "Straight" ;
VAL_ 929 PSD_EndCurvature_Sign 0 "Curvature_Positive" 1 "Curvature_Negative" ;
VAL_ 929 PSD_EndGradient 30 "Equal_Or_More_15_Percent_Gradient" 31 "Not_Defined" ;
VAL_ 929 PSD_EndGradient_Sign 0 "Downgrade" 1 "Gradient" ;
VAL_ 929 PSD_ADAS_Quality 0 "No_ADAS_Quality" 1 "ADAS_Quality" ;
VAL_ 929 PSD_Lanes 0 "OneWayStreet_in_Wrong_Direction" 1 "A_Lane" 2 "Two_Lanes" 3 "Three_Lanes" ;
VAL_ 929 PSD_MostLikely_Path 0 "Path_With_Lower_Probability" 1 "MostLikely_Path" ;
VAL_ 930 PSD_Multiplex 0 "f�r System Information, The sich Only Slow �ndern" 1 "Information �Range On Streckensegment" 2 "f�r Information �Range Geschwindigkeitsbegrenzungen And m�gliche Restrict�nkungen The Geschwindigkeitsbegrenzungen" 3 "Fahrzeugposition Off The Koppelortung" ;
VAL_ 930 PSD_Sys_Segment_ID 0 "No SegmentInfo Present" 1 "Not Permitted" ;
VAL_ 930 PSD_Abz_Segment_ID 0 "No SegmentInfo Present" 1 "Not Permitted" ;
VAL_ 930 PSD_Total_Segment_ID 0 "No SegmentInfo Present" 1 "Not Permitted" ;
VAL_ 930 PSD_Location_Length_VZ 0 "Ost" 1 "West" ;
VAL_ 930 PSD_Location_Length 33554431 "No GPS Position Available" ;
VAL_ 930 PSD_Total_Speed 0 "No SpeedRequirement" 1 "0 km/h < v_max <  5 km/h" 2 "5 km/h � v_max < 10km/h" 3 "10 km/h � v_max < 15 km/h" 4 "15 km/h � v_max < 20 km/h" 5 "20 km/h � v_max < 25 km/h" 6 "25 km/h � v_max < 30 km/h" 7 "30 km/h � v_max < 35 km/h" 8 "35 km/h � v_max < 40 km/h" 9 "40 km/h � v_max < 45 km/h" 10 "45 km/h � v_max < 50 km/h" 11 "50 km/h � v_max < 60 km/h" 12 "60 km/h � v_max < 70 km/h" 13 "70 km/h � v_max < 80 km/h" 14 "80 km/h � v_max < 90 km/h" 15 "90 km/h � v_max < 100 km/h" 16 "100 km/h � v_max < 110 km/h" 17 "110 km/h � v_max < 120 km/h" 18 " 120 km/h � v_max < 130 km/h" 19 "130 km/h � v_max < 140 km/h" 20 "140 km/h � v_max < 150 km/h" 21 "150 km/h � v_max < 160 km/h" 22 "160 km/h � v_max" 23 "SpeedRequirement Cancelled" 24 "..0x1F ung�ltig" ;
VAL_ 930 PSD_Total_Speed_Type 0 "The Value In Attribut SpeedLimit Corresponds The SpeedClass From Navteq." 1 "The Value In Attribut SpeedLimit Corresponds A Explicit angegebenen Limit The Speed." ;
VAL_ 930 PSD_Total_Speed_TrailerCombo 0 "All Vehicles" 1 "CAR With TrailerCombo" 2 "Truck, Buses, etc." ;
VAL_ 930 PSD_Abz_Predecessor_Segment_ID 0 "No SegmentInfo Present" 1 "Not Permitted" ;
VAL_ 930 PSD_Sys_Speed_Unit 0 "km/h" 1 "mph" ;
VAL_ 930 PSD_Total_Speed_Witter 0 "Witterungsunabh�ngig" 1 "N�sse, Rain, Precipitation" 2 "Gl�tte" 3 "Fog" ;
VAL_ 930 PSD_Sys_Verkehrsrichtung 0 "RightHandTraffic" 1 "LeftHandTraffic" ;
VAL_ 930 PSD_Total_Speed_Tag_Req 0 "No Start Defined" 1 "Monday" 2 "Tuesday" 3 "Wednesday" 4 "Thursday" 5 "Friday" 6 "Saturday" 7 "Sunday" ;
VAL_ 930 PSD_Abz_Speed 0 "No SpeedRequirement" 1 "0 km/h < v_max <  5 km/h" 2 "5 km/h � v_max < 10km/h" 3 "10 km/h � v_max < 15 km/h" 4 "15 km/h � v_max < 20 km/h" 5 "20 km/h � v_max < 25 km/h" 6 "25 km/h � v_max < 30 km/h" 7 "30 km/h � v_max < 35 km/h" 8 "35 km/h � v_max < 40 km/h" 9 "40 km/h � v_max < 45 km/h" 10 "45 km/h � v_max < 50 km/h" 11 "50 km/h � v_max < 60 km/h" 12 "60 km/h � v_max < 70 km/h" 13 "70 km/h � v_max < 80 km/h" 14 "80 km/h � v_max < 90 km/h" 15 "90 km/h � v_max < 100 km/h" 16 "100 km/h � v_max < 110 km/h" 17 "110 km/h � v_max < 120 km/h" 18 "120 km/h � v_max < 130 km/h" 19 "130 km/h � v_max < 140 km/h" 20 "140 km/h � v_max < 150 km/h" 21 "150 km/h � v_max < 160 km/h" 22 "160 km/h � v_max" 23 " SpeedRequirement Cancelled" 24 "..0x1F ung�ltig" ;
VAL_ 930 PSD_Total_Speed_Tag_End 0 "No End Defined" 1 "Monday" 2 "Tuesday" 3 "Wednesday" 4 "Thursday" 5 "Friday" 6 "Saturday" 7 "Sunday" ;
VAL_ 930 PSD_Total_Speed_Std_Req 25 "No Start f�r Hourly Restrict�nkungen" ;
VAL_ 930 PSD_Abz_Speed_Type 0 "The Value In Attribut SpeedLimit Corresponds The SpeedClass From Navteq." 1 "The Value In Attribut SpeedLimit Corresponds A Explicit angegebenen Limit The Speed" ;
VAL_ 930 PSD_Sys_Tunnel 0 "No Tunnel Or No Information Available" 1 "Tunnel" ;
VAL_ 930 PSD_Abz_RoadClass 0 " Rest (FieldTrack, Schotter, PrivateRoad)" 1 "LocationRoad�e" 2 "Bundes-,CountryRoad" 3 "Motorway" ;
VAL_ 930 PSD_Sys_Bruecke 0 "No Bruecke Or No Information Available" 1 "Bruecke" ;
VAL_ 930 PSD_Location_Width_VZ 0 "Nord" 1 "Sued" ;
VAL_ 930 PSD_Sys_Fahrsp_Gegenr 0 "No Lane" 1 "A Lane" 2 "More As A Lane" 3 "No Information Available" ;
VAL_ 930 PSD_Abz_ADAS_Quality 0 "No ADAS Qualit�t" 1 "ADAS Qualit�t" ;
VAL_ 930 PSD_Total_Speed_Std_End 25 "No End f�r Hourly Restrict�nkungen" ;
VAL_ 930 PSD_Abz_Abzweigerichtung 0 "Right Branching Road�e" 1 "Left Branching Road�e" ;
VAL_ 930 PSD_Sys_TMC_Roadworks 0 "No Roadworks Or No Information Available" 1 "Roadworks" ;
VAL_ 930 PSD_Abz_Abzweigewinkel 0 "0�: Road�e verl�uft Straight Off" 1 "0� < Angle � 12�" 2 "12� < Angle � 24�" 3 "24� < Angle � 36�" 4 "36� < Angle � 48�" 5 "48� < Angle � 60�" 6 "60� < Angle � 72�" 7 "72� < Angle � 84�" 8 "84� < Angle � 96�" 9 "96� < Angle � 108�" 10 "108� < Angle � 120�" 11 "120� < Angle � 132�" 12 "132� < Angle � 144�" 13 "144� < Angle � 156�" 14 "156� < Angle � 168�" 15 "168� < Angle � 180�" ;
VAL_ 930 PSD_Sys_TMC_TrafficJam 0 "No TrafficJam Or No Information Available" 1 "TrafficJam" ;
VAL_ 930 PSD_Total_Age_Speed 0 "No SpeedRequirement" 1 "0 km/h < v_max <  5 km/h" 2 "5 km/h � v_max < 10km/h" 3 "10 km/h � v_max < 15 km/h" 4 "15 km/h � v_max < 20 km/h" 5 "20 km/h � v_max < 25 km/h" 6 "25 km/h � v_max < 30 km/h" 7 "30 km/h � v_max < 35 km/h" 8 "35 km/h � v_max < 40 km/h" 9 "40 km/h � v_max < 45 km/h" 10 "45 km/h � v_max < 50 km/h" 11 "50 km/h � v_max < 60 km/h" 12 "60 km/h � v_max < 70 km/h" 13 "70 km/h � v_max < 80 km/h" 14 "80 km/h � v_max < 90 km/h" 15 "90 km/h � v_max < 100 km/h" 16 "100 km/h � v_max < 110 km/h" 17 "110 km/h � v_max < 120 km/h" 18 "120 km/h � v_max < 130 km/h" 19 "130 km/h � v_max < 140 km/h" 20 "140 km/h � v_max < 150 km/h" 21 "150 km/h � v_max < 160 km/h" 22 "160 km/h � v_max" 23 "SpeedRequirement Cancelled" 24 "..0x1F ung�ltig" ;
VAL_ 930 PSD_Abz_Ramp 0 "Road�e With OncomingTraffic" 1 "OpenJourney (OneWayStreet.) " 2 "Exit (OneWayStreet.)" 3 "Einbahnstra�e" ;
VAL_ 930 PSD_Abz_StartCurvature 255 "Straight" ;
VAL_ 930 PSD_Total_Age_Speed_TrailerCombo 0 "All Vehicles" 1 "CAR With TrailerCombo" 2 "Truck, Buses, etc." ;
VAL_ 930 PSD_Total_Age_Speed_Witter 0 "Witterungsunabh�ngig" 1 "N�sse, Rain, Precipitation" 2 "Gl�tte" 3 "Fog" ;
VAL_ 930 PSD_Total_Age_Speed_Tag_Req 0 "No Start Defined" 1 "Monday" 2 "Tuesday" 3 "Wednesday" 4 "Thursday" 5 "Friday" 6 "Saturday" 7 "Sunday" ;
VAL_ 930 PSD_Abz_StartCurvature_Sign 0 "Kr�mmung Positive" 1 "Kr�mmung Negative" ;
VAL_ 930 PSD_Sys_StartCurvature 255 "Straight" ;
VAL_ 930 PSD_Abz_EndCurvature 255 "Straight" ;
VAL_ 930 PSD_Total_Age_Speed_Tag_End 0 "No End Defined" 1 "Monday" 2 "Tuesday" 3 "Wednesday" 4 "Thursday" 5 "Friday" 6 "Saturday" 7 "Sunday" ;
VAL_ 930 PSD_Total_Age_Speed_Std_Req 25 "No Start f�r Hourly Restrict�nkungen" ;
VAL_ 930 PSD_Sys_StartCurvature_Sign 0 "Kr�mmung Positive" 1 "Kr�mmung Negative" ;
VAL_ 930 PSD_Abz_EndCurvature_Sign 0 "Kr�mmung Positive" 1 "Kr�mmung Negative" ;
VAL_ 930 PSD_Total_Age_Speed_Std_End 25 "No End f�r Hourly Restrict�nkungen" ;
VAL_ 930 PSD_Sys_Anfangssteigung 30 "Equal Or More As 15 % Gradient" 31 "ung�ltig" ;
VAL_ 930 PSD_Abz_EndGradient 30 "Equal Or More As 15 % Gradient" 31 "ung�ltig" ;
VAL_ 930 PSD_Total_NoOvertaking 0 "No �berholverbot" 1 "All Vehicles" 2 "�berholverbot f�r CAR With TrailerCombo" 3 "�berholverbot f�r Truck, Buses, etc." ;
VAL_ 930 PSD_Sys_Anfangssteigung_Sign 0 "Filt�lle " 1 "Gradient" ;
VAL_ 930 PSD_Abz_EndGradient_Sign 0 "Filt�lle" 1 "Gradient" ;
VAL_ 930 PSD_Sys_BuiltUpArea 0 "au�erhalb The BuiltUpArea" 1 "Within The BuiltUpArea" ;
VAL_ 930 PSD_Abz_Lanes 0 "Einbahnstra�e in Wrong Direction" 1 "A Lane" 2 "Two Lanes" 3 "More As 2 Lanes" ;
VAL_ 930 PSD_Total_VariableTrafficSign 0 "No VariableTrafficSign" 1 "VariableTrafficSign Left" 2 "VariableTrafficSign Right" 3 "VariableTrafficSign Left And Right" 4 "Wechselverkerhszeichen �Range The Road" ;
VAL_ 930 PSD_Sys_Digitalisierung 0 "teildigitalisiert" 1 "volldigitalisiert" ;
VAL_ 930 PSD_Sys_RouteGuidance 0 "RouteGuidance Not Active" 1 "RouteGuidance Active" ;
VAL_ 930 PSD_Abz_MostLikely_Path 0 "Path With Lower Probability" 1 "MostLikely Path" ;
VAL_ 1528 SAK_Charisma_DrivePr 0 "Not_Occupied" 1 "Programm_1" 2 "Programm_2" 3 "Programm_3" 4 "Programm_4" 5 "Programm_5" 6 "Programm_6" 7 "Programm_7" ;
VAL_ 1528 SAK_Charisma_Status 0 "Init" 1 "Available" 2 "Not_Available" 3 "Asynchronous_By_DriverDemand" ;
VAL_ 1528 SAK_Charisma_Changeover 0 "Idle" 1 "Detection_ChangeoverPrompt" 2 "ControlMessage_Not_Defined" 3 "Changeover_Delayed" ;
VAL_ 1528 SAK_KD_Error 0 "No_KD_Error" 1 "KD_Error" ;
VAL_ 1011 SCR_DosingPump_Rpm 2047 "Error" ;
VAL_ 1011 SCR_Pressure 1021 "Not_Fitted" 1023 "Error" ;
VAL_ 1011 SCR_Level_ActiveTank 1021 "Not_Fitted" 1023 "Error" ;
VAL_ 1011 SCR_Level_PassiveTank 1021 "Not_Fitted" 1023 "Error" ;
VAL_ 1507 SCR_HeatCircuit_3_Current 253 "Not_Fitted" 255 "Error" ;
VAL_ 1507 SCR_KD_Error 0 "No_KD_Error" 1 "KD_Error" ;
VAL_ 1507 SCR_Guetesensor 1021 "Not_Fitted" 1023 "Error" ;
VAL_ 1507 SCR_Temp_ActiveTank 255 "Error" ;
VAL_ 1507 SCR_Temp_PassiveTank 253 "Not_Fitted" 255 "Error" ;
VAL_ 1507 SCR_LineHeater_Current 255 "Error" ;
VAL_ 1507 SCR_TransferPump_Current 253 "Not_Fitted" 255 "Error" ;
VAL_ 1507 SCR_TankHeater_Current 255 "Error" ;
VAL_ 1508 SCR_Spannungsversorgung_Status 0 "No_Error" 1 "KS-" 2 "KS+" 3 "OC" 4 "OOR+(Overvoltage)" 5 "OOR-(Undervoltage)" 6 "RC+" 7 "RC-" 8 "KS+/OC" 9 "KS-/OC" 10 "KS-/KS+" 11 "KS-/KS+/OC" 12 "OOR+(FuncRestrict_OverVolt)" 13 "OOR-(FuncRestrict_UnderVolt)" 14 "Free" 15 "Diagnostics_Yet_Not_Finished" ;
VAL_ 1508 SCR_VersorgungSensors_Status 0 "No_Error" 1 "KS-" 2 "KS+" 3 "OC" 4 "OOR+" 5 "OOR-" 6 "RC+" 7 "RC-" 8 "KS+/OC" 9 "KS-/OC" 10 "KS-/KS+" 11 "KS-/KS+/OC" 12 "Free" 13 "Free" 14 "Free" 15 "Diagnostics_Yet_Not_Finished" ;
VAL_ 1508 SCR_HeatCircuit_3_Status 0 "No_Error" 1 "KS- (ShortCircuit After minus)" 2 "KS+ (ShortCircuit After plus)" 3 "OC (WireBreak)" 4 "OOR+ (Signal Closed Large)" 5 "OOR- (Signal Closed Small)" 6 "RC+ (Signal Implausible Closed Large)" 7 "RC- (Signal Implausible Closed Small)" 8 "KS+/OC (ShortCircuit After plus/OpenCircuit)" 9 "KS-/OC  (ShortCircuit After plus/OpenCircuit)" 10 "KS-/KS+  (ShortCircuit After minus/plus)" 11 "KS-/KS+/OC (ShortCircuit After minus/plus/OpenCircuit)" 12 "Free" 13 "Free" 14 "Free" 15 "Free" ;
VAL_ 1508 SCR_Guetesensor_Status 0 "No_Error" 1 "KS- (ShortCircuit After minus)" 2 "KS+ (ShortCircuit After plus)" 3 "OC (WireBreak)" 4 "OOR+ (Signal Closed Large)" 5 "OOR- (Signal Closed Small)" 6 "RC+ (Signal Implausible Closed Large)" 7 "RC- (Signal Implausible Closed Small)" 8 "KS+/OC (ShortCircuit After plus/OpenCircuit)" 9 "KS-/OC  (ShortCircuit After plus/OpenCircuit)" 10 "KS-/KS+  (ShortCircuit After minus/plus)" 11 "KS-/KS+/OC (ShortCircuit After minus/plus/OpenCircuit)" 12 "Free" 13 "Free" 14 "Free" 15 "Free" ;
VAL_ 1508 SCR_LineHeater_Status 0 "No_Error" 1 "KS- (ShortCircuit After minus)" 2 "KS+ (ShortCircuit After plus)" 3 "OC (WireBreak)" 4 "OOR+ (Signal Closed Large)" 5 "OOR- (Signal Closed Small)" 6 "RC+ (Signal Implausible Closed Large)" 7 "RC- (Signal Implausible Closed Small)" 8 "KS+/OC (ShortCircuit After plus/OpenCircuit)" 9 "KS-/OC  (ShortCircuit After plus/OpenCircuit)" 10 "KS-/KS+  (ShortCircuit After minus/plus)" 11 "KS-/KS+/OC (ShortCircuit After minus/plus/OpenCircuit)" 12 "Free" 13 "Free" 14 "Free" 15 "Free" ;
VAL_ 1508 SCR_TankHeater_Status 0 "No_Error" 1 "KS- (ShortCircuit After minus)" 2 "KS+ (ShortCircuit After plus)" 3 "OC (WireBreak)" 4 "OOR+ (Signal Closed Large)" 5 "OOR- (Signal Closed Small)" 6 "RC+ (Signal Implausible Closed Large)" 7 "RC- (Signal Implausible Closed Small)" 8 "KS+/OC (ShortCircuit After plus/OpenCircuit)" 9 "KS-/OC  (ShortCircuit After plus/OpenCircuit)" 10 "KS-/KS+  (ShortCircuit After minus/plus)" 11 "KS-/KS+/OC (ShortCircuit After minus/plus/OpenCircuit)" 12 "Free" 13 "Free" 14 "Free" 15 "Free" ;
VAL_ 1508 SCR_Pressure_Status 0 "No_Error" 1 "KS- (ShortCircuit After minus)" 2 "KS+ (ShortCircuit After plus)" 3 "OC (WireBreak)" 4 "OOR+ (Signal Closed Large)" 5 "OOR- (Signal Closed Small)" 6 "RC+ (Signal Implausible Closed Large)" 7 "RC- (Signal Implausible Closed Small)" 8 "KS+/OC (ShortCircuit After plus/OpenCircuit)" 9 "KS-/OC  (ShortCircuit After plus/OpenCircuit)" 10 "KS-/KS+  (ShortCircuit After minus/plus)" 11 "KS-/KS+/OC (ShortCircuit After minus/plus/OpenCircuit)" 12 "Free" 13 "Free" 14 "Free" 15 "Free" ;
VAL_ 1508 SCR_DosingPump_Status_Spule 0 "No_Error" 1 "KS-" 2 "KS+" 3 "OC" 4 "OOR+" 5 "OOR-" 6 "RC+(Rpm_Closed_High)" 7 "RC-(Rpm_Closed_Low)" 8 "KS+/OC" 9 "KS-/OC" 10 "KS-/KS+" 11 "KS-/KS+/OC" 12 "KS_Between_Phasen" 13 "Free" 14 "Free" 15 "Free" ;
VAL_ 1508 SCR_TransferPump_Status 0 "No_Error" 1 "KS- (ShortCircuit After minus)" 2 "KS+ (ShortCircuit After plus)" 3 "OC (WireBreak)" 4 "OOR+ (Signal Closed Large)" 5 "OOR- (Signal Closed Small)" 6 "RC+ (Signal Implausible Closed Large)" 7 "RC- (Signal Implausible Closed Small)" 8 "KS+/OC (ShortCircuit After plus/OpenCircuit)" 9 "KS-/OC  (ShortCircuit After plus/OpenCircuit)" 10 "KS-/KS+  (ShortCircuit After minus/plus)" 11 "KS-/KS+/OC (ShortCircuit After minus/plus/OpenCircuit)" 12 "Free" 13 "Free" 14 "Free" 15 "Free" ;
VAL_ 1508 SCR_Level_ActiveTank_Status 0 "No_Error" 1 "KS- (ShortCircuit After minus)" 2 "KS+ (ShortCircuit After plus)" 3 "OC (WireBreak)" 4 "OOR+ (Signal Closed Large)" 5 "OOR- (Signal Closed Small)" 6 "RC+ (Signal Implausible Closed Large)" 7 "RC- (Signal Implausible Closed Small)" 8 "KS+/OC (ShortCircuit After plus/OpenCircuit)" 9 "KS-/OC  (ShortCircuit After plus/OpenCircuit)" 10 "KS-/KS+  (ShortCircuit After minus/plus)" 11 "KS-/KS+/OC (ShortCircuit After minus/plus/OpenCircuit)" 12 "Free" 13 "Free" 14 "Free" 15 "Free" ;
VAL_ 1508 SCR_Level_PassiveTank_Status 0 "No_Error" 1 "KS- (ShortCircuit After minus)" 2 "KS+ (ShortCircuit After plus)" 3 "OC (WireBreak)" 4 "OOR+ (Signal Closed Large)" 5 "OOR- (Signal Closed Small)" 6 "RC+ (Signal Implausible Closed Large)" 7 "RC- (Signal Implausible Closed Small)" 8 "KS+/OC (ShortCircuit After plus/OpenCircuit)" 9 "KS-/OC  (ShortCircuit After plus/OpenCircuit)" 10 "KS-/KS+  (ShortCircuit After minus/plus)" 11 "KS-/KS+/OC (ShortCircuit After minus/plus/OpenCircuit)" 12 "Free" 13 "Free" 14 "Free" 15 "Free" ;
VAL_ 1508 SCR_Temp_ActiveTank_Status 0 "No_Error" 1 "KS- (ShortCircuit After minus)" 2 "KS+ (ShortCircuit After plus)" 3 "OC (WireBreak)" 4 "OOR+ (Signal Closed Large)" 5 "OOR- (Signal Closed Small)" 6 "RC+ (Signal Implausible Closed Large)" 7 "RC- (Signal Implausible Closed Small)" 8 "KS+/OC (ShortCircuit After plus/OpenCircuit)" 9 "KS-/OC  (ShortCircuit After plus/OpenCircuit)" 10 "KS-/KS+  (ShortCircuit After minus/plus)" 11 "KS-/KS+/OC (ShortCircuit After minus/plus/OpenCircuit)" 12 "Free" 13 "Free" 14 "Free" 15 "Free" ;
VAL_ 1508 SCR_Temp_PassiveTank_Status 0 "No_Error" 1 "KS- (ShortCircuit After minus)" 2 "KS+ (ShortCircuit After plus)" 3 "OC (WireBreak)" 4 "OOR+ (Signal Closed Large)" 5 "OOR- (Signal Closed Small)" 6 "RC+ (Signal Implausible Closed Large)" 7 "RC- (Signal Implausible Closed Small)" 8 "KS+/OC (ShortCircuit After plus/OpenCircuit)" 9 "KS-/OC  (ShortCircuit After plus/OpenCircuit)" 10 "KS-/KS+  (ShortCircuit After minus/plus)" 11 "KS-/KS+/OC (ShortCircuit After minus/plus/OpenCircuit)" 12 "Free" 13 "Free" 14 "Free" 15 "Free" ;
VAL_ 1509 SCR_Actuation_TransferPump 0 "Not_Active" 1 "Active" ;
VAL_ 1509 SCR_Actuation_DosingPump 0 "Not_Active" 1 "Active" ;
VAL_ 1509 SCR_Actuation_HeatCircuit_3 0 "Not_Active" 1 "Active" ;
VAL_ 1509 SCR_Actuation_LineHeater 0 "Not_Active" 1 "Active" ;
VAL_ 1509 SCR_Actuation_TankHeater 0 "Not_Active" 1 "Active" ;
VAL_ 1526 SCR_ControlUnit_Heating_Status 0 "No_Error" 1 "Endstufe_TankHeater_Overheated" 2 "Endstufe_LineHeater_Overheated" 3 "Diagnostics_Yet_Not_Finished" ;
VAL_ 1526 SCR_ControlUnit_Pump_Status 0 "No_Error" 1 "Endstufe_Pump_Overheated" 2 "Pump_Blocked" 3 "Diagnostics_Yet_Not_Finished" ;
VAL_ 1526 SCR_ControlUnit_Relay_Status 0 "No_Error" 1 "KS+ (OffGear PowerRelay) " 2 "KS-/OC (OffGear PowerRelay)" 3 "Diagnostics_Yet_Not_Finished" ;
VAL_ 1526 SCR_ControlUnit_Bus_Status 0 "No_Error" 1 "Bus_Communication_Error" 2 "Bus_Communication_Malfunction_(Temporary)" 3 "Diagnostics_Yet_Not_Finished" ;
VAL_ 1526 SCR_ControlUnit_Coding_St000 0 "No_Error" 1 "ControlUnit_Not_Coded" 2 "ControlUnit_Wrong_Coded" 3 "Diagnostics_Yet_Not_Finished" ;
VAL_ 1526 SCR_ControlUnit_DataRecord_St001 0 "No_Error" 1 "Invalid_DataRecord" 2 "unplausibeler_DataRecord" 3 "Diagnostics_Yet_Not_Finished" ;
VAL_ 1526 SCR_ControlUnit_Defective_Status 0 "No_Error" 1 "ControlUnit_Defective" 2 "ControlUnit_Malfunction_(Temporary)" 3 "Diagnostics_Yet_Not_Finished" ;
VAL_ 1510 SCR_CAL_ID_Name_01 48 "Error" ;
VAL_ 1510 SCR_CAL_ID_Name_02 48 "Error" ;
VAL_ 1510 SCR_CAL_ID_Name_03 48 "Error" ;
VAL_ 1512 SCR_CAL_ID_Empty 48 "Error" ;
VAL_ 133 SCU_Ue_Angle_ADS 4094 "Init" 4095 "Error" ;
VAL_ 133 SCU_VZ_Ue_Angle_ADS 0 "Positive" 1 "Negative" ;
VAL_ 133 SCU_Target_Ue_Angle 2046 "Init" 2047 "Error" ;
VAL_ 133 SCU_max_Gradient 511 "Error" ;
VAL_ 133 SCU_VZ_Target_Ue_Angle 0 "Positive" 1 "Negative" ;
VAL_ 133 SCU_Status 0 "Operational" 1 "Init" 2 "sichere �bersetzung" 3 "EngineLock Locked" 4 "Synchronisierung l�uft" ;
VAL_ 133 SCU_KD_Error 0 "No_KD_Error" 1 "KD_Error" ;
VAL_ 784 SCU_WarningLamp 0 "No Display (SCU_Status=0x0)" 1 "WarningLamp On (SCU_Status=0x1, 0x2, 0x3)" 2 "Reserved" 3 "WarningLamp Synchronisation (SCU_Status=0x4)" ;
VAL_ 784 SCU_Warnings 0 "No Display (SCU_Status=0x0, 0x1)" 1 "ADS Malfunction (SCU_Status=0x2, 0x3)" 2 "ADS Initialisation (SCU_Status=0x4)" 3 "Reserved" ;
VAL_ 784 SCU_Charisma_DrivePr 0 "Not_Occupied" 1 "Programm_1" 2 "Programm_2" 3 "Programm_3" 4 "Programm_4" 5 "Programm_5" 6 "Programm_6" 7 "Programm_7" ;
VAL_ 784 SCU_Charisma_Status 0 "Init (SCU_Status=0x1)" 1 "idle (SCU_Status=0x0, 0x4)" 2 "Not Available (SCU_Status=0x2, 0x3)" 3 "Reserved" ;
VAL_ 784 SCU_Charisma_Changeover 0 "Idle" 1 "Detection_ChangeoverPrompt" 2 "ControlMessage_Not_Defined" 3 "Changeover_Delayed" ;
VAL_ 1313 STH_Radio_On 0 "No RadioCommand To SwitchOn" 1 "RadioCommand To SwitchOn erhalten" ;
VAL_ 1313 STH_Radio_Off 0 "No RadioCommand" 1 "RadioCommand To SwitchOff erhalten" ;
VAL_ 1313 STH_AuxHeater 0 "AuxHeater Off" 1 "AuxHeater On" ;
VAL_ 1313 STH_LED 0 "No R�ckmeldung" 1 "Feedback AuxHeater in Operation" ;
VAL_ 1313 STH_Blower 0 "No OnShiftCommand On The AirCon, Gebl�se" 1 "OnShiftCommand On The AirCon, Gebl�se" ;
VAL_ 1313 STH_EKP_Anst 0 "EKP Not Actuate" 1 "EKP Actuate" ;
VAL_ 1313 STH_Start_Follows 0 "No_Start_Follows" 1 "Start_Follows" ;
VAL_ 1313 STH_Valve_Status 0 "Valve_Open__grosser_Circuit" 1 "Valve_Closed__Smaller_Circuit" ;
VAL_ 1313 STH_ErrorStatus 0 "No Error" 1 "Battery Low" 2 "Fuel Low" 3 "Hardware Defective" 4 "Heizgeraet Locked" ;
VAL_ 1313 STH_WaterTemp 254 "Init" 255 "Error" ;
VAL_ 1313 STH_Motorvorwaermung 0 "No Motorvorw�rmung erfolgt" 1 "HeatUp With Motorvorw�rmung erfolgt" ;
VAL_ 1313 STH_Was_Active 0 "Was Inactive" 1 "AuxHeater Was letzte Half Hour Active" ;
VAL_ 1313 STH_KVS_Overflow 0 "No �RangeRun" 1 "FuelConsumptionSignal, AtLeast On �RangeRun Has stattgefunden" ;
VAL_ 1313 STH_KD_Error 0 "No_KD_Error" 1 "KD_Error" ;
VAL_ 1172 Status_Car_not_under_theft 0 "false" 1 "true" ;
VAL_ 1172 Status_Car_under_theft 0 "false" 1 "true" ;
VAL_ 1172 Status_StarterLock 0 "Inactive" 1 "Active" ;
VAL_ 1172 Status_TypeCoding 0 "Base" 1 "E-Gas" 4 "Sonderschutz" ;
VAL_ 1172 Status_KD_Error 0 "No_KD_Error" 1 "KD_Error" ;
VAL_ 1172 Status_SideLight 0 "Inactive" 1 "Active" ;
VAL_ 1172 Status_Headlights 0 "Inactive" 1 "Active" ;
VAL_ 1172 Status_Alarm_still 0 "Inactive" 1 "Active" ;
VAL_ 1172 Status_Texte 0 "No_Text" 1 "Text_01" 2 "Text_02" 3 "Text_03" 4 "Text_04" 5 "Text_05" 6 "Text_06" 7 "Text_07" 8 "Text_08" 9 "Text_09" 10 "Text_10" 11 "Text_11" 12 "Text_12" 13 "Text_13" 14 "Init" 15 "Error" ;
VAL_ 1172 Status_ChargeRelay 0 "Relay_Open" 1 "Relay_Closed" ;
VAL_ 1172 Status_Buzzer 0 "Inactive" 1 "Active" ;
VAL_ 1172 Status_EmergencyStart 0 "No_EmergencyStart" 1 "EmergencyStart" ;
VAL_ 1172 Status_Horn 0 "Inactive" 1 "Active" ;
VAL_ 1172 Status_IdleShift 0 "IdleShift_Off" 1 "IdleShift_On" ;
VAL_ 1413 SI_Int_CAN_gespiegelt 0 "interner CAN Disconnected" 1 "interner CAN gespiegelt" ;
VAL_ 1413 SI_CAN_Comfort_Sleep 0 "No_BusIdle" 1 "BusIdle" ;
VAL_ 1413 SI_CAN_Dashboard_Sleep 0 "No_BusIdle" 1 "BusIdle" ;
VAL_ 1413 SI_CAN_Drive_Sleep 0 "No_BusIdle" 1 "BusIdle" ;
VAL_ 1413 SI_Infotainment_Sleep 0 "No_BusIdle" 1 "BusIdle" ;
VAL_ 1413 SI_CAN_Extended_Sleep 0 "No_BusIdle" 1 "BusIdle" ;
VAL_ 1413 SI_Chassis_Sleep 0 "No_BusIdle" 1 "BusIdle" ;
VAL_ 1413 SI_Diagnostics_Active 0 "Inactive" 1 "Active" ;
VAL_ 1413 SI_QRS_Mode 0 "QRS_MeasureMode_Not_Active" 1 "QRS_MeasureMode_Active" ;
VAL_ 1413 SI_T_Mode 0 "TransportMode_Not_Active" 1 "TransportMode_Active" ;
VAL_ 1413 SI_NWDF 0 "Monitoring_Not_Enabled" 1 "Monitoring_Enabled" ;
VAL_ 1413 SI_NWDF_Valid 0 "NWDF_Is_Not_Supported" 1 "NWDF_Is_Supported" ;
VAL_ 1413 SI_GeneralFault 0 "No_GeneralFault" 1 "GeneralFault" ;
VAL_ 1413 GW_KD_Error 0 "No_KD_Error" 1 "KD_Error" ;
VAL_ 1413 SI_MOST_Status 0 "MOST_sleep_(Light_OFF)" 1 "MOST_Active_(Communication_Possible)" ;
VAL_ 1413 SI_Collective_ECU_Error 61 "Reserved" 62 "Overflow" ;
VAL_ 1413 SI_MO_WU 0 "No Wakeup Requested" 1 "Wakeup MED9 Requested" ;
VAL_ 786 FAS_SetSpeed 1022 "No Display" 1023 "Not Defined" ;
VAL_ 786 FAS_Status_Prim_Disp 0 "Symbol Not Illuminated" 1 "Colour 1 (Typical 'gr�n')" 2 "Colour 2 (Typical 'Red')" 3 "Colour 3 (Typical 'Yellow')" ;
VAL_ 786 FAS_Texte_PrimaryDisplay 0 "No Display " 1 "ACC Not Available !" 2 "Auto_Auto_ _ _" 3 "Auto_ _Auto_ _" 4 "Auto_ _ _Auto_" 5 "Auto_ _ _ _Auto" 6 "Auto_Auto_ _ _ Chime (Crossed)" 7 "Auto_ _Auto_ _ Chime (Crossed)" 8 "Auto_ _ _Auto_ Chime (Crossed)" 9 "Auto_ _ _ _Auto Chime (Crossed)" 10 "ACC Ready" 11 "No DistanceControl" 12 "ACC Sensor View !" 13 "ACC Not Available" 14 "o  o  o" 15 "Upshift" 16 "ESP Intervention" 17 "Downshift" 18 "ParkingBrake !" 19 "SpeedLimit" 20 "SelectorLeverPosition !" 21 "VDA ACC-Symbol YYY km/h / mph" 22 "SpeedLimit XXX km/h / mph" 23 "Kurve XXX km/h / mph" 24 "ACC Shutdown" 25 "Symbol 'EggTimer'" 26 "!" 27 "--- km/h / mph" 28 "XXX km/h / mph (Schriftart 2)" 29 "SteeringWheelAngle" 30 "PullAway bestaetigen" 31 "Vehicle Lost" 32 "In Level Not Possible" 33 "Invalid PullAwayCommand" 34 "Door Open !" 35 "Driver BeltBuckle Open !" 36 "ShiftLeverPosition !" 37 "Rpm !" 38 "CurveAssist Off" 39 "SpeedLimit Off" 40 "Abbiegeassistent" 41 "Ortsanfang XXX km/h / mph" 42 "LocationEnd XXX km/h / mph" 43 "SpeedLimit End XXX km/h / mph" 44 "HDC Active" 45 "braking guard BrakeJerk" 46 "braking guard Off " 47 "braking guard Off" 48 "TakeOver !" 49 "Gradient Closed Large" 50 "Stationary Object Ahead" 51 "SET / 'GRA Symbol'___xxx km/h / mph" 52 "SET / 'GRA Symbol' xxx km/h / mph" 53 "ACC Off" 54 "ACC Starting" 55 "ACC Clean" 56 "ACC Error" 57 "ACC Holds On !" 58 "Brake Press !" 59 "Clutch Pressed" 60 "LIM OFF" 61 "LIM Active " 62 "LIM Passive" 63 "LIM Error" 64 "Brake Overheated !" 65 "Brake Holds !" 66 "ESP Passive !" ;
VAL_ 786 FAS_Status_Display 0 "ACC/GRA MainSwitch Off" 1 "ACC in Init (Not At GRA)" 2 "ACC/GRA Passive" 3 "ACCGRA Active" 4 "ACC/GRA In Background (�RangePress)" 5 "Free" 6 "ACC Reversible Off (Not At GRA)" 7 "ACC/GRA Irreversible Off" ;
VAL_ 270 TSK_ax_Gearbox 511 "Not Defined" ;
VAL_ 270 TSK_Enable_WU 0 "TSK_RatioRequest Not Enabled" 1 "TSK_RatioRequest Enabled" ;
VAL_ 270 TSK_Limiter_Active 0 "Speed Limiter Actual Not Active" 1 "Speed Limiter Active And Controls" ;
VAL_ 270 TSK_Status_GRA_ACC_02 0 "Not Fitted / No ACC Allowed�ssig" 1 "GRA / ACC Active " 2 "GRA / ACC From Driver �bersteuert" 3 "Error, GRA/ACC Not m�glich " ;
VAL_ 273 TSK_QBit_Gradient 0 "Valid_Value" 1 "Substitute_Init_Or_ErrorValue" ;
VAL_ 273 TSK_Status_GRA_ACC_01 0 "Not_Fitted_No_ACC_Permitted" 1 "GRA_ACC_Active" 2 "GRA_ACC_From_Driver_uebersteuert" 3 "Error_GRA_ACC_Not_Possible" ;
VAL_ 273 TSK_VehicleMass 31 "Error" ;
VAL_ 273 TSK_QBit_VehicleMass 0 "Valid_Value" 1 "Substitute_Init_Or_ErrorValue" ;
VAL_ 273 TSK_VehicleMass_02 255 "Error" ;
VAL_ 273 TSK_Gradient 255 "Error" ;
VAL_ 273 TSK_GearboxInfo 0 "ManualGearbox" 1 "AL_AQ_Gearbox" 2 "DL_DQ_Gearbox" 3 "CVT_Gearbox" ;
VAL_ 273 TSK_Coding_ACC 0 "TSK_Correct_Open_No_ACC_Coded_Or_TSK_Wrong_Coded" 1 "TSK_Correct_Open_ACC_Coded" ;
VAL_ 273 TSK_Zwangszusch_ESP 0 "No_ESP_ASR_Influence" 1 "ESP_ASR_Influence" ;
VAL_ 273 TSK_Enable_Decel_Req 0 "DecelerationRequest_Not_Enabled" 1 "DecelerationRequest_Enabled" ;
VAL_ 1414 WH_KD_Error 0 "No_KD_Error" 1 "KD_Error" ;
CM_ SG_ 134 LWI_QBit_Sub_Data "[DE: LWI_QBit_Sub_Daten]";
CM_ SG_ 134 LWI_QBit_SteeringWheelAngle "[DE: LWI_QBit_Lenkradwinkel]";
CM_ SG_ 134 LWI_SteeringWheelAngle "[DE: LWI_Lenkradwinkel]";
CM_ SG_ 134 LWI_VZ_SteeringWheelAngle "[DE: LWI_VZ_Lenkradwinkel]";
CM_ SG_ 134 LWI_VZ_SteeringWheelAngle_Speed "[DE: LWI_VZ_Lenkradw_Geschw]";
CM_ SG_ 134 LWI_SteeringWheelAngle_Speed "[DE: LWI_Lenkradw_Geschw]";
CM_ SG_ 134 LWI_Sub_Data "[DE: LWI_Sub_Daten]";
CM_ SG_ 128 Engine_01_CHK "[DE: Motor_01_CHK]";
CM_ SG_ 128 Engine_01_BZ "[DE: Motor_01_BZ]";
CM_ SG_ 128 MO_Torque_o_ex "[DE: MO_Mom_o_ex]";
CM_ SG_ 128 MO_Torque_m_ex "[DE: MO_Mom_m_ex]";
CM_ SG_ 128 MO_Torque_Loss "[DE: MO_Mom_Verlust]";
CM_ SG_ 128 MO_Torque_Limit "[DE: MO_Mom_Begrenzung]";
CM_ SG_ 128 MO_Torque_DriverDemand "[DE: MO_Mom_Fahrerwunsch]";
CM_ SG_ 128 MO_KD_Error "[DE: MO_KD_Fehler]";
CM_ SG_ 129 Engine_02_CHK "[DE: Motor_02_CHK]";
CM_ SG_ 129 Engine_02_BZ "[DE: Motor_02_BZ]";
CM_ SG_ 129 MO_Torque_ZWR "[DE: MO_Mom_ZWR]";
CM_ SG_ 129 MO_Torque_Target "[DE: MO_Mom_Soll]";
CM_ SG_ 129 MO_Torque_Actual "[DE: MO_Mom_Ist]";
CM_ SG_ 129 MO_Status_CylDeact_01 "[DE: MO_Status_Zylabschalt_01]";
CM_ SG_ 129 MO_Status_NormalOperation_01 "[DE: MO_Status_Normalbetrieb_01]";
CM_ SG_ 129 MO_StartStop_Status "[DE: MO_StartStopp_Status]";
CM_ SG_ 129 MO_StartStop_EngineStop "[DE: MO_StartStopp_Motorstopp]";
CM_ SG_ 129 MO_StartStop_Restart "[DE: MO_StartStopp_Wiederstart]";
CM_ SG_ 129 MO_Ext_E_Journey_Active "[DE: MO_Ext_E_Fahrt_aktiv]";
CM_ SG_ 129 MO_GearPosition "[DE: MO_Gangposition]";
CM_ SG_ 129 MO_StartStop_DriverDemand "[DE: MO_StartStopp_Fahrerwunsch]";
CM_ SG_ 129 MO_TorqueIntegral "[DE: MO_Momentenintegral]";
CM_ SG_ 261 Engine_03_CHK "[DE: MOTOR_03_CHK]";
CM_ SG_ 261 MO_QBit_AccelPedalValues_01 "[DE: MO_QBit_Fahrpedalwerte_01]";
CM_ SG_ 261 MO_QBit_EngineTorques "[DE: MO_QBit_Motormomente]";
CM_ SG_ 261 MO_QBit_Driver_Brakes "[DE: MO_QBit_Fahrer_bremst]";
CM_ SG_ 261 MO_QBit_Rpm_01 "[DE: MO_QBit_Drehzahl_01]";
CM_ SG_ 261 MO_Rpm_01 "[DE: MO_Drehzahl_01]";
CM_ SG_ 261 MO_Torque_In_Idle "[DE: MO_Moment_im_Leerlauf]";
CM_ SG_ 261 MO_Driver_Brakes "[DE: MO_Fahrer_bremst]";
CM_ SG_ 261 MO_Consistency_BrakePedal "[DE: MO_Konsistenz_Bremsped]";
CM_ SG_ 261 MO_Clutch_Switch "[DE: MO_Kuppl_schalter]";
CM_ SG_ 261 MO_Engine_Running "[DE: MO_Motor_laeuft]";
CM_ SG_ 261 MO_TargetRpm_Idle "[DE: MO_Solldrehz_Leerlauf]";
CM_ SG_ 261 MO_AccelPedalRaw_01 "[DE: MO_Fahrpedalrohwert_01]";
CM_ SG_ 261 MO_First_InaccurateThreshold "[DE: MO_erste_Ungenauschwelle]";
CM_ SG_ 263 MO_ActualGear "[DE: MO_Istgang]";
CM_ SG_ 263 MO_TargetGear "[DE: MO_Sollgang]";
CM_ SG_ 263 MO_OilPressure "[DE: MO_Oeldruck]";
CM_ SG_ 263 MO_DisplayRpm "[DE: MO_Anzeigedrehz]";
CM_ SG_ 263 MO_ShiftRecommend_Available "[DE: MO_Schaltempf_verfbar]";
CM_ SG_ 263 MO_BoostPressure "[DE: MO_Ladedruck]";
CM_ SG_ 263 MO_KVS_Overflow "[DE: MO_KVS_Ueberlauf]";
CM_ SG_ 782 Engine_05_CHK "[DE: Motor_05_CHK]";
CM_ SG_ 782 Engine_05_BZ "[DE: Motor_05_BZ]";
CM_ SG_ 782 MO_ETermCommLeiRed "[DE: MO_EKlKomLeiRed]";
CM_ SG_ 782 MO_Enable_Recup "[DE: MO_Freig_Reku]";
CM_ SG_ 782 MO_Climate_Interv "[DE: MO_Klima_Eingr]";
CM_ SG_ 782 MO_Status_NormalOperation_02 "[DE: MO_Status_Normalbetrieb_02]";
CM_ SG_ 782 MO_ShiftInfluence_PowerLimit "[DE: MO_Schaltbeeinfl_Leistungsbegr]";
CM_ SG_ 782 MO_ShiftInfluence_ParticleFilter "[DE: MO_Schaltbeeinfl_Partikelfilter]";
CM_ SG_ 782 MO_Prio_MIN_RequestedRpm "[DE: MO_Prio_MIN_Wunschdrehzahl]";
CM_ SG_ 782 MO_Enable_Crank "[DE: MO_Freig_Anlass]";
CM_ SG_ 782 MO_Aussp_Crank "[DE: MO_Aussp_Anlass]";
CM_ SG_ 782 MO_MAX_RequestedRpm "[DE: MO_MAX_Wunschdrehzahl]";
CM_ SG_ 782 MO_Prio_MAX_RequestedRpm "[DE: MO_Prio_MAX_Wunschdrehzahl]";
CM_ SG_ 782 MO_AirPath_Active "[DE: MO_Luftpfad_aktiv]";
CM_ SG_ 782 MO_v_Limit_Active "[DE: MO_v_Begrenz_Aktiv]";
CM_ SG_ 782 MO_v_Limit_Activatable "[DE: MO_v_Begrenz_Aktivierbar]";
CM_ SG_ 782 MO_Inhibit_EKP "[DE: MO_Verbot_EKP]";
CM_ SG_ 782 MO_Req_Pruefimpuls "[DE: MO_Anf_Pruefimpuls]";
CM_ SG_ 782 MO_Req_TERM75 "[DE: MO_Anf_KL75]";
CM_ SG_ 782 MO_Charisma_DrivePr "[DE: MO_Charisma_FahrPr]";
CM_ SG_ 782 MO_Charisma_Changeover "[DE: MO_Charisma_Umschaltung]";
CM_ SG_ 782 MO_MIN_RequestedRpm "[DE: MO_MIN_Wunschdrehzahl]";
CM_ SG_ 782 MO_RpmInfluence "[DE: MO_Drehzahlbeeinflussung]";
CM_ SG_ 1088 MO_RadiatorFan_MUX "[DE: MO_Kuehlerluefter_MUX]";
CM_ SG_ 1088 MO_RadiatorFan_1 "[DE: MO_Kuehlerluefter_1]";
CM_ SG_ 1088 MO_RadiatorFan_2 "[DE: MO_Kuehlerluefter_2]";
CM_ SG_ 1088 MO_HYB_Status_HV_Charge "[DE: MO_HYB_Status_HV_Ladung]";
CM_ SG_ 1088 WIV_Display_Active "[DE: WIV_Anzeige_aktiv]";
CM_ SG_ 1088 WIV_SensorError "[DE: WIV_Sensorfehler]";
CM_ SG_ 1088 WIV_Tilt "[DE: WIV_Schieflage]";
CM_ SG_ 1088 WIV_OilLevel "[DE: WIV_Oelstand]";
CM_ SG_ 1088 MO_State_HWP "[DE: MO_Zustand_HWP]";
CM_ SG_ 1088 WIV_OilSystem_Active "[DE: WIV_Oelsystem_aktiv]";
CM_ SG_ 1088 WIV_Not_AtOperatingTemp "[DE: WIV_nicht_betriebswarm]";
CM_ SG_ 1088 WIV_Overfill_Warn "[DE: WIV_Ueberfuell_Warn]";
CM_ SG_ 1088 WIV_Running_Engine "[DE: WIV_laufender_Motor]";
CM_ SG_ 1088 MO_Text_EngineStart "[DE: MO_Text_Motorstart]";
CM_ SG_ 1088 WIV_OilDyn_avl "[DE: WIV_Oeldyn_avl]";
CM_ SG_ 1088 MO_Text_MSG_Workshop "[DE: MO_Text_MSG_Werkstatt]";
CM_ SG_ 1088 MO_Text_ParticleFilter_Reg "[DE: MO_Text_Partikelfil_Reg]";
CM_ SG_ 1088 MO_Text_Error_Kraftstoffsys "[DE: MO_Text_Fehler_Kraftstoffsys]";
CM_ SG_ 1088 WIV_OilQuantity "[DE: WIV_Oelmenge]";
CM_ SG_ 1088 MO_SystemLamp "[DE: MO_Systemlampe]";
CM_ SG_ 1088 MO_OBD2_Lamp "[DE: MO_OBD2_Lampe]";
CM_ SG_ 1088 MO_HotWarningLamp "[DE: MO_Heissleuchte]";
CM_ SG_ 1088 MO_Particle_Lamp "[DE: MO_Partikel_Lampe]";
CM_ SG_ 1088 MO_WinterProgram "[DE: MO_Winterfahrprog]";
CM_ SG_ 1088 WIV_OilLevel_Not_Present "[DE: WIV_Oelstand_nicht_vorhanden]";
CM_ SG_ 1088 WIV_RefillDisplay_On "[DE: WIV_nachfuellanzeige_ein]";
CM_ SG_ 1088 WIV_Overfill_Deactivated "[DE: WIV_Ueberfuell_deaktiv]";
CM_ SG_ 1088 WIV_Underfill_Warn "[DE: WIV_Unterfuell_Warn]";
CM_ SG_ 1088 MO_FuelCap_Lamp "[DE: MO_Tankdeckel_Lampe]";
CM_ SG_ 1088 MO_Text_FuelCapWarn "[DE: MO_Text_Tankdeckelwarn]";
CM_ SG_ 1088 WIV_Enable_OilPressure_Engine "[DE: WIV_Enable_Oeldr_Motor]";
CM_ SG_ 1088 WIV_OilPressure_Warn_Engine "[DE: WIV_Oeldr_Warn_Motor]";
CM_ SG_ 1088 MO_Avus_EngineProtection "[DE: MO_Avus_Motorschutz]";
CM_ SG_ 1088 MO_HYB_ReadyToDrive "[DE: MO_HYB_Fahrbereitschaft]";
CM_ SG_ 1600 MO_QBit_IntakeAir_Temp "[DE: MO_QBit_Ansaugluft_Temp]";
CM_ SG_ 1600 MO_QBit_Oil_Temp "[DE: MO_QBit_Oel_Temp]";
CM_ SG_ 1600 MO_QBit_Coolant_Temp "[DE: MO_QBit_Kuehlmittel_Temp]";
CM_ SG_ 1600 MO_ActuatorTest_SoundActuator "[DE: MO_Stellgliedtest_Soundaktuator]";
CM_ SG_ 1600 MO_HYB_Error_HV_Network "[DE: MO_HYB_Fehler_HV_Netz]";
CM_ SG_ 1600 MO_Active_GearboxHeat "[DE: MO_aktives_Getriebeheizen]";
CM_ SG_ 1600 MO_ShutOffValve_Open "[DE: MO_Absperrventil_oeffnen]";
CM_ SG_ 1600 MO_IntakeAir_Temp "[DE: MO_Ansaugluft_Temp]";
CM_ SG_ 1600 MO_Oil_Temp "[DE: MO_Oel_Temp]";
CM_ SG_ 1600 MO_Coolant_Temp "[DE: MO_Kuehlmittel_Temp]";
CM_ SG_ 1600 MO_AltitudeInfo "[DE: MO_Hoeheninfo]";
CM_ SG_ 1600 MO_VersionInfo "[DE: MO_Versionsinfo]";
CM_ SG_ 1600 MO_Gearbox_Cool "[DE: MO_Getriebe_kuehlen]";
CM_ SG_ 1600 MO_Torque_Inertia_02 "[DE: MO_Mom_Traegheit_02]";
CM_ SG_ 1600 MO_HeatingPumpActuation "[DE: MO_Heizungspumpenansteuerung]";
CM_ SG_ 1600 MO_VoltageReq "[DE: MO_SpannungsAnf]";
CM_ SG_ 1600 MO_RunOnTime_HeatingPump "[DE: MO_Nachlaufzeit_Heizungspumpe]";
CM_ SG_ 1607 MO_ITM_Coolant_Temp "[DE: MO_ITM_Kuehlmittel_Temp]";
CM_ SG_ 1607 SCR_Disp_Motorstarts "[DE: SCR_Anz_Motorstarts]";
CM_ SG_ 1607 SCR_Range "[DE: SCR_Reichweite]";
CM_ SG_ 1607 SCR_WarningLevel_1 "[DE: SCR_Warnstufe_1]";
CM_ SG_ 1607 SCR_WarningLevel_2 "[DE: SCR_Warnstufe_2]";
CM_ SG_ 1607 SCR_Acoustic "[DE: SCR_Akustik]";
CM_ SG_ 1607 MO_Kraftstofffilter_Water "[DE: MO_Kraftstofffilter_Wasser]";
CM_ SG_ 1607 SCR_SystemError "[DE: SCR_Systemfehler]";
CM_ SG_ 1607 SCR_Inducement_Strategy "[DE: SCR_Inducement_Strategie]";
CM_ SG_ 1607 MO_CO2_Factor "[DE: MO_CO2_Faktor]";
CM_ SG_ 276 Engine_10_CHK "[DE: Motor_10_CHK]";
CM_ SG_ 276 Engine_10_BZ "[DE: Motor_10_BZ]";
CM_ SG_ 276 MO_Sig_AccelPedalGradient "[DE: MO_Sig_Fahrpedalgradient]";
CM_ SG_ 276 MO_BKV_VacuumWarning "[DE: MO_BKV_Unterdruckwarnung]";
CM_ SG_ 276 MO_CylinderDeactivation "[DE: MO_Zylinderabschaltung]";
CM_ SG_ 276 MO_AccelPedalGradient "[DE: MO_Fahrpedalgradient]";
CM_ SG_ 276 MO_OverrunFuelCut "[DE: MO_Schubabschaltung]";
CM_ SG_ 276 MO_rel_ManifoldPressure "[DE: MO_rel_Saugrohrdruck]";
CM_ SG_ 276 MO_rel_ManifoldPressure_gem_err "[DE: MO_rel_Saugrohrdruck_gem_err]";
CM_ SG_ 276 MO_BKV_Vacuum "[DE: MO_BKV_Unterdruck]";
CM_ SG_ 1648 MO_Count_Abgesch_Cyl "[DE: MO_Anzahl_Abgesch_Zyl]";
CM_ SG_ 1648 MO_CylDeact_Texte "[DE: MO_Zylabsch_Texte]";
CM_ SG_ 1648 MO_Rpm_Warning "[DE: MO_Drehzahl_Warnung]";
CM_ SG_ 1648 MO_Upper_RpmLimit "[DE: MO_obere_Drehzahlgrenze]";
CM_ SG_ 1010 Engine_19_BZ "[DE: Motor_19_BZ]";
CM_ SG_ 1010 MO_SCR_TankHeater "[DE: MO_SCR_Tankheizung]";
CM_ SG_ 1010 MO_SCR_DosingPump_State "[DE: MO_SCR_Dosierpumpe_Zustand]";
CM_ SG_ 1010 MO_SCR_LineHeater "[DE: MO_SCR_Leitungsheizung]";
CM_ SG_ 1010 MO_SCR_DosingPump_Wartezeit "[DE: MO_SCR_Dosierpumpe_Wartezeit]";
CM_ SG_ 1010 MO_SCR_TransferPump "[DE: MO_SCR_Transferpumpe]";
CM_ SG_ 1010 MO_SCR_DosingPump_Target "[DE: MO_SCR_Dosierpumpe_Soll]";
CM_ SG_ 1601 Engine_Code_01_CHK "[DE: Motor_Code_01_CHK]";
CM_ SG_ 1601 Engine_Code_01_BZ "[DE: Motor_Code_01_BZ]";
CM_ SG_ 1601 MO_Factor_Torques "[DE: MO_Faktor_Momente]";
CM_ SG_ 1601 MO_HybridVehicle "[DE: MO_Hybridfahrzeug]";
CM_ SG_ 1601 MO_Gearbox_Code "[DE: MO_Getriebe_Code]";
CM_ SG_ 1601 MO_StartStop_Coded "[DE: MO_StartStopp_Codiert]";
CM_ SG_ 1601 MO_Count_Cyl "[DE: MO_Anzahl_Zyl]";
CM_ SG_ 1601 MO_FuelType "[DE: MO_Kraftstoffart]";
CM_ SG_ 1601 MO_Displacement "[DE: MO_Hubraum]";
CM_ SG_ 1601 MO_IntakeSystem "[DE: MO_Ansaugsystem]";
CM_ SG_ 1601 MO_Power "[DE: MO_Leistung]";
CM_ SG_ 1601 MO_ExhaustType "[DE: MO_Abgastyp]";
CM_ SG_ 1601 MO_InjectionType "[DE: MO_Einspritzart]";
CM_ SG_ 969 MOS_KD_Error "[DE: MOS_KD_Fehler]";
CM_ SG_ 1696 NV_Active "[DE: NV_aktiv]";
CM_ SG_ 1696 NV_Chime "[DE: NV_Gong]";
CM_ SG_ 1696 NV_Notices "[DE: NV_Hinweise]";
CM_ SG_ 1696 NV_Piktogramm_Active "[DE: NV_Piktogramm_aktiv]";
CM_ SG_ 1696 NV_Acoustic_Deactivated_Icon "[DE: NV_Akustik_deaktiviert_Icon]";
CM_ SG_ 1696 NV_FGM_Deactivated_Icon "[DE: NV_FGM_deaktiviert_Icon]";
CM_ SG_ 1696 NV_KD_Error "[DE: NV_KD_Fehler]";
CM_ SG_ 1753 NMH_EPB_Func_WakeUp "[DE: NMH_EPB_Fkt_WakeUp]";
CM_ SG_ 1753 NMH_EPB_NM_Active_Terminal_15 "[DE: NMH_EPB_NM_aktiv_Klemme_15]";
CM_ SG_ 1753 NMH_EPB_NM_Active_Diagnostics "[DE: NMH_EPB_NM_aktiv_Diagnose]";
CM_ SG_ 1753 NMH_EPB_NM_Active_Start "[DE: NMH_EPB_NM_aktiv_Start]";
CM_ SG_ 1753 NMH_EPB_NM_Active_Switch "[DE: NMH_EPB_NM_aktiv_Schalter]";
CM_ SG_ 1753 NMH_EPB_NM_Active_Bedarf_Display "[DE: NMH_EPB_NM_aktiv_Bedarf_Anzeige]";
CM_ SG_ 1753 NMH_EPB_NM_Active_v_Greater_Null "[DE: NMH_EPB_NM_aktiv_v_groesser_Null]";
CM_ SG_ 1753 NMH_EPB_No_NL "[DE: NMH_EPB_kein_NL]";
CM_ SG_ 1753 NMH_EPB_NL_Temp_Model "[DE: NMH_EPB_NL_Temp_Modell]";
CM_ SG_ 1753 NM_EPB_SignalError "[DE: NM_EPB_Signalfehler]";
CM_ SG_ 1753 NMH_EPB_TimeOut_Error "[DE: NMH_EPB_TimeOut_Fehler]";
CM_ SG_ 1753 NMH_EPB_CAN_Diag_Deactivated "[DE: NMH_EPB_CAN_Diag_deaktiv]";
CM_ SG_ 1753 NMH_EPB_CompressorProtection "[DE: NMH_EPB_KompSchutz]";
CM_ SG_ 1753 NMH_EPB_ShutoffStage_Active "[DE: NMH_EPB_Abschaltstufe_aktiv]";
CM_ SG_ 1753 NMH_EPB_SingleWire_Error "[DE: NMH_EPB_Eindraht_Fehler]";
CM_ SG_ 1753 NMH_EPB_LocalActive "[DE: NMH_EPB_Lokalaktiv]";
CM_ SG_ 1753 NMH_EPB_SubsystemActive "[DE: NMH_EPB_Subsystemaktiv]";
CM_ SG_ 1728 NMH_GW_Func_WakeUp "[DE: NMH_GW_Fkt_WakeUp]";
CM_ SG_ 1728 NMH_GW_NM_Active_Terminal_15 "[DE: NMH_GW_NM_aktiv_Klemme_15]";
CM_ SG_ 1728 NMH_GW_NM_Active_Diagnostics "[DE: NMH_GW_NM_aktiv_Diagnose]";
CM_ SG_ 1728 NMH_GW_NM_Active_Start "[DE: NMH_GW_NM_aktiv_Start]";
CM_ SG_ 1728 NMH_GW_NM_Active_BDM "[DE: NMH_GW_NM_aktiv_BDM]";
CM_ SG_ 1728 NMH_GW_NM_Active_HazardFlash "[DE: NMH_GW_NM_aktiv_Warnblinken]";
CM_ SG_ 1728 NMH_GW_NM_Active_ESP "[DE: NMH_GW_NM_aktiv_ESP]";
CM_ SG_ 1728 NMH_GW_ShutoffStage_3 "[DE: NMH_GW_Abschaltstufe_3]";
CM_ SG_ 1728 NMH_GW_ECU_ErrorDuration "[DE: NMH_GW_SG_Fehlerdauer]";
CM_ SG_ 1728 NMH_GW_NL_Diagnostics "[DE: NMH_GW_NL_Diagnose]";
CM_ SG_ 1728 NM_GW_SignalError "[DE: NM_GW_Signalfehler]";
CM_ SG_ 1728 NMH_GW_TimeOut_Error "[DE: NMH_GW_TimeOut_Fehler]";
CM_ SG_ 1728 NMH_GW_CAN_Diag_Deactivated "[DE: NMH_GW_CAN_Diag_deaktiv]";
CM_ SG_ 1728 NMH_GW_CompressorProtection "[DE: NMH_GW_KompSchutz]";
CM_ SG_ 1728 NMH_GW_ShutoffStage_Active "[DE: NMH_GW_Abschaltstufe_aktiv]";
CM_ SG_ 1728 NMH_GW_SingleWire_Error "[DE: NMH_GW_Eindraht_Fehler]";
CM_ SG_ 1728 NMH_GW_ClusterCAN "[DE: NMH_GW_KombiCAN]";
CM_ SG_ 1728 NMH_GW_ComfortCAN "[DE: NMH_GW_KomfortCAN]";
CM_ SG_ 1728 NMH_GW_Chassis "[DE: NMH_GW_Fahrwerk]";
CM_ SG_ 1730 NMH_GE_Func_WakeUp "[DE: NMH_GE_Fkt_WakeUp]";
CM_ SG_ 1730 NMH_GE_NM_Active_Terminal_15 "[DE: NMH_GE_NM_aktiv_Klemme_15]";
CM_ SG_ 1730 NMH_GE_NM_Active_Diagnostics "[DE: NMH_GE_NM_aktiv_Diagnose]";
CM_ SG_ 1730 NMH_GE_NM_Active_Start "[DE: NMH_GE_NM_aktiv_Start]";
CM_ SG_ 1730 NMH_GE_N_HoldPhase "[DE: NMH_GE_N_Haltephase]";
CM_ SG_ 1730 NMH_GE_No_NL "[DE: NMH_GE_kein_NL]";
CM_ SG_ 1730 NMH_GE_NL_Data_EEPROM "[DE: NMH_GE_NL_Daten_EEPROM]";
CM_ SG_ 1730 NMH_GE_NL_SelectorLever "[DE: NMH_GE_NL_Waehlhebel]";
CM_ SG_ 1730 NMH_GE_NL_Immobiliser "[DE: NMH_GE_NL_Wegfahrsperre]";
CM_ SG_ 1730 NM_GE_SignalError "[DE: NM_GE_Signalfehler]";
CM_ SG_ 1730 NMH_GE_TimeOut_Error "[DE: NMH_GE_TimeOut_Fehler]";
CM_ SG_ 1730 NMH_GE_CAN_Diag_Deactivated "[DE: NMH_GE_CAN_Diag_deaktiv]";
CM_ SG_ 1730 NMH_GE_CompressorProtection "[DE: NMH_GE_KompSchutz]";
CM_ SG_ 1730 NMH_GE_ShutoffStage_Active "[DE: NMH_GE_Abschaltstufe_aktiv]";
CM_ SG_ 1730 NMH_GE_SingleWire_Error "[DE: NMH_GE_Eindraht_Fehler]";
CM_ SG_ 1730 NMH_GE_LocalActive "[DE: NMH_GE_Lokalaktiv]";
CM_ SG_ 1730 NMH_GE_SubsystemActive "[DE: NMH_GE_Subsystemaktiv]";
CM_ SG_ 1729 NMH_MO_Func_WakeUp "[DE: NMH_MO_Fkt_WakeUp]";
CM_ SG_ 1729 NMH_MO_NM_Active_Terminal_15 "[DE: NMH_MO_NM_aktiv_Klemme_15]";
CM_ SG_ 1729 NMH_MO_NM_Active_Diagnostics "[DE: NMH_MO_NM_aktiv_Diagnose]";
CM_ SG_ 1729 NMH_MO_NM_Active_Start "[DE: NMH_MO_NM_aktiv_Start]";
CM_ SG_ 1729 NMH_MO_NM_Active_EKP_Lead "[DE: NMH_MO_NM_aktiv_EKP_Vorlauf]";
CM_ SG_ 1729 NMH_MO_NM_Active_STH_Operation "[DE: NMH_MO_NM_aktiv_STH_Betrieb]";
CM_ SG_ 1729 NMH_MO_NM_Active_HV_Shutdown "[DE: NMH_MO_NM_aktiv_HV_Abschaltung]";
CM_ SG_ 1729 NMH_MO_No_NL "[DE: NMH_MO_kein_NL]";
CM_ SG_ 1729 NMH_MO_NL_RadiatorFan "[DE: NMH_MO_NL_Kuehlerluefter]";
CM_ SG_ 1729 NMH_MO_NL_Diagnostics "[DE: NMH_MO_NL_Diagnose]";
CM_ SG_ 1729 NMH_MO_NL_Other "[DE: NMH_MO_NL_Sonstige]";
CM_ SG_ 1729 NM_MO_SignalError "[DE: NM_MO_Signalfehler]";
CM_ SG_ 1729 NMH_MO_TimeOut_Error "[DE: NMH_MO_TimeOut_Fehler]";
CM_ SG_ 1729 NMH_MO_CAN_Diag_Deactivated "[DE: NMH_MO_CAN_Diag_deaktiv]";
CM_ SG_ 1729 NMH_MO_CompressorProtection "[DE: NMH_MO_KompSchutz]";
CM_ SG_ 1729 NMH_MO_ShutoffStage_Active "[DE: NMH_MO_Abschaltstufe_aktiv]";
CM_ SG_ 1729 NMH_MO_SingleWire_Error "[DE: NMH_MO_Eindraht_Fehler]";
CM_ SG_ 1729 NMH_MO_LocalActive "[DE: NMH_MO_Lokalaktiv]";
CM_ SG_ 1729 NMH_MO_SubsystemActive "[DE: NMH_MO_Subsystemaktiv]";
CM_ SG_ 1736 NMH_MO_SL_Func_WakeUp "[DE: NMH_MO_SL_Fkt_WakeUp]";
CM_ SG_ 1736 NMH_MO_SL_TimeOut_Error "[DE: NMH_MO_SL_TimeOut_Fehler]";
CM_ SG_ 1736 NMH_MO_SL_CAN_Diag_Deactivated "[DE: NMH_MO_SL_CAN_Diag_deaktiv]";
CM_ SG_ 1736 NMH_MO_SL_CompressorProtection "[DE: NMH_MO_SL_KompSchutz]";
CM_ SG_ 1736 NMH_MO_SL_ShutoffStage_Active "[DE: NMH_MO_SL_Abschaltstufe_aktiv]";
CM_ SG_ 1736 NMH_MO_SL_BusError "[DE: NMH_MO_SL_Busfehler]";
CM_ SG_ 1736 NMH_MO_Sl_LocalActive "[DE: NMH_MO_Sl_Lokalaktiv]";
CM_ SG_ 1736 NMH_MO_SL_SubsystemActive "[DE: NMH_MO_SL_Subsystemaktiv]";
CM_ SG_ 1782 NMH_SCR_Func_WakeUp "[DE: NMH_SCR_Fkt_WakeUp]";
CM_ SG_ 1782 NMH_SCR_Terminal_15 "[DE: NMH_SCR_Klemme_15]";
CM_ SG_ 1782 NMH_SCR_Diagnostics "[DE: NMH_SCR_Diagnose]";
CM_ SG_ 1782 NMH_SCR_MinActiveTime "[DE: NMH_SCR_MindestAktivZeit]";
CM_ SG_ 1782 NMH_SCR_SignalError "[DE: NMH_SCR_Signalfehler]";
CM_ SG_ 1782 NMH_SCR_TimeOut_Error "[DE: NMH_SCR_TimeOut_Fehler]";
CM_ SG_ 1782 NMH_SCR_CAN_Diag_Deactivated "[DE: NMH_SCR_CAN_Diag_deaktiv]";
CM_ SG_ 1782 NMH_SCR_CompressorProtection "[DE: NMH_SCR_KompSchutz]";
CM_ SG_ 1782 NMH_SCR_ShutoffStage_Active "[DE: NMH_SCR_Abschaltstufe_aktiv]";
CM_ SG_ 1782 NMH_SCR_BusError "[DE: NMH_SCR_Busfehler]";
CM_ SG_ 1782 NMH_SCR_LocalActive "[DE: NMH_SCR_Lokalaktiv]";
CM_ SG_ 1782 NMH_SCR_SubsystemActive "[DE: NMH_SCR_Subsystemaktiv]";
CM_ SG_ 913 OBD_ColdStart_Denominator "[DE: OBD_Kaltstart_Denominator]";
CM_ SG_ 803 PCF_ObjectStatus "[DE: PCF_Objektstatus]";
CM_ SG_ 803 PCF_Driver_Active_Detected "[DE: PCF_Fahrer_aktiv_erkannt]";
CM_ SG_ 802 PCR_Obj_Quality "[DE: PCR_Obj_Guete]";
CM_ SG_ 929 PSD_Pos_SegmentLength "[DE: PSD_Pos_Segmentlaenge]";
CM_ SG_ 929 PSD_Pos_Location "[DE: PSD_Pos_Standort]";
CM_ SG_ 929 PSD_Predecessor_Segment_ID "[DE: PSD_Vorgaenger_Segment_ID]";
CM_ SG_ 929 PSD_RoadClass "[DE: PSD_Strassenklasse]";
CM_ SG_ 929 PSD_SegmentLength "[DE: PSD_Segmentlaenge]";
CM_ SG_ 929 PSD_Ramp "[DE: PSD_Rampe]";
CM_ SG_ 929 PSD_EndCurvature "[DE: PSD_Endkruemmung]";
CM_ SG_ 929 PSD_EndCurvature_Sign "[DE: PSD_Endkruemmung_Vorz]";
CM_ SG_ 929 PSD_EndGradient "[DE: PSD_Endsteigung]";
CM_ SG_ 929 PSD_EndGradient_Sign "[DE: PSD_Endsteigung_Vorz]";
CM_ SG_ 929 PSD_ADAS_Quality "[DE: PSD_ADAS_Qualitaet]";
CM_ SG_ 929 PSD_Lanes "[DE: PSD_Fahrspuren]";
CM_ SG_ 929 PSD_MostLikely_Path "[DE: PSD_wahrscheinlichster_Pfad]";
CM_ SG_ 930 PSD_Total_Segment_ID "[DE: PSD_Ges_Segment_ID]";
CM_ SG_ 930 PSD_Location_Length_VZ "[DE: PSD_Ort_Laenge_VZ]";
CM_ SG_ 930 PSD_Location_Length "[DE: PSD_Ort_Laenge]";
CM_ SG_ 930 PSD_Abz_SegmentLength "[DE: PSD_Abz_Segmentlaenge]";
CM_ SG_ 930 PSD_Total_Speed "[DE: PSD_Ges_Geschwindigkeit]";
CM_ SG_ 930 PSD_Total_Speed_Type "[DE: PSD_Ges_Geschwindigkeit_Typ]";
CM_ SG_ 930 PSD_Total_Speed_TrailerCombo "[DE: PSD_Ges_Geschwindigkeit_Gespann]";
CM_ SG_ 930 PSD_Abz_Predecessor_Segment_ID "[DE: PSD_Abz_Vorgaenger_Segment_ID]";
CM_ SG_ 930 PSD_Sys_Speed_Unit "[DE: PSD_Sys_Geschwindigkeit_Einheit]";
CM_ SG_ 930 PSD_Total_Speed_Witter "[DE: PSD_Ges_Geschwindigkeit_Witter]";
CM_ SG_ 930 PSD_Sys_Release_Month "[DE: PSD_Sys_Release_Monat]";
CM_ SG_ 930 PSD_Total_Speed_Tag_Req "[DE: PSD_Ges_Geschwindigkeit_Tag_Anf]";
CM_ SG_ 930 PSD_Abz_Speed "[DE: PSD_Abz_Geschwindigkeit]";
CM_ SG_ 930 PSD_Total_Speed_Tag_End "[DE: PSD_Ges_Geschwindigkeit_Tag_Ende]";
CM_ SG_ 930 PSD_Sys_Release_Year "[DE: PSD_Sys_Release_Jahr]";
CM_ SG_ 930 PSD_Total_Speed_Std_Req "[DE: PSD_Ges_Geschwindigkeit_Std_Anf]";
CM_ SG_ 930 PSD_Abz_Speed_Type "[DE: PSD_Abz_Geschwindigkeit_Typ]";
CM_ SG_ 930 PSD_Abz_RoadClass "[DE: PSD_Abz_Strassenklasse]";
CM_ SG_ 930 PSD_Location_Width_VZ "[DE: PSD_Ort_Breite_VZ]";
CM_ SG_ 930 PSD_Abz_ADAS_Quality "[DE: PSD_Abz_ADAS_Qualitaet]";
CM_ SG_ 930 PSD_Total_Speed_Std_End "[DE: PSD_Ges_Geschwindigkeit_Std_Ende]";
CM_ SG_ 930 PSD_Location_Width "[DE: PSD_Ort_Breite]";
CM_ SG_ 930 PSD_Sys_TMC_Roadworks "[DE: PSD_Sys_TMC_Baustelle]";
CM_ SG_ 930 PSD_Sys_TMC_TrafficJam "[DE: PSD_Sys_TMC_Stau]";
CM_ SG_ 930 PSD_Total_Age_Speed "[DE: PSD_Ges_alter_Geschw]";
CM_ SG_ 930 PSD_Abz_Ramp "[DE: PSD_Abz_Rampe]";
CM_ SG_ 930 PSD_Abz_StartCurvature "[DE: PSD_Abz_Anfangskruemmung]";
CM_ SG_ 930 PSD_Total_Age_Speed_TrailerCombo "[DE: PSD_Ges_alter_Geschw_Gespann]";
CM_ SG_ 930 PSD_Total_Age_Speed_Witter "[DE: PSD_Ges_alter_Geschw_Witter]";
CM_ SG_ 930 PSD_Total_Age_Speed_Tag_Req "[DE: PSD_Ges_alter_Geschw_Tag_Anf]";
CM_ SG_ 930 PSD_Abz_StartCurvature_Sign "[DE: PSD_Abz_Anfangskruemmung_Vorz]";
CM_ SG_ 930 PSD_Sys_StartCurvature "[DE: PSD_Sys_Anfangskruemmung]";
CM_ SG_ 930 PSD_Abz_EndCurvature "[DE: PSD_Abz_Endkruemmung]";
CM_ SG_ 930 PSD_Total_Age_Speed_Tag_End "[DE: PSD_Ges_alter_Geschw_Tag_Ende]";
CM_ SG_ 930 PSD_Total_Age_Speed_Std_Req "[DE: PSD_Ges_alter_Geschw_Std_Anf]";
CM_ SG_ 930 PSD_Location_Height "[DE: PSD_Ort_Hoehe]";
CM_ SG_ 930 PSD_Sys_StartCurvature_Sign "[DE: PSD_Sys_Anfangskruemmung_Vorz]";
CM_ SG_ 930 PSD_Abz_EndCurvature_Sign "[DE: PSD_Abz_Endkruemmung_Vorz]";
CM_ SG_ 930 PSD_Total_Age_Speed_Std_End "[DE: PSD_Ges_alter_Geschw_Std_Ende]";
CM_ SG_ 930 PSD_Abz_EndGradient "[DE: PSD_Abz_Endsteigung]";
CM_ SG_ 930 PSD_Total_NoOvertaking "[DE: PSD_Ges_Ueberholverbot]";
CM_ SG_ 930 PSD_Sys_Anfangssteigung_Sign "[DE: PSD_Sys_Anfangssteigung_Vorz]";
CM_ SG_ 930 PSD_Abz_EndGradient_Sign "[DE: PSD_Abz_Endsteigung_Vorz]";
CM_ SG_ 930 PSD_Sys_BuiltUpArea "[DE: PSD_Sys_Ortschaft]";
CM_ SG_ 930 PSD_Abz_Lanes "[DE: PSD_Abz_Fahrspuren]";
CM_ SG_ 930 PSD_Total_VariableTrafficSign "[DE: PSD_Ges_Wechselverkehrszeichen]";
CM_ SG_ 930 PSD_Sys_RouteGuidance "[DE: PSD_Sys_Zielfuehrung]";
CM_ SG_ 930 PSD_Abz_MostLikely_Path "[DE: PSD_Abz_wahrscheinlichster_Pfad]";
CM_ SG_ 1528 SAK_Charisma_DrivePr "[DE: SAK_Charisma_FahrPr]";
CM_ SG_ 1528 SAK_Charisma_Changeover "[DE: SAK_Charisma_Umschaltung]";
CM_ SG_ 1528 SAK_KD_Error "[DE: SAK_KD_Fehler]";
CM_ SG_ 1011 SCR_DosingPump_Rpm "[DE: SCR_Dosierpumpe_Drehzahl]";
CM_ SG_ 1011 SCR_Pressure "[DE: SCR_Druck]";
CM_ SG_ 1011 SCR_Level_ActiveTank "[DE: SCR_Level_Aktivtank]";
CM_ SG_ 1011 SCR_Level_PassiveTank "[DE: SCR_Level_Passivtank]";
CM_ SG_ 1507 SCR_HeatCircuit_3_Current "[DE: SCR_Heizkreis_3_Strom]";
CM_ SG_ 1507 SCR_KD_Error "[DE: SCR_KD_Fehler]";
CM_ SG_ 1507 SCR_Temp_ActiveTank "[DE: SCR_Temp_Aktivtank]";
CM_ SG_ 1507 SCR_Temp_PassiveTank "[DE: SCR_Temp_Passivtank]";
CM_ SG_ 1507 SCR_LineHeater_Current "[DE: SCR_Leitungsheizung_Strom]";
CM_ SG_ 1507 SCR_TransferPump_Current "[DE: SCR_Transferpumpe_Strom]";
CM_ SG_ 1507 SCR_TankHeater_Current "[DE: SCR_Tankheizung_Strom]";
CM_ SG_ 1508 SCR_VersorgungSensors_Status "[DE: SCR_VersorgungSensoren_Status]";
CM_ SG_ 1508 SCR_HeatCircuit_3_Status "[DE: SCR_Heizkreis_3_Status]";
CM_ SG_ 1508 SCR_LineHeater_Status "[DE: SCR_Leitungsheizung_Status]";
CM_ SG_ 1508 SCR_TankHeater_Status "[DE: SCR_Tankheizung_Status]";
CM_ SG_ 1508 SCR_Pressure_Status "[DE: SCR_Druck_Status]";
CM_ SG_ 1508 SCR_DosingPump_Status_Spule "[DE: SCR_Dosierpumpe_Status_Spule]";
CM_ SG_ 1508 SCR_TransferPump_Status "[DE: SCR_Transferpumpe_Status]";
CM_ SG_ 1508 SCR_Level_ActiveTank_Status "[DE: SCR_Level_Aktivtank_Status]";
CM_ SG_ 1508 SCR_Level_PassiveTank_Status "[DE: SCR_Level_Passivtank_Status]";
CM_ SG_ 1508 SCR_Temp_ActiveTank_Status "[DE: SCR_Temp_Aktivtank_Status]";
CM_ SG_ 1508 SCR_Temp_PassiveTank_Status "[DE: SCR_Temp_Passivtank_Status]";
CM_ SG_ 1509 SCR_Actuation_TransferPump "[DE: SCR_Ansteuerung_Transferpumpe]";
CM_ SG_ 1509 SCR_Actuation_DosingPump "[DE: SCR_Ansteuerung_Dosierpumpe]";
CM_ SG_ 1509 SCR_Actuation_HeatCircuit_3 "[DE: SCR_Ansteuerung_Heizkreis_3]";
CM_ SG_ 1509 SCR_Actuation_LineHeater "[DE: SCR_Ansteuerung_Leitungsheizung]";
CM_ SG_ 1509 SCR_Actuation_TankHeater "[DE: SCR_Ansteuerung_Tankheizung]";
CM_ SG_ 1526 SCR_ControlUnit_Heating_Status "[DE: SCR_Steuergeraet_Heizung_Status]";
CM_ SG_ 1526 SCR_ControlUnit_Pump_Status "[DE: SCR_Steuergeraet_Pumpe_Status]";
CM_ SG_ 1526 SCR_ControlUnit_Relay_Status "[DE: SCR_Steuergeraet_Relais_Status]";
CM_ SG_ 1526 SCR_ControlUnit_Bus_Status "[DE: SCR_Steuergeraet_Bus_Status]";
CM_ SG_ 1526 SCR_ControlUnit_Coding_St000 "[DE: SCR_Steuergeraet_Codierung_St000]";
CM_ SG_ 1526 SCR_ControlUnit_DataRecord_St001 "[DE: SCR_Steuergeraet_Datensatz_St001]";
CM_ SG_ 1526 SCR_ControlUnit_Defective_Status "[DE: SCR_Steuergeraet_Defekt_Status]";
CM_ SG_ 1512 SCR_CAL_ID_Empty "[DE: SCR_CAL_ID_Leer]";
CM_ SG_ 133 SCU_Ue_Angle_ADS "[DE: SCU_Ue_Winkel_ADS]";
CM_ SG_ 133 SCU_VZ_Ue_Angle_ADS "[DE: SCU_VZ_Ue_Winkel_ADS]";
CM_ SG_ 133 SCU_Target_Ue_Angle "[DE: SCU_Soll_Ue_Winkel]";
CM_ SG_ 133 SCU_VZ_Target_Ue_Angle "[DE: SCU_VZ_Soll_Ue_Winkel]";
CM_ SG_ 133 SCU_KD_Error "[DE: SCU_KD_Fehler]";
CM_ SG_ 784 SCU_WarningLamp "[DE: SCU_Warnlampe]";
CM_ SG_ 784 SCU_Warnings "[DE: SCU_Warnungen]";
CM_ SG_ 784 SCU_Charisma_DrivePr "[DE: SCU_Charisma_FahrPr]";
CM_ SG_ 784 SCU_Charisma_Changeover "[DE: SCU_Charisma_Umschaltung]";
CM_ SG_ 1313 STH_Radio_On "[DE: STH_Funk_ein]";
CM_ SG_ 1313 STH_Radio_Off "[DE: STH_Funk_aus]";
CM_ SG_ 1313 STH_AuxHeater "[DE: STH_Zusatzheizung]";
CM_ SG_ 1313 STH_Pump_On "[DE: STH_Pumpe_ein]";
CM_ SG_ 1313 STH_Blower "[DE: STH_Geblaese]";
CM_ SG_ 1313 STH_Start_Follows "[DE: STH_Start_folgt]";
CM_ SG_ 1313 STH_ValveOpeningTime "[DE: STH_Ventiloeffnungszeit]";
CM_ SG_ 1313 STH_Valve_Status "[DE: STH_Ventil_Status]";
CM_ SG_ 1313 STH_ErrorStatus "[DE: STH_Fehlerstatus]";
CM_ SG_ 1313 STH_HeatPower "[DE: STH_Heizleistung]";
CM_ SG_ 1313 STH_WaterTemp "[DE: STH_Wassertemp]";
CM_ SG_ 1313 STH_Was_Active "[DE: STH_war_aktiv]";
CM_ SG_ 1313 STH_KVS_Overflow "[DE: STH_KVS_Ueberlauf]";
CM_ SG_ 1313 STH_KD_Error "[DE: STH_KD_Fehler]";
CM_ SG_ 1172 Status_01_CHK "[DE: STS_01_CHK]";
CM_ SG_ 1172 Status_01_BZ "[DE: STS_01_BZ]";
CM_ SG_ 1172 Status_Car_not_under_theft "[DE: STS_Car_not_under_theft]";
CM_ SG_ 1172 Status_Car_under_theft "[DE: STS_Car_under_theft]";
CM_ SG_ 1172 Status_StarterLock "[DE: STS_Anlassersperre]";
CM_ SG_ 1172 Status_TypeCoding "[DE: STS_Typencodierung]";
CM_ SG_ 1172 Status_KD_Error "[DE: STS_KD_Fehler]";
CM_ SG_ 1172 Status_LIN_Active "[DE: STS_LIN_aktiv]";
CM_ SG_ 1172 Status_SideLight "[DE: STS_Standlicht]";
CM_ SG_ 1172 Status_Headlights "[DE: STS_Fahrlicht]";
CM_ SG_ 1172 Status_Alarm_still "[DE: STS_Alarm_still]";
CM_ SG_ 1172 Status_Texte "[DE: STS_Texte]";
CM_ SG_ 1172 Status_ChargeRelay "[DE: STS_Laderelais]";
CM_ SG_ 1172 Status_Buzzer "[DE: STS_Summer]";
CM_ SG_ 1172 Status_Alarm_Indicator "[DE: STS_Alarm_Blinker]";
CM_ SG_ 1172 Status_EmergencyStart "[DE: STS_Notstart]";
CM_ SG_ 1172 Status_Horn "[DE: STS_Signalhorn]";
CM_ SG_ 1172 Status_IdleShift "[DE: STS_Leerlaufschaltung]";
CM_ SG_ 783 SWA_Display "[DE: SWA_Anzeigen]";
CM_ SG_ 783 SWA_Blindness_Detected "[DE: SWA_Blindheit_erkannt]";
CM_ SG_ 783 SWA_rel_NotAvail "[DE: SWA_rel_Nichtverf]";
CM_ SG_ 783 SWA_rel_Error "[DE: SWA_rel_Fehler]";
CM_ SG_ 783 SWA_Status_Active "[DE: SWA_Sta_aktiv]";
CM_ SG_ 783 SWA_Status_Passive "[DE: SWA_Sta_passiv]";
CM_ SG_ 783 SWA_StationaryTargets_Left "[DE: SWA_Standziele_li]";
CM_ SG_ 783 SWA_Queue_Left "[DE: SWA_Kolonne_li]";
CM_ SG_ 783 SWA_InfoLevel_SWA_Left "[DE: SWA_Infostufe_SWA_li]";
CM_ SG_ 783 SWA_Warning_SWA_Left "[DE: SWA_Warnung_SWA_li]";
CM_ SG_ 783 SWA_Queue_mi "[DE: SWA_Kolonne_mi]";
CM_ SG_ 783 SWA_StationaryTargets_Right "[DE: SWA_Standziele_re]";
CM_ SG_ 783 SWA_Queue_Right "[DE: SWA_Kolonne_re]";
CM_ SG_ 783 SWA_InfoLevel_SWA_Right "[DE: SWA_Infostufe_SWA_re]";
CM_ SG_ 783 SWA_Warning_SWA_Right "[DE: SWA_Warnung_SWA_re]";
CM_ SG_ 783 SWA_KD_Error "[DE: SWA_KD_Fehler]";
CM_ SG_ 1413 SI_CAN_Comfort_Sleep "[DE: SI_CAN_Komfort_Sleep]";
CM_ SG_ 1413 SI_CAN_Drive_Sleep "[DE: SI_CAN_Antrieb_Sleep]";
CM_ SG_ 1413 SI_Chassis_Sleep "[DE: SI_Fahrwerk_Sleep]";
CM_ SG_ 1413 SI_Diagnostics_Active "[DE: SI_Diagnose_Aktiv]";
CM_ SG_ 1413 SI_NWDF_Valid "[DE: SI_NWDF_gueltig]";
CM_ SG_ 1413 SI_GeneralFault "[DE: SI_Sammelfehler]";
CM_ SG_ 1413 GW_KD_Error "[DE: GW_KD_Fehler]";
CM_ SG_ 1413 SI_Collective_ECU_Error "[DE: SI_Sammel_SG_Fehler]";
CM_ SG_ 786 FAS_SetSpeed "[DE: FAS_Wunschgeschw]";
CM_ SG_ 786 FAS_Status_Prim_Disp "[DE: FAS_Status_Prim_Anz]";
CM_ SG_ 786 FAS_Texte_PrimaryDisplay "[DE: FAS_Texte_Primaeranz]";
CM_ SG_ 786 FAS_Status_Display "[DE: FAS_Status_Anzeige]";
CM_ SG_ 270 TSK_Allowed_ControlDeviation "[DE: TSK_zul_Regelabw]";
CM_ SG_ 270 TSK_ax_Gearbox "[DE: TSK_ax_Getriebe]";
CM_ SG_ 270 TSK_Request_Ratio "[DE: TSK_Wunsch_Uebersetz]";
CM_ SG_ 270 TSK_Enable_WU "[DE: TSK_Freig_WU]";
CM_ SG_ 270 TSK_Limiter_Active "[DE: TSK_Limiter_aktiv]";
CM_ SG_ 273 TSK_QBit_Gradient "[DE: TSK_QBit_Steigung]";
CM_ SG_ 273 TSK_VehicleMass "[DE: TSK_Fahrzeugmasse]";
CM_ SG_ 273 TSK_QBit_VehicleMass "[DE: TSK_QBit_Fahrzeugmasse]";
CM_ SG_ 273 TSK_VehicleMass_02 "[DE: TSK_Fahrzeugmasse_02]";
CM_ SG_ 273 TSK_Gradient "[DE: TSK_Steigung]";
CM_ SG_ 273 TSK_GearboxInfo "[DE: TSK_Getriebeinfo]";
CM_ SG_ 273 TSK_Coding_ACC "[DE: TSK_Codierung_ACC]";
CM_ SG_ 273 TSK_Enable_Decel_Req "[DE: TSK_Freig_Verzoeg_Anf]";
CM_ SG_ 273 TSK_Decel_Req_02 "[DE: TSK_Verzoeg_Anf_02]";
CM_ SG_ 1716 KS_Secret_1 "[DE: KS_Geheimnis_1]";
CM_ SG_ 1716 KS_Secret_2 "[DE: KS_Geheimnis_2]";
CM_ SG_ 1716 KS_Secret_3 "[DE: KS_Geheimnis_3]";
CM_ SG_ 1716 KS_Secret_4 "[DE: KS_Geheimnis_4]";
CM_ SG_ 1414 WH_KD_Error "[DE: WH_KD_Fehler]";
CM_ SG_ 1318 INVERTED_Indicator_ACTIVE "[DE: INVERTED_BLINKER_ACTIVE]";
CM_ SG_ 1318 Indicator_LEFT "[DE: BLINKER_LEFT]";
CM_ SG_ 1318 Indicator_RIGHT "[DE: BLINKER_RIGHT]";
CM_ BO_ 128 "[DE: Motor_01]";
CM_ BO_ 129 "[DE: Motor_02]";
CM_ BO_ 261 "[DE: Motor_03]";
CM_ BO_ 263 "[DE: Motor_04]";
CM_ BO_ 782 "[DE: Motor_05]";
CM_ BO_ 1088 "[DE: Motor_06]";
CM_ BO_ 1600 "[DE: Motor_07]";
CM_ BO_ 1607 "[DE: Motor_09]";
CM_ BO_ 276 "[DE: Motor_10]";
CM_ BO_ 1648 "[DE: Motor_18]";
CM_ BO_ 1010 "[DE: Motor_19]";
CM_ BO_ 1601 "[DE: Motor_Code_01]";
CM_ BO_ 969 "[DE: MotorSlave_01]";
CM_ BO_ 1730 "[DE: NMH_Getriebe]";
CM_ BO_ 1729 "[DE: NMH_Motor]";
CM_ BO_ 1736 "[DE: NMH_Motor_Slave]";
CM_ BO_ 1172 "[DE: STS_01]";
CM_ BO_ 1413 "[DE: Systeminfo_01]";
CM_ BO_ 1414 "[DE: Waehlhebel_02]";
